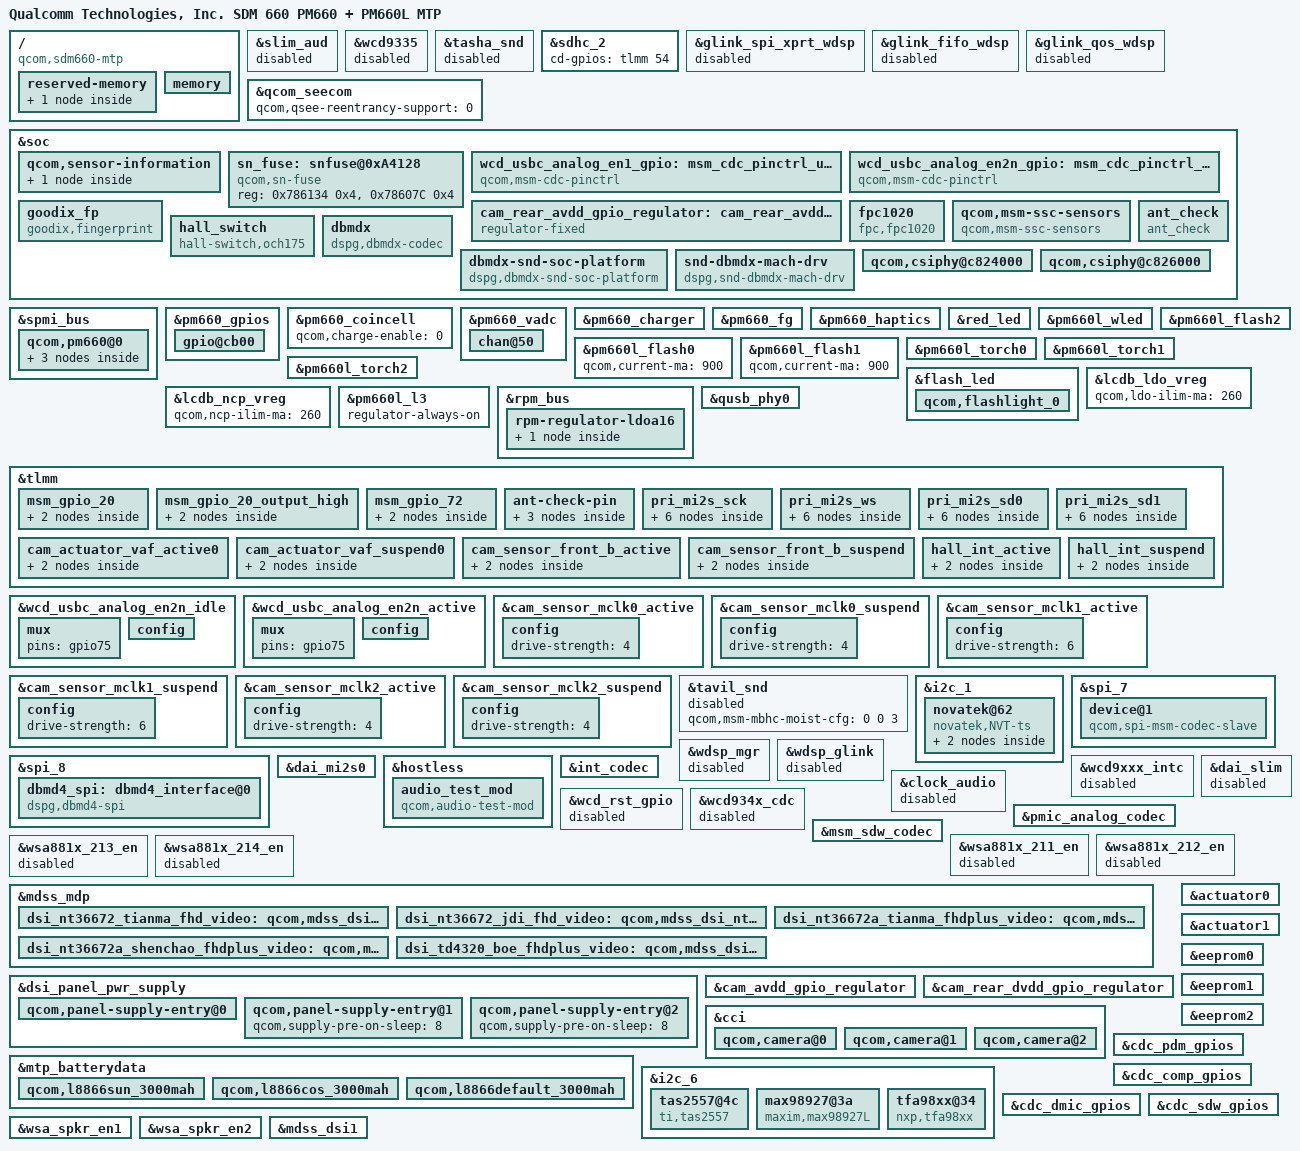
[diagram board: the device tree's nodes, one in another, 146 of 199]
/dts-v1/;

#include "sdm660.dtsi"
#include "sdm660-mtp.dtsi"
#include "sdm660-external-codec.dtsi"

/ {
	model = "Qualcomm Technologies, Inc. SDM 660 PM660 + PM660L MTP";
	compatible = "qcom,sdm660-mtp", "qcom,sdm660", "qcom,mtp";
	qcom,board-id = <8 0>;
	qcom,pmic-id = <0x0001001b 0x0101011a 0x0 0x0>,
			<0x0001001b 0x0201011a 0x0 0x0>,
			<0x0001001b 0x0102001a 0x0 0x0>;
	reserved-memory {
		pstore_reserve_mem: pstore_reserve_mem_region@0 {
			linux,reserve-contiguous-region;
			linux,reserve-region;
			linux,remove-completely;
			reg = <0x0 0xA0000000 0x0 0x00400000>;
			label = "pstore_reserve_mem";
		};
	};
	memory {
		device_type = "memory";
		reg = <0 0x80000000 0 0x80000000 1 0 0 0x7e4c0000>;
	};
};
&slim_aud {
	status = "disabled";
};
&wcd9335 {
	status = "disabled";
};
&tasha_snd {
	status = "disabled";
};
&sdhc_2 {
	cd-gpios = <&tlmm 54 0x0>;
};
&glink_spi_xprt_wdsp {
	status = "disabled";
};
&glink_fifo_wdsp {
	status = "disabled";
};
&glink_qos_wdsp {
	status = "disabled";
};
&qcom_seecom {
	qcom,qsee-reentrancy-support = <0>;
};
&soc {
	qcom,sensor-information {
		sensor_information22: qcom,sensor-information-22 {
			qcom,sensor-type = "adc";
			qcom,sensor-name = "backlight_therm";
		};
	};
	sn_fuse: snfuse@0xA4128 {
		compatible = "qcom,sn-fuse";
		reg = <0x786134 0x4>, <0x78607C 0x4>;
		reg-names = "sn-base","fuse-state";
	};
	wcd_usbc_analog_en1_gpio: msm_cdc_pinctrl_usbc_audio_en1 {
		compatible = "qcom,msm-cdc-pinctrl";
		pinctrl-names = "aud_active", "aud_sleep";
		pinctrl-0 = <&wcd_usbc_analog_en1_active>;
		pinctrl-1 = <&wcd_usbc_analog_en1_idle>;
	};
	wcd_usbc_analog_en2n_gpio: msm_cdc_pinctrl_usbc_audio_en2 {
		compatible = "qcom,msm-cdc-pinctrl";
		pinctrl-names = "aud_active", "aud_sleep";
		pinctrl-0 = <&wcd_usbc_analog_en2n_active>;
		pinctrl-1 = <&wcd_usbc_analog_en2n_idle>;
	};
	cam_rear_avdd_gpio_regulator: cam_rear_avdd_fixed_regulator {
		compatible = "regulator-fixed";
		regulator-name = "cam_rear_avdd_gpio_regulator";
		regulator-min-microvolt = <2800000>;
		regulator-max-microvolt = <2800000>;
		enable-active-high;
		gpio = <&tlmm 46 0>;
		vin-supply = <&pm660l_bob>;
	};
	goodix_fp {
		compatible = "goodix,fingerprint";
		interrupt-parent = <&tlmm>;
		interrupt = <72 0x0>;
		vcc_spi-supply = <&pm660l_l3>;
		vcc_ana-supply = <&pm660l_l3>;
		vdd_io-supply = <&pm660l_l3>;
		fp-gpio-irq = <&tlmm 72 0x00>;
		fp-gpio-reset = <&tlmm 20 0x00>;
		status = "okay";
	};
	fpc1020 {
		status = "ok";
		compatible = "fpc,fpc1020";
		interrupt-parent = <&tlmm>;
		interrupts = <72 0x0>;
		fpc,gpio_rst = <&tlmm 20 0x0>;
		fpc,gpio_irq = <&tlmm 72 0x0>;
		vcc_spi-supply = <&pm660_l13>;
		vdd_io-supply = <&pm660_l13>;
		vdd_ana-supply = <&pm660_l13>;
		pinctrl-names = "fpc1020_reset_reset", "fpc1020_reset_active", "fpc1020_irq_active";
		pinctrl-0 = <&msm_gpio_20>;
		pinctrl-1 = <&msm_gpio_20_output_high>;
		pinctrl-2 = <&msm_gpio_72>;
	};
	qcom,msm-ssc-sensors {
		compatible = "qcom,msm-ssc-sensors";
	};
	ant_check {
		compatible = "ant_check";
		ant_check_gpio = <&tlmm 74 0x0>;
		pinctrl-names = "default";
		pinctrl-0 = <&ant_check_default>;
	};
	hall_switch {
		compatible = "hall-switch,och175";
		pinctrl-names = "hall_active","hall_suspend";
		pinctrl-0 = <&hall_int_active>;
		pinctrl-1 = <&hall_int_suspend>;
		vdd-io-supply = <&pm660_l8>;
		interrupt-names = "hall_irq";
		hall,irq-gpio = <&tlmm 76 0x0>;
	};
	dbmdx {
		compatible = "dspg,dbmdx-codec";
		status = "okay";
		sv-gpio = <&tlmm 65 0>;
		wakeup-gpio = <&tlmm 0 0>;
		reset-gpio = <&tlmm 63 0>;		
		auto_buffering = <1>;
		multi-interface-support = <1>;
		cd-interfaces = <&dbmd4_spi >;
		va-interfaces = <0 0 0 0>;
		feature-va;
		va-firmware-name = "dbmd4_va_fw.bin";
		va-config = <0x80000000 0x80000000 0x80290020 0x80330019 0x802210e4 0x80158E8E 0x801b0020 0x80230001 0x801A0017 0x80103015 0x80000000 0x80000000 0x80000000>;
		va-speeds = <0x0000 460800 0 960000 0x0000 2000000 0 4800000 0x0000 3000000 0 4800000>;
		va-mic-config = <0xf041 0x1044 0x0008>;
		va-mic-mode = <4>;
		master-clk-rate = <32768>;
		firmware_id = <0xdbd4>;
		use_gpio_for_wakeup = <1>;
		wakeup_set_value = <0>;
		auto_detection = <1>;
		detection_buffer_channels = <0>;
		min_samples_chunk_size = <128>;
		pcm_streaming_mode = <1>;
		boot_options = <0x200>;
		amodel_options = <0x4>;
		send_uevent_on_detection = <1>;
		send_uevent_after_buffering = <0>;
		detection_after_buffering = <0>;
		va_backlog_length = <0x7d0>;
	};
	dbmdx-snd-soc-platform {
		compatible = "dspg,dbmdx-snd-soc-platform";
	};
	snd-dbmdx-mach-drv {
		compatible = "dspg,snd-dbmdx-mach-drv";
	};
	/delete-node/ qcom,qbt1000;
	/delete-node/ cam_actuator_fixed_regulator;
};
&spmi_bus {
	qcom,pm660@0 {
		qcom,power-on@800 {
			qcom,pon_1 {
				qcom,support-reset = <1>;
				qcom,s1-timer = <4480>;
				qcom,s2-timer = <2000>;
				qcom,s2-type = <7>;
			};
		};
	};
};
&spmi_bus {
	qcom,pm660@0 {
		qcom,power-on@800 {
			qcom,pon_3 {
				qcom,pon-type = <3>;
				qcom,pull-up = <1>;
				qcom,support-reset = <1>;
				qcom,s1-timer = <4480>;
				qcom,s2-timer = <1000>;
				qcom,s2-type = <1>;
			};
		};
	};
};
&pm660_gpios {
	gpio@cb00 {
		status = "ok";
		qcom,mode = <1>;
		qcom,pull = <5>;
		qcom,vin-sel = <0>;
		qcom,src-sel = <2>;
		qcom,invert = <0>;
		qcom,master-en = <1>;
	};
};
&pm660_coincell {
	qcom,charge-enable = <0>;
};
&pm660_vadc {
	chan@50 {
		label = "backlight_therm";
		reg = <0x50>;
		qcom,decimation = <2>;
		qcom,pre-div-channel-scaling = <0>;
		qcom,calibration-type = "ratiometric";
		qcom,scale-function = <2>;
		qcom,hw-settle-time = <2>;
		qcom,fast-avg-setup = <0>;
		qcom,vadc-thermal-node;
	};
};
&pm660_charger {
	qcom,usb-icl-ua = <2900000>;
	qcom,otg-cl-ua = <1500000>;
	qcom,dc-icl-ua = <2900000>;
	qcom,fcc-max-ua = <2900000>;
	qcom,fv-max-uv = <4400000>;
	qcom,sw-jeita-enable;
	qcom,thermal-mitigation = <2900000 2000000 1800000 1500000 1000000 500000 100000>;
};
&pm660_fg {
	qcom,fg-cutoff-voltage = <3400>;
	qcom,fg-chg-term-current = <200>;
	qcom,fg-sys-term-current = <300>;
	qcom,fg-recharge-voltage = <4340>;
	qcom,fg-jeita-thresholds = <0 15 45 60>;
	qcom,fg-jeita-hyst-temp = <0>;
};
&pm660_haptics {
	qcom,play-mode = "buffer";
	qcom,vmax-mv = <2204>;
	qcom,wave-shape = "sine";
	qcom,wave-play-rate-us = <4878>;
	qcom,int-pwm-freq-khz = <253>;
	qcom,brake-pattern = [02 02 01 00];
	qcom,wave-samples = [3e 3e 3e 00 00 00 00 00];
	qcom,wave-samples-two = [3e 3e 3e 3e 00 00 00 00];
	qcom,wave-samples-three = [3e 3e 3e 3e 3e 00 00 00];
	qcom,wave-rep-cnt = <1>;
	qcom,wave-samp-rep-cnt = <1>;
	qcom,lra-high-z = "opt1";
	qcom,lra-auto-res-mode = "none";
	qcom,lra-hw-auto-resonance;
	/delete-property/ qcom,correct-lra-drive-freq;
};
&red_led {
	qcom,ramp-step-ms = <128>;
	qcom,idx-len = <26>;
	qcom,duty-pcts = [3c 3c 3b 3a 3b 37 35 33 31 2e 2a 27 23 1f 1b 17 13 0e 09 05 00 00 00 00 00 00];
};
&pm660l_wled {
	qcom,fs-curr-ua = <20000>;
	qcom,led-strings-list = [00 01];
	qcom,en-cabc;
	/delete-property/ qcom,auto-calibration-enable;
};
&pm660l_flash0 {
	qcom,current-ma = <900>;
};
&pm660l_flash1 {
	qcom,current-ma = <900>;
};
&pm660l_flash2 {
	qcom,max-current = <100>;
	qcom,current-ma = <90>;
};
&pm660l_torch0 {
	qcom,max-current = <1000>;
	qcom,current-ma = <100>;
};
&pm660l_torch1 {
	qcom,max-current = <1000>;
	qcom,current-ma = <100>;
};
&pm660l_torch2 {
	qcom,max-current = <150>;
	qcom,current-ma = <90>;
};
&flash_led {
	qcom,flashlight_0 {
		label = "flashlight";
		qcom,led-name = "flashlight";
		qcom,torch-name = "led:torch_0", "led:torch_1";
		qcom,switch-name = "led:switch_0";
		qcom,id = <0>;
	};
};
&lcdb_ldo_vreg {
	qcom,ldo-ilim-ma = <260>;
};
&lcdb_ncp_vreg {
	qcom,ncp-ilim-ma = <260>;
};
&pm660l_l3 {
	regulator-always-on;
};
&rpm_bus {
	rpm-regulator-ldoa16 {
		status = "okay";
		pm660_l16: regulator-l16 {
			regulator-min-microvolt = <2800000>;
			regulator-max-microvolt = <2800000>;
			status = "okay";
			regulator-always-on;
		};
	};
};
&qusb_phy0 {
	qcom,qusb-phy-init-seq = <0xf8 0x80 0x33 0x84 0x83 0x88 0xc0 0x8c 0x30 0x08 0x79 0x0c 0x21 0x10 0x14 0x9c 0x9f 0x1c 0x00 0x18>;
};
&tlmm {
	msm_gpio_20: msm_gpio_20 {
		mux {
			pins = "gpio20";
			function = "gpio";
		};
		config {
			pins = "gpio20";
			drive-strength = <2>;
			bias-disable;
			output-low;
		};
	};
	msm_gpio_20_output_high: msm_gpio_20_output_high {
		mux {
			pins = "gpio20";
			function = "gpio";
		};
		config {
			pins = "gpio20";
			drive-strength = <2>;
			bias-disable;
			output-high;
		};
	};
	msm_gpio_72: msm_gpio_72 {
		mux {
			pins = "gpio72";
			function = "gpio";
		};
		config {
			pins = "gpio72";
			drive-strength = <2>;
			bias-pull-down;
		};
	};
	ant-check-pin {
		ant_check_default: ant_check_default {
			mux {
				pins = "gpio74";
				function = "gpio";
			};
			config {
				pins = "gpio74";
				drive-strength = <2>;
				bias-disable;
				input-enable;
				input-debounce = <5000>;
			};
		};
	};
	pri_mi2s_sck {
		pri_mi2s_sck_sleep: pri_mi2s_sck_sleep {
			mux {
				pins = "gpio12";
				function = "gpio";
			};
			config {
				pins = "gpio12";
				drive-strength = <2>;
				bias-pull-down;
				input-enable;
			};
		};
		pri_mi2s_sck_active: pri_mi2s_sck_active {
			mux {
				pins = "gpio12";
				function = "pri_mi2s";
			};
			config {
				pins = "gpio12";
				drive-strength = <8>;
				bias-disable;
				output-high;
			};
		};
	};
	pri_mi2s_ws {
		pri_mi2s_ws_sleep: pri_mi2s_ws_sleep {
			mux {
				pins = "gpio13";
				function = "gpio";
			};
			config {
				pins = "gpio13";
				drive-strength = <2>;
				bias-pull-down;
				input-enable;
			};
		};
		pri_mi2s_ws_active: pri_mi2s_ws_active {
			mux {
				pins = "gpio13";
				function = "pri_mi2s_ws";
			};
			config {
				pins = "gpio13";
				drive-strength = <8>;
				bias-disable;
				output-high;
			};
		};
	};
	pri_mi2s_sd0 {
		pri_mi2s_sd0_sleep: pri_mi2s_sd0_sleep {
			mux {
				pins = "gpio14";
				function = "gpio";
			};
			config {
				pins = "gpio14";
				drive-strength = <2>;
				bias-pull-down;
				input-enable;
			};
		};
		pri_mi2s_sd0_active: pri_mi2s_sd0_active {
			mux {
				pins = "gpio14";
				function = "pri_mi2s";
			};
			config {
				pins = "gpio14";
				drive-strength = <8>;
				bias-disable;
			};
		};
	};
	pri_mi2s_sd1 {
		pri_mi2s_sd1_sleep: pri_mi2s_sd1_sleep {
			mux {
				pins = "gpio15";
				function = "gpio";
			};
			config {
				pins = "gpio15";
				drive-strength = <2>;
				bias-pull-down;
				input-enable;
			};
		};
		pri_mi2s_sd1_active: pri_mi2s_sd1_active {
			mux {
				pins = "gpio15";
				function = "pri_mi2s";
			};
			config {
				pins = "gpio15";
				drive-strength = <8>;
				bias-disable;
			};
		};
	};
	cam_actuator_vaf_active0: cam_actuator_vaf_active0 {
		mux {
			pins = "gpio45";
			function = "gpio";
		};
		config {
			pins = "gpio45";
			bias-disable;
			drive-strength = <2>;
		};
	};
	cam_actuator_vaf_suspend0: cam_actuator_vaf_suspend0 {
		mux {
			pins = "gpio45";
			function = "gpio";
		};
		config {
			pins = "gpio45";
			bias-pull-down;
			drive-strength = <2>;
		};
	};
	cam_sensor_front_b_active: cam_sensor_front_b_active {
		mux {
			pins = "gpio52","gpio40";
			function = "gpio";
		};
		config {
			pins = "gpio52","gpio40";
			bias-disable;
			drive-strength = <2>;
		};
	};
	cam_sensor_front_b_suspend: cam_sensor_front_b_suspend {
		mux {
			pins = "gpio52","gpio40";
			function = "gpio";
		};
		config {
			pins = "gpio52","gpio40";
			bias-disable;
			drive-strength = <2>;
		};
	};
	hall_int_active: hall_int_active {
		mux {
			pins = "gpio76";
			function = "gpio";
		};
		config {
			pins = "gpio76";
			drive-strength = <6>;
			bias-pull-up;
		};
	};
	hall_int_suspend: hall_int_suspend {
		mux {
			pins = "gpio76";
			function = "gpio";
		};
		config {
			pins = "gpio76";
			drive-strength = <6>;
			bias-pull-up;
		};
	};
};
&wcd_usbc_analog_en2n_idle {
	mux {
		pins = "gpio75";
	};
};
&wcd_usbc_analog_en2n_idle {
	config {
		pins = "gpio75";
		output-low;
		/delete-property/ output-high;
	};
};
&wcd_usbc_analog_en2n_active {
	mux {
		pins = "gpio75";
	};
};
&wcd_usbc_analog_en2n_active {
	config {
		pins = "gpio75";
		bias-disable;
		output-high;
		/delete-property/ bias-pull-down;
		/delete-property/ output-low;
	};
};
&cam_sensor_mclk0_active {
	config {
		drive-strength = <4>;
	};
};
&cam_sensor_mclk0_suspend {
	config {
		drive-strength = <4>;
	};
};
&cam_sensor_mclk1_active {
	config {
		drive-strength = <6>;
	};
};
&cam_sensor_mclk1_suspend {
	config {
		drive-strength = <6>;
	};
};
&cam_sensor_mclk2_active {
	config {
		drive-strength = <4>;
	};
};
&cam_sensor_mclk2_suspend {
	config {
		drive-strength = <4>;
	};
};
&tavil_snd {
	qcom,msm-mbhc-moist-cfg = <0 0 3>;
};
&i2c_1 {
	status = "ok";
	novatek@62 {
		compatible = "novatek,NVT-ts";
		reg = <0x62>;
		interrupt-parent = <&tlmm>;
		interrupts = <67 0x2008>;
		vcc_i2c-supply = <&pm660_l11>;
		pinctrl-names = "pmx_ts_active", "pmx_ts_suspend";
		pinctrl-0 = <&ts_active>;
		pinctrl-1 = <&ts_int_suspend &ts_reset_suspend>;
		novatek,reset-gpio = <&tlmm 66 0x00>;
		novatek,irq-gpio = <&tlmm 67 0x2001>;
		novatek,mp-support-dt;
		novatek-mp-criteria-5906@0 {
			#address-cells = <1>;
			#size-cells = <0>;
			compatible = "novatek-mp-criteria-5906";
			IC_X_CFG_SIZE = <18>;
			IC_Y_CFG_SIZE = <32>;
			IC_KEY_CFG_SIZE = <4>;
			X_Channel = <18>;
			Y_Channel = <32>;
			AIN_X = <17 16 15 14 13 12 11 10 9 8 7 6 5 4 3 2 1 0>;
			AIN_Y = <31 30 29 28 27 26 25 24 23 22 21 20 19 18 17 16 15 14 13 12 11 10 9 8 7 6 5 4 3 2 1 0>;
			AIN_KEY = <0 1 2 0xFF>;
			PS_Config_Lmt_Short_Rawdata_P = <14000>;
			PS_Config_Lmt_Short_Rawdata_N = <11000>;
			PS_Config_Lmt_Key_Short_Rawdata_P = <14000>;
			PS_Config_Lmt_Key_Short_Rawdata_N = <11000>;
			PS_Config_Lmt_Short_Diff_P = <6300>;
			PS_Config_Lmt_Short_Diff_N = <0>;
			PS_Config_Lmt_Key_Short_Diff_P = <6300>;
			PS_Config_Lmt_Key_Short_Diff_N = <0>;
			PS_Config_Lmt_Short_Base_P = <2000>;
			PS_Config_Lmt_Short_Base_N = <(-2000)>;
			PS_Config_Lmt_Key_Short_Base_P = <2000>;
			PS_Config_Lmt_Key_Short_Base_N = <(-2000)>;
			PS_Config_Lmt_Open_Rawdata_P = < 7345 7376 7389 7403 7418 7442 7453 7432 7406 7365 7395 7412 7435 7452 7435 7420 7406 7392 7342 7378 7393 7407 7425 7450 7458 7436 7407 7365 7393 7412 7437 7450 7433 7418 7402 7380 7331 7365 7379 7394 7411 7438 7442 7420 7392 7377 7405 7425 7451 7462 7445 7428 7412 7387 7333 7371 7387 7402 7420 7446 7448 7426 7397 7362 7389 7408 7434 7444 7425 7409 7393 7367 7346 7385 7404 7420 7438 7464 7465 7442 7413 7379 7406 7427 7453 7459 7441 7425 7408 7376 7334 7370 7390 7405 7423 7451 7447 7425 7395 7389 7417 7438 7466 7469 7450 7434 7417 7382 7343 7380 7404 7420 7438 7466 7460 7437 7407 7381 7408 7429 7455 7458 7438 7422 7403 7367 7351 7387 7413 7429 7448 7477 7467 7444 7413 7384 7412 7433 7460 7458 7440 7424 7403 7366 7343 7377 7407 7424 7442 7470 7459 7435 7406 7408 7437 7459 7488 7483 7464 7447 7420 7381 7351 7386 7417 7437 7456 7486 7470 7446 7416 7394 7423 7443 7472 7467 7446 7429 7399 7363 7360 7396 7429 7452 7470 7502 7483 7459 7427 7412 7441 7464 7493 7482 7463 7444 7412 7374 7348 7384 7416 7440 7460 7489 7466 7444 7413 7422 7453 7475 7506 7492 7473 7450 7416 7378 7358 7396 7428 7458 7478 7509 7484 7459 7428 7417 7447 7470 7500 7486 7464 7437 7404 7366 7372 7410 7443 7477 7497 7528 7500 7474 7441 7428 7459 7483 7515 7495 7474 7443 7410 7371 7359 7397 7430 7463 7489 7515 7486 7461 7429 7451 7484 7509 7542 7517 7494 7459 7425 7385 7373 7411 7445 7480 7507 7534 7503 7477 7443 7440 7472 7497 7530 7505 7476 7442 7408 7369 7387 7427 7462 7499 7530 7556 7524 7496 7461 7462 7495 7522 7554 7525 7493 7457 7422 7381 7369 7407 7441 7476 7516 7553 7525 7497 7462 7493 7530 7559 7582 7533 7495 7459 7423 7382 7385 7425 7461 7497 7538 7574 7550 7520 7483 7493 7530 7559 7576 7529 7488 7452 7417 7375 7403 7445 7482 7522 7564 7599 7577 7544 7505 7514 7553 7585 7594 7543 7502 7464 7427 7384 7400 7441 7478 7517 7562 7591 7572 7540 7502 7548 7590 7621 7627 7573 7531 7489 7450 7406 7421 7464 7504 7546 7592 7621 7600 7569 7526 7545 7587 7613 7615 7564 7519 7479 7440 7395 7444 7490 7531 7575 7623 7650 7630 7598 7553 7577 7621 7647 7646 7589 7544 7502 7461 7413 7442 7489 7531 7575 7626 7647 7626 7598 7553 7615 7664 7686 7682 7621 7572 7527 7485 7435 7469 7518 7563 7611 7664 7684 7661 7636 7587 7624 7668 7690 7681 7620 7570 7525 7483 7432 7501 7554 7602 7653 7711 7729 7702 7678 7625 7664 7706 7731 7717 7653 7599 7552 7507 7452 7496 7549 7597 7650 7710 7721 7694 7671 7622 7714 7756 7784 7764 7694 7637 7586 7538 7479 7325 7362 7392 7425 7461 7466 7454 7445 7416 7453 7471 7481 7460 7418 7384 7354 7325 7285 7379 7422 7458 7497 7541 7545 7529 7516 7485 7527 7549 7564 7540 7490 7450 7414 7380 7334 7419 7467 7508 7552 7604 7604 7583 7568 7537 7612 7641 7662 7633 7573 7526 7483 7444 7391 7492 7549 7597 7652 7714 7714 7686 7665 7630 7678 7712 7738 7706 7636 7582 7534 7490 7432 7652 7728 7798 7877 7968 7965 7917 7879 7823 7890 7941 7985 7944 7848 7770 7702 7641 7558>;
			PS_Config_Lmt_Open_Rawdata_N = < 6834 6852 6860 6867 6876 6890 6896 6884 6869 6846 6863 6873 6886 6896 6886 6878 6869 6861 6833 6853 6862 6870 6880 6895 6900 6887 6870 6846 6862 6873 6887 6895 6885 6876 6867 6854 6826 6846 6854 6863 6872 6888 6890 6878 6861 6853 6869 6880 6895 6902 6892 6882 6873 6858 6828 6849 6858 6867 6877 6892 6894 6881 6864 6844 6860 6871 6885 6891 6880 6871 6862 6847 6835 6858 6868 6878 6888 6903 6903 6890 6873 6854 6870 6881 6897 6900 6890 6880 6870 6852 6828 6848 6860 6869 6879 6895 6893 6880 6863 6859 6876 6888 6904 6905 6895 6886 6875 6855 6833 6854 6868 6878 6888 6904 6900 6887 6870 6855 6871 6882 6898 6899 6888 6879 6868 6847 6838 6858 6874 6883 6894 6910 6905 6891 6874 6857 6873 6885 6901 6899 6889 6880 6868 6847 6833 6853 6870 6880 6890 6906 6900 6886 6869 6871 6887 6900 6916 6913 6903 6893 6877 6855 6838 6858 6876 6887 6898 6915 6906 6892 6875 6863 6879 6891 6907 6904 6892 6883 6866 6845 6843 6864 6882 6896 6906 6924 6914 6900 6882 6873 6890 6902 6919 6913 6902 6891 6873 6851 6836 6857 6875 6889 6901 6917 6904 6891 6874 6879 6896 6909 6927 6919 6908 6895 6875 6853 6842 6863 6882 6899 6911 6929 6914 6900 6882 6876 6893 6906 6924 6915 6903 6887 6868 6847 6850 6872 6891 6910 6921 6939 6923 6909 6890 6882 6900 6914 6932 6921 6909 6891 6871 6849 6843 6864 6883 6902 6917 6932 6916 6901 6883 6895 6914 6929 6948 6933 6920 6900 6880 6857 6850 6872 6892 6912 6928 6943 6925 6910 6891 6889 6907 6922 6941 6926 6910 6890 6871 6848 6859 6882 6902 6923 6941 6955 6937 6921 6901 6901 6921 6936 6955 6938 6920 6899 6879 6855 6848 6870 6889 6910 6933 6954 6938 6922 6902 6919 6940 6957 6971 6943 6920 6900 6879 6855 6858 6880 6901 6922 6945 6966 6952 6935 6914 6920 6941 6958 6967 6940 6917 6896 6875 6852 6868 6892 6913 6936 6960 6981 6967 6949 6926 6931 6954 6972 6978 6948 6925 6903 6882 6857 6866 6890 6911 6933 6959 6976 6965 6947 6925 6951 6975 6993 6997 6965 6941 6917 6895 6869 6878 6903 6926 6950 6976 6993 6981 6963 6939 6949 6974 6988 6990 6960 6934 6912 6889 6863 6891 6917 6941 6967 6994 7010 6998 6980 6954 6967 6993 7008 7007 6975 6949 6924 6901 6873 6890 6917 6941 6966 6996 7008 6996 6980 6954 6990 7017 7030 7028 6993 6965 6939 6915 6886 6905 6934 6959 6987 7018 7029 7016 7002 6974 6995 7020 7033 7027 6992 6964 6938 6914 6884 6924 6954 6982 7012 7045 7055 7039 7026 6995 7018 7042 7056 7048 7011 6981 6953 6927 6896 6921 6952 6979 7009 7044 7050 7035 7022 6994 7046 7070 7087 7075 7035 7002 6973 6945 6911 6823 6844 6862 6880 6901 6904 6897 6892 6875 6896 6907 6912 6900 6876 6857 6840 6823 6800 6854 6879 6899 6922 6947 6949 6940 6932 6915 6939 6952 6960 6946 6918 6895 6874 6855 6828 6877 6905 6928 6953 6983 6983 6971 6962 6944 6988 7005 7016 7000 6965 6938 6914 6891 6861 6919 6951 6979 7011 7046 7046 7031 7018 6998 7026 7045 7060 7042 7002 6971 6943 6917 6884 7011 7055 7095 7140 7192 7191 7163 7141 7109 7148 7177 7202 7178 7123 7079 7040 7004 6957>;
			PS_Config_Lmt_FW_Rawdata_P = < 1300 1300 1300 1300 1300 1300 1300 1300 1300 1300 1300 1300 1300 1300 1300 1300 1300 1300 1300 1300 1300 1300 1300 1300 1300 1300 1300 1300 1300 1300 1300 1300 1300 1300 1300 1300 1300 1300 1300 1300 1300 1300 1300 1300 1300 1300 1300 1300 1300 1300 1300 1300 1300 1300 1300 1300 1300 1300 1300 1300 1300 1300 1300 1300 1300 1300 1300 1300 1300 1300 1300 1300 1300 1300 1300 1300 1300 1300 1300 1300 1300 1300 1300 1300 1300 1300 1300 1300 1300 1300 1300 1300 1300 1300 1300 1300 1300 1300 1300 1300 1300 1300 1300 1300 1300 1300 1300 1300 1300 1300 1300 1300 1300 1300 1300 1300 1300 1300 1300 1300 1300 1300 1300 1300 1300 1300 1300 1300 1300 1300 1300 1300 1300 1300 1300 1300 1300 1300 1300 1300 1300 1300 1300 1300 1300 1300 1300 1300 1300 1300 1300 1300 1300 1300 1300 1300 1300 1300 1300 1300 1300 1300 1300 1300 1300 1300 1300 1300 1300 1300 1300 1300 1300 1300 1300 1300 1300 1300 1300 1300 1300 1300 1300 1300 1300 1300 1300 1300 1300 1300 1300 1300 1300 1300 1300 1300 1300 1300 1300 1300 1300 1300 1300 1300 1300 1300 1300 1300 1300 1300 1300 1300 1300 1300 1300 1300 1300 1300 1300 1300 1300 1300 1300 1300 1300 1300 1300 1300 1300 1300 1300 1300 1300 1300 1300 1300 1300 1300 1300 1300 1300 1300 1300 1300 1300 1300 1300 1300 1300 1300 1300 1300 1300 1300 1300 1300 1300 1300 1300 1300 1300 1300 1300 1300 1300 1300 1300 1300 1300 1300 1300 1300 1300 1300 1300 1300 1300 1300 1300 1300 1300 1300 1300 1300 1300 1300 1300 1300 1300 1300 1300 1300 1300 1300 1300 1300 1300 1300 1300 1300 1300 1300 1300 1300 1300 1300 1300 1300 1300 1300 1300 1300 1300 1300 1300 1300 1300 1300 1300 1300 1300 1300 1300 1300 1300 1300 1300 1300 1300 1300 1300 1300 1300 1300 1300 1300 1300 1300 1300 1300 1300 1300 1300 1300 1300 1300 1300 1300 1300 1300 1300 1300 1300 1300 1300 1300 1300 1300 1300 1300 1300 1300 1300 1300 1300 1300 1300 1300 1300 1300 1300 1300 1300 1300 1300 1300 1300 1300 1300 1300 1300 1300 1300 1300 1300 1300 1300 1300 1300 1300 1300 1300 1300 1300 1300 1300 1300 1300 1300 1300 1300 1300 1300 1300 1300 1300 1300 1300 1300 1300 1300 1300 1300 1300 1300 1300 1300 1300 1300 1300 1300 1300 1300 1300 1300 1300 1300 1300 1300 1300 1300 1300 1300 1300 1300 1300 1300 1300 1300 1300 1300 1300 1300 1300 1300 1300 1300 1300 1300 1300 1300 1300 1300 1300 1300 1300 1300 1300 1300 1300 1300 1300 1300 1300 1300 1300 1300 1300 1300 1300 1300 1300 1300 1300 1300 1300 1300 1300 1300 1300 1300 1300 1300 1300 1300 1300 1300 1300 1300 1300 1300 1300 1300 1300 1300 1300 1300 1300 1300 1300 1300 1300 1300 1300 1300 1300 1300 1300 1300 1300 1300 1300 1300 1300 1300 1300 1300 1300 1300 1300 1300 1300 1300 1300 1300 1300 1300 1300 1300 1300 1300 1300 1300 1300 1300 1300 1300 1300 1300 1300 1300 1300 1300 1300 1300 1300 1300 1300 1300 1300 1300 1300 1300 1300 1300 1300 1300 1300 1300 1300 1300 1300 1300 1300 1300 1300 1300 1300 1300 1300 1300 1300 1300 1300 1300 1300>;
			PS_Config_Lmt_FW_Rawdata_N = < 500 500 500 500 500 500 500 500 500 500 500 500 500 500 500 500 500 500 500 500 500 500 500 500 500 500 500 500 500 500 500 500 500 500 500 500 500 500 500 500 500 500 500 500 500 500 500 500 500 500 500 500 500 500 500 500 500 500 500 500 500 500 500 500 500 500 500 500 500 500 500 500 500 500 500 500 500 500 500 500 500 500 500 500 500 500 500 500 500 500 500 500 500 500 500 500 500 500 500 500 500 500 500 500 500 500 500 500 500 500 500 500 500 500 500 500 500 500 500 500 500 500 500 500 500 500 500 500 500 500 500 500 500 500 500 500 500 500 500 500 500 500 500 500 500 500 500 500 500 500 500 500 500 500 500 500 500 500 500 500 500 500 500 500 500 500 500 500 500 500 500 500 500 500 500 500 500 500 500 500 500 500 500 500 500 500 500 500 500 500 500 500 500 500 500 500 500 500 500 500 500 500 500 500 500 500 500 500 500 500 500 500 500 500 500 500 500 500 500 500 500 500 500 500 500 500 500 500 500 500 500 500 500 500 500 500 500 500 500 500 500 500 500 500 500 500 500 500 500 500 500 500 500 500 500 500 500 500 500 500 500 500 500 500 500 500 500 500 500 500 500 500 500 500 500 500 500 500 500 500 500 500 500 500 500 500 500 500 500 500 500 500 500 500 500 500 500 500 500 500 500 500 500 500 500 500 500 500 500 500 500 500 500 500 500 500 500 500 500 500 500 500 500 500 500 500 500 500 500 500 500 500 500 500 500 500 500 500 500 500 500 500 500 500 500 500 500 500 500 500 500 500 500 500 500 500 500 500 500 500 500 500 500 500 500 500 500 500 500 500 500 500 500 500 500 500 500 500 500 500 500 500 500 500 500 500 500 500 500 500 500 500 500 500 500 500 500 500 500 500 500 500 500 500 500 500 500 500 500 500 500 500 500 500 500 500 500 500 500 500 500 500 500 500 500 500 500 500 500 500 500 500 500 500 500 500 500 500 500 500 500 500 500 500 500 500 500 500 500 500 500 500 500 500 500 500 500 500 500 500 500 500 500 500 500 500 500 500 500 500 500 500 500 500 500 500 500 500 500 500 500 500 500 500 500 500 500 500 500 500 500 500 500 500 500 500 500 500 500 500 500 500 500 500 500 500 500 500 500 500 500 500 500 500 500 500 500 500 500 500 500 500 500 500 500 500 500 500 500 500 500 500 500 500 500 500 500 500 500 500 500 500 500 500 500 500 500 500 500 500 500 500 500 500 500 500 500 500 500 500 500 500 500 500 500 500 500 500 500 500 500 500 500 500 500 500>;
			PS_Config_Lmt_FW_CC_P = <132>;
			PS_Config_Lmt_FW_CC_N = <74>;
			PS_Config_Lmt_Key_FW_CC_P = <38>;
			PS_Config_Lmt_Key_FW_CC_N = <9>;
			PS_Config_Lmt_FW_CC_I_P = <25>;
			PS_Config_Lmt_FW_CC_I_N = <0>;
			PS_Config_Lmt_FW_CC_Q_P = <25>;
			PS_Config_Lmt_FW_CC_Q_N = <0>;
			PS_Config_Lmt_Key_FW_CC_I_P = <25>;
			PS_Config_Lmt_Key_FW_CC_I_N = <0>;
			PS_Config_Lmt_Key_FW_CC_Q_P = <25>;
			PS_Config_Lmt_Key_FW_CC_Q_N = <0>;
			PS_Config_Lmt_FW_Diff_P = <35>;
			PS_Config_Lmt_FW_Diff_N = <(-35)>;
			PS_Config_Lmt_Key_FW_Diff_P = <35>;
			PS_Config_Lmt_Key_FW_Diff_N = <(-35)>;
			PS_Config_Diff_Test_Frame = <50>;
		};
		novatek-mp-criteria-5909@1 {
			#address-cells = <1>;
			#size-cells = <0>;
			compatible = "novatek-mp-criteria-5909";
			IC_X_CFG_SIZE = <18>;
			IC_Y_CFG_SIZE = <32>;
			IC_KEY_CFG_SIZE = <4>;
			X_Channel = <18>;
			Y_Channel = <32>;
			AIN_X = <17 16 15 14 13 12 11 10 9 8 7 6 5 4 3 2 1 0>;
			AIN_Y = <31 30 29 28 27 26 25 24 23 22 21 20 19 18 17 16 15 14 13 12 11 10 9 8 7 6 5 4 3 2 1 0>;
			AIN_KEY = <0 1 2 0xFF>;
			PS_Config_Lmt_Short_Rawdata_P = <14000>;
			PS_Config_Lmt_Short_Rawdata_N = <11000>;
			PS_Config_Lmt_Key_Short_Rawdata_P = <14000>;
			PS_Config_Lmt_Key_Short_Rawdata_N = <11000>;
			PS_Config_Lmt_Short_Diff_P = <6300>;
			PS_Config_Lmt_Short_Diff_N = <0>;
			PS_Config_Lmt_Key_Short_Diff_P = <6300>;
			PS_Config_Lmt_Key_Short_Diff_N = <0>;
			PS_Config_Lmt_Short_Base_P = <2000>;
			PS_Config_Lmt_Short_Base_N = <(-2000)>;
			PS_Config_Lmt_Key_Short_Base_P = <2000>;
			PS_Config_Lmt_Key_Short_Base_N = <(-2000)>;
			PS_Config_Lmt_Open_Rawdata_P = < 9032 9105 9084 9055 9049 9011 9030 9044 9078 9024 9036 9019 8992 8985 8995 9014 9018 9045 8898 8951 8933 8904 8903 8864 8886 8896 8929 8874 8877 8863 8838 8831 8839 8854 8852 8871 8864 8894 8879 8855 8857 8834 8844 8853 8885 8810 8810 8796 8774 8766 8776 8785 8784 8803 8855 8896 8879 8858 8863 8834 8853 8864 8896 8848 8846 8834 8809 8812 8812 8817 8817 8818 8809 8857 8828 8809 8813 8783 8805 8816 8847 8794 8791 8779 8754 8750 8755 8760 8768 8756 8838 8875 8847 8830 8836 8816 8832 8842 8871 8806 8800 8792 8766 8761 8768 8768 8780 8769 8785 8823 8792 8781 8787 8766 8783 8796 8824 8775 8769 8758 8733 8741 8739 8738 8747 8736 8793 8817 8796 8784 8789 8771 8788 8801 8830 8783 8776 8764 8740 8739 8742 8741 8741 8736 8758 8775 8770 8748 8754 8739 8755 8766 8795 8725 8719 8708 8683 8680 8683 8695 8680 8680 8761 8775 8771 8749 8758 8743 8761 8774 8801 8758 8749 8737 8713 8722 8715 8727 8711 8713 8711 8722 8717 8697 8700 8692 8709 8721 8748 8696 8686 8676 8652 8654 8652 8664 8649 8649 8729 8734 8726 8712 8725 8709 8726 8739 8764 8702 8690 8678 8656 8655 8654 8662 8653 8653 8661 8665 8648 8652 8652 8645 8663 8675 8695 8657 8643 8635 8611 8625 8618 8612 8612 8612 8657 8661 8646 8654 8645 8641 8660 8671 8686 8650 8637 8627 8604 8608 8615 8603 8606 8601 8607 8609 8597 8605 8608 8591 8611 8622 8635 8586 8574 8565 8543 8544 8551 8535 8542 8536 8590 8592 8582 8591 8584 8580 8598 8609 8622 8592 8580 8569 8548 8563 8558 8543 8551 8544 8524 8530 8522 8519 8521 8521 8540 8550 8564 8521 8509 8498 8478 8485 8476 8475 8485 8478 8532 8536 8529 8527 8536 8537 8543 8553 8568 8522 8504 8493 8486 8478 8473 8473 8485 8476 8460 8465 8459 8459 8457 8457 8476 8486 8500 8477 8458 8449 8430 8445 8430 8429 8442 8433 8447 8453 8450 8449 8443 8446 8477 8476 8488 8458 8439 8441 8411 8418 8411 8412 8426 8412 8392 8396 8397 8398 8402 8394 8424 8423 8433 8392 8373 8374 8347 8352 8347 8348 8361 8345 8368 8374 8375 8376 8371 8373 8403 8401 8409 8391 8371 8375 8346 8362 8347 8351 8365 8345 8297 8305 8308 8309 8299 8304 8325 8333 8339 8315 8296 8290 8271 8281 8272 8278 8291 8267 8286 8297 8300 8302 8302 8295 8313 8336 8327 8297 8290 8269 8254 8264 8255 8260 8274 8248 8217 8229 8232 8235 8224 8227 8245 8268 8258 8243 8238 8214 8199 8210 8200 8209 8222 8195 8195 8208 8212 8213 8200 8206 8223 8247 8235 8218 8213 8190 8173 8186 8176 8187 8200 8170 8143 8157 8161 8161 8159 8153 8170 8189 8181 8150 8144 8124 8108 8119 8108 8121 8134 8100 8105 8119 8123 8121 8109 8114 8131 8142 8148 8137 8111 8100 8084 8095 8085 8100 8113 8076 8047 8060 8065 8060 8046 8053 8070 8081 8091 8076 8045 8033 8017 8027 8018 8034 8049 8008 8043 8056 8063 8054 8050 8047 8063 8075 8084 8060 8029 8017 7999 8011 8003 8021 8036 7990 7996 8010 8016 8004 7990 7996 8013 8025 8031 8021 7991 7978 7969 7972 7966 7985 8002 7955 8047 8060 8063 8047 8025 8039 8057 8070 8057 8047 8037 8022 8003 8016 8016 8037 8055 7985>;
			PS_Config_Lmt_Open_Rawdata_N = < 7699 7739 7727 7711 7708 7688 7698 7705 7724 7695 7701 7692 7677 7674 7679 7690 7691 7706 7627 7655 7646 7630 7630 7608 7620 7626 7643 7614 7615 7608 7595 7591 7595 7603 7602 7612 7609 7625 7617 7604 7605 7593 7598 7602 7620 7580 7580 7572 7560 7556 7561 7566 7566 7576 7604 7626 7617 7605 7608 7592 7603 7608 7626 7600 7599 7592 7579 7580 7581 7583 7583 7584 7579 7605 7589 7579 7581 7565 7577 7583 7599 7571 7569 7563 7549 7547 7550 7553 7557 7551 7595 7615 7599 7590 7594 7583 7591 7597 7612 7578 7574 7570 7556 7553 7557 7557 7564 7558 7566 7587 7570 7564 7567 7556 7565 7572 7587 7561 7558 7552 7538 7543 7541 7541 7546 7540 7570 7583 7572 7566 7568 7559 7568 7574 7590 7565 7561 7555 7542 7541 7543 7543 7542 7540 7552 7560 7558 7546 7550 7541 7550 7556 7572 7534 7531 7524 7511 7510 7511 7518 7509 7509 7553 7561 7558 7547 7551 7544 7553 7560 7575 7551 7546 7540 7527 7532 7529 7535 7526 7528 7526 7532 7530 7519 7520 7516 7525 7532 7546 7518 7513 7507 7495 7495 7494 7501 7493 7493 7536 7539 7534 7527 7534 7525 7534 7541 7555 7521 7515 7509 7496 7496 7495 7500 7495 7495 7499 7502 7492 7494 7494 7491 7500 7507 7518 7497 7490 7485 7472 7480 7476 7473 7473 7473 7497 7499 7491 7496 7491 7488 7499 7505 7513 7494 7487 7481 7469 7471 7475 7468 7470 7467 7470 7471 7465 7469 7471 7462 7472 7478 7485 7459 7452 7448 7436 7436 7440 7432 7435 7432 7461 7462 7457 7461 7458 7456 7466 7472 7478 7462 7456 7450 7438 7447 7444 7436 7440 7436 7426 7429 7424 7423 7424 7424 7434 7440 7447 7424 7417 7411 7401 7405 7400 7399 7404 7401 7430 7432 7428 7427 7432 7433 7436 7441 7449 7425 7415 7409 7405 7401 7398 7398 7404 7400 7391 7394 7390 7390 7390 7390 7400 7405 7413 7400 7390 7385 7375 7383 7375 7375 7381 7376 7384 7387 7386 7385 7382 7384 7400 7400 7406 7390 7380 7381 7365 7369 7365 7365 7373 7365 7355 7357 7357 7358 7360 7355 7372 7371 7377 7355 7344 7345 7330 7333 7330 7331 7338 7329 7342 7345 7345 7346 7343 7344 7360 7359 7364 7354 7343 7345 7330 7338 7330 7332 7340 7329 7303 7308 7309 7310 7305 7307 7318 7323 7326 7313 7303 7300 7289 7295 7290 7293 7300 7287 7297 7303 7305 7306 7306 7302 7312 7324 7319 7303 7300 7288 7280 7285 7281 7284 7291 7277 7260 7266 7268 7270 7264 7266 7275 7288 7282 7274 7271 7259 7250 7256 7251 7256 7263 7248 7248 7255 7258 7258 7251 7254 7263 7276 7270 7261 7258 7246 7237 7243 7238 7244 7251 7235 7220 7228 7230 7230 7229 7226 7235 7245 7241 7224 7221 7210 7201 7207 7201 7209 7216 7197 7200 7207 7210 7208 7202 7205 7214 7220 7223 7217 7203 7197 7189 7194 7189 7197 7204 7184 7169 7176 7179 7176 7168 7172 7181 7187 7192 7184 7167 7161 7152 7158 7153 7162 7170 7147 7167 7174 7177 7172 7170 7169 7177 7184 7189 7176 7159 7153 7143 7149 7145 7155 7163 7138 7141 7149 7152 7146 7138 7141 7150 7157 7160 7155 7138 7132 7127 7128 7125 7135 7145 7119 7168 7176 7178 7169 7157 7164 7174 7181 7174 7169 7163 7155 7145 7152 7152 7163 7173 7135>;
			PS_Config_Lmt_FW_Rawdata_P = < 1600 1600 1600 1600 1600 1600 1600 1600 1600 1600 1600 1600 1600 1600 1600 1600 1600 1600 1600 1600 1600 1600 1600 1600 1600 1600 1600 1600 1600 1600 1600 1600 1600 1600 1600 1600 1600 1600 1600 1600 1600 1600 1600 1600 1600 1600 1600 1600 1600 1600 1600 1600 1600 1600 1600 1600 1600 1600 1600 1600 1600 1600 1600 1600 1600 1600 1600 1600 1600 1600 1600 1600 1600 1600 1600 1600 1600 1600 1600 1600 1600 1600 1600 1600 1600 1600 1600 1600 1600 1600 1600 1600 1600 1600 1600 1600 1600 1600 1600 1600 1600 1600 1600 1600 1600 1600 1600 1600 1600 1600 1600 1600 1600 1600 1600 1600 1600 1600 1600 1600 1600 1600 1600 1600 1600 1600 1600 1600 1600 1600 1600 1600 1600 1600 1600 1600 1600 1600 1600 1600 1600 1600 1600 1600 1600 1600 1600 1600 1600 1600 1600 1600 1600 1600 1600 1600 1600 1600 1600 1600 1600 1600 1600 1600 1600 1600 1600 1600 1600 1600 1600 1600 1600 1600 1600 1600 1600 1600 1600 1600 1600 1600 1600 1600 1600 1600 1600 1600 1600 1600 1600 1600 1600 1600 1600 1600 1600 1600 1600 1600 1600 1600 1600 1600 1600 1600 1600 1600 1600 1600 1600 1600 1600 1600 1600 1600 1600 1600 1600 1600 1600 1600 1600 1600 1600 1600 1600 1600 1600 1600 1600 1600 1600 1600 1600 1600 1600 1600 1600 1600 1600 1600 1600 1600 1600 1600 1600 1600 1600 1600 1600 1600 1600 1600 1600 1600 1600 1600 1600 1600 1600 1600 1600 1600 1600 1600 1600 1600 1600 1600 1600 1600 1600 1600 1600 1600 1600 1600 1600 1600 1600 1600 1600 1600 1600 1600 1600 1600 1600 1600 1600 1600 1600 1600 1600 1600 1600 1600 1600 1600 1600 1600 1600 1600 1600 1600 1600 1600 1600 1600 1600 1600 1600 1600 1600 1600 1600 1600 1600 1600 1600 1600 1600 1600 1600 1600 1600 1600 1600 1600 1600 1600 1600 1600 1600 1600 1600 1600 1600 1600 1600 1600 1600 1600 1600 1600 1600 1600 1600 1600 1600 1600 1600 1600 1600 1600 1600 1600 1600 1600 1600 1600 1600 1600 1600 1600 1600 1600 1600 1600 1600 1600 1600 1600 1600 1600 1600 1600 1600 1600 1600 1600 1600 1600 1600 1600 1600 1600 1600 1600 1600 1600 1600 1600 1600 1600 1600 1600 1600 1600 1600 1600 1600 1600 1600 1600 1600 1600 1600 1600 1600 1600 1600 1600 1600 1600 1600 1600 1600 1600 1600 1600 1600 1600 1600 1600 1600 1600 1600 1600 1600 1600 1600 1600 1600 1600 1600 1600 1600 1600 1600 1600 1600 1600 1600 1600 1600 1600 1600 1600 1600 1600 1600 1600 1600 1600 1600 1600 1600 1600 1600 1600 1600 1600 1600 1600 1600 1600 1600 1600 1600 1600 1600 1600 1600 1600 1600 1600 1600 1600 1600 1600 1600 1600 1600 1600 1600 1600 1600 1600 1600 1600 1600 1600 1600 1600 1600 1600 1600 1600 1600 1600 1600 1600 1600 1600 1600 1600 1600 1600 1600 1600 1600 1600 1600 1600 1600 1600 1600 1600 1600 1600 1600 1600 1600 1600 1600 1600 1600 1600 1600 1600 1600 1600 1600 1600 1600 1600 1600 1600 1600 1600 1600 1600 1600 1600 1600 1600 1600 1600 1600 1600 1600 1600 1600 1600 1600 1600 1600 1600 1600 1600 1600 1600 1600 1600 1600 1600 1600 1600 1600 1600 1600 1600 1600 1600>;
			PS_Config_Lmt_FW_Rawdata_N = < 800 800 800 800 800 800 800 800 800 800 800 800 800 800 800 800 800 800 800 800 800 800 800 800 800 800 800 800 800 800 800 800 800 800 800 800 800 800 800 800 800 800 800 800 800 800 800 800 800 800 800 800 800 800 800 800 800 800 800 800 800 800 800 800 800 800 800 800 800 800 800 800 800 800 800 800 800 800 800 800 800 800 800 800 800 800 800 800 800 800 800 800 800 800 800 800 800 800 800 800 800 800 800 800 800 800 800 800 800 800 800 800 800 800 800 800 800 800 800 800 800 800 800 800 800 800 800 800 800 800 800 800 800 800 800 800 800 800 800 800 800 800 800 800 800 800 800 800 800 800 800 800 800 800 800 800 800 800 800 800 800 800 800 800 800 800 800 800 800 800 800 800 800 800 800 800 800 800 800 800 800 800 800 800 800 800 800 800 800 800 800 800 800 800 800 800 800 800 800 800 800 800 800 800 800 800 800 800 800 800 800 800 800 800 800 800 800 800 800 800 800 800 800 800 800 800 800 800 800 800 800 800 800 800 800 800 800 800 800 800 800 800 800 800 800 800 800 800 800 800 800 800 800 800 800 800 800 800 800 800 800 800 800 800 800 800 800 800 800 800 800 800 800 800 800 800 800 800 800 800 800 800 800 800 800 800 800 800 800 800 800 800 800 800 800 800 800 800 800 800 800 800 800 800 800 800 800 800 800 800 800 800 800 800 800 800 800 800 800 800 800 800 800 800 800 800 800 800 800 800 800 800 800 800 800 800 800 800 800 800 800 800 800 800 800 800 800 800 800 800 800 800 800 800 800 800 800 800 800 800 800 800 800 800 800 800 800 800 800 800 800 800 800 800 800 800 800 800 800 800 800 800 800 800 800 800 800 800 800 800 800 800 800 800 800 800 800 800 800 800 800 800 800 800 800 800 800 800 800 800 800 800 800 800 800 800 800 800 800 800 800 800 800 800 800 800 800 800 800 800 800 800 800 800 800 800 800 800 800 800 800 800 800 800 800 800 800 800 800 800 800 800 800 800 800 800 800 800 800 800 800 800 800 800 800 800 800 800 800 800 800 800 800 800 800 800 800 800 800 800 800 800 800 800 800 800 800 800 800 800 800 800 800 800 800 800 800 800 800 800 800 800 800 800 800 800 800 800 800 800 800 800 800 800 800 800 800 800 800 800 800 800 800 800 800 800 800 800 800 800 800 800 800 800 800 800 800 800 800 800 800 800 800 800 800 800 800 800 800 800 800 800 800 800 800 800 800 800 800 800 800 800 800 800 800 800 800 800 800 800 800 800 800 800 800 800>;
			PS_Config_Lmt_FW_CC_P = <118>;
			PS_Config_Lmt_FW_CC_N = <62>;
			PS_Config_Lmt_Key_FW_CC_P = <38>;
			PS_Config_Lmt_Key_FW_CC_N = <9>;
			PS_Config_Lmt_FW_CC_I_P = <25>;
			PS_Config_Lmt_FW_CC_I_N = <0>;
			PS_Config_Lmt_FW_CC_Q_P = <25>;
			PS_Config_Lmt_FW_CC_Q_N = <0>;
			PS_Config_Lmt_Key_FW_CC_I_P = <25>;
			PS_Config_Lmt_Key_FW_CC_I_N = <0>;
			PS_Config_Lmt_Key_FW_CC_Q_P = <25>;
			PS_Config_Lmt_Key_FW_CC_Q_N = <0>;
			PS_Config_Lmt_FW_Diff_P = <35>;
			PS_Config_Lmt_FW_Diff_N = <(-35)>;
			PS_Config_Lmt_Key_FW_Diff_P = <35>;
			PS_Config_Lmt_Key_FW_Diff_N = <(-35)>;
			PS_Config_Diff_Test_Frame = <50>;
		};
	};
};
&spi_7 {
	device@1 {
		compatible = "qcom,spi-msm-codec-slave";
		#address-cells = <1>;
		#size-cells = <1>;
		reg = <1>;
		spi-max-frequency = <1000000>;
		spi-cpol;
	};
};
&spi_8 {
	status = "ok";
	dbmd4_spi: dbmd4_interface@0 {
		compatible = "dspg,dbmd4-spi";
		reg = <0>;
		spi-max-frequency = <1000000>;
		read-chunk-size = <0x2000>;
		write-chunk-size = <0x20000>;
		dma_min_buffer_size = <0>;
	};
};
&soc {
	qcom,csiphy@c824000 {
		qcom,clock-rates = <0 0 0 0 0 0 310000000 0 0 269333333 0 0 269000000 0 0>;
	};
};
&soc {
	qcom,csiphy@c826000 {
		qcom,clock-rates = <0 0 0 0 0 0 310000000 0 0 269333333 0 0 269000000 0 0>;
	};
};
&wdsp_mgr {
	status = "disabled";
};
&wdsp_glink {
	status = "disabled";
};
&dai_mi2s0 {
	qcom,msm-mi2s-rx-lines = <1>;
	qcom,msm-mi2s-tx-lines = <2>;
};
&hostless {
	audio_test_mod {
		compatible = "qcom,audio-test-mod";
	};
};
&tavil_snd {
	status = "disabled";
	/delete-property/ qcom,usbc-analog-en1_gpio;
	/delete-property/ qcom,usbc-analog-en2_n_gpio;
};
&int_codec {
	status = "okay";
	qcom,msm-micbias1-ext-cap;
	pinctrl-names = "pri_i2s_active", "pri_i2s_sleep";
	pinctrl-0 = <&pri_mi2s_sck_active &pri_mi2s_ws_active &pri_mi2s_sd0_active &pri_mi2s_sd1_active>;
	pinctrl-1 = <&pri_mi2s_sck_sleep &pri_mi2s_ws_sleep &pri_mi2s_sd0_sleep &pri_mi2s_sd1_sleep>;
	qcom,wsa-disable;
	qcom,msm-mbhc-usbc-audio-supported = <1>;
	qcom,usbc-analog-en1_gpio = <&wcd_usbc_analog_en1_gpio>;
	qcom,usbc-analog-en2_n_gpio = <&wcd_usbc_analog_en2n_gpio>;
	/delete-property/ qcom,msm-micbias2-ext-cap;
	/delete-property/ qcom,us-euro-gpios;
};
&wcd9xxx_intc {
	status = "disabled";
};
&clock_audio {
	status = "disabled";
};
&wcd_rst_gpio {
	status = "disabled";
};
&wcd934x_cdc {
	status = "disabled";
	/delete-node/ msm_cdc_pinctrl_usbc_audio_en1;
	/delete-node/ msm_cdc_pinctrl_usbc_audio_en2;
};
&dai_slim {
	status = "disabled";
};
&pmic_analog_codec {
	status = "okay";
};
&msm_sdw_codec {
	status = "okay";
	/delete-property/ qcom,cdc-sdw-gpios;
};
&wsa881x_211_en {
	status = "disabled";
};
&wsa881x_212_en {
	status = "disabled";
};
&wsa881x_213_en {
	status = "disabled";
};
&wsa881x_214_en {
	status = "disabled";
};
&mdss_mdp {
	dsi_nt36672_tianma_fhd_video: qcom,mdss_dsi_nt36672_tianma_fhd_video {
		qcom,mdss-dsi-panel-name = "tianma nt36672 fhd video mode dsi panel";
		qcom,mdss-dsi-panel-controller = <&mdss_dsi0>;
		qcom,mdss-dsi-panel-type = "dsi_video_mode";
		qcom,mdss-dsi-panel-framerate = <60>;
		qcom,mdss-dsi-virtual-channel-id = <0>;
		qcom,mdss-dsi-stream = <0>;
		qcom,mdss-dsi-panel-width = <1080>;
		qcom,mdss-dsi-panel-height = <2160>;
		qcom,mdss-pan-physical-width-dimension = <68>;
		qcom,mdss-pan-physical-height-dimension = <136>;
		qcom,mdss-dsi-h-front-porch = <96>;
		qcom,mdss-dsi-h-back-porch = <56>;
		qcom,mdss-dsi-h-pulse-width = <4>;
		qcom,mdss-dsi-h-sync-skew = <0>;
		qcom,mdss-dsi-v-back-porch = <33>;
		qcom,mdss-dsi-v-front-porch = <4>;
		qcom,mdss-dsi-v-pulse-width = <2>;
		qcom,mdss-dsi-h-left-border = <0>;
		qcom,mdss-dsi-h-right-border = <0>;
		qcom,mdss-dsi-v-top-border = <0>;
		qcom,mdss-dsi-v-bottom-border = <0>;
		qcom,mdss-dsi-bpp = <24>;
		qcom,mdss-dsi-underflow-color = <0xff>;
		qcom,mdss-dsi-border-color = <0>;
		qcom,mdss-dsi-h-sync-pulse = <0>;
		qcom,mdss-dsi-traffic-mode = "burst_mode";
		qcom,mdss-dsi-bllp-eof-power-mode;
		qcom,mdss-dsi-bllp-power-mode;
		qcom,mdss-dsi-lane-0-state;
		qcom,mdss-dsi-lane-1-state;
		qcom,mdss-dsi-lane-2-state;
		qcom,mdss-dsi-lane-3-state;
		qcom,mdss-dsi-panel-timings = [e6 38 26 00 68 6e 2a 3c 44 03 04 00];
		qcom,mdss-dsi-t-clk-post = <0x0d>;
		qcom,mdss-dsi-t-clk-pre = <0x32>;
		qcom,mdss-dsi-bl-min-level = <1>;
		qcom,mdss-dsi-bl-max-level = <4095>;
		qcom,mdss-brightness-max-level = <4095>;
		qcom,mdss-dsi-dma-trigger = "trigger_sw";
		qcom,mdss-dsi-mdp-trigger = "none";
		qcom,mdss-dsi-on-command = [ 15 01 00 00 00 00 02 ff 20 15 01 00 00 00 00 02 fb 01 15 01 00 00 00 00 02 30 10 15 01 00 00 00 00 02 31 50 15 01 00 00 00 00 02 32 2f 15 01 00 00 00 00 02 ff 10 05 01 00 00 46 00 02 11 00 15 01 00 00 00 00 02 51 ff 39 01 00 00 00 00 03 68 03 04 15 01 00 00 00 00 02 53 2c 15 01 00 00 00 00 02 55 00 05 01 00 00 05 00 02 29 00 ];
		qcom,mdss-dsi-off-command = [ 05 01 00 00 14 00 02 28 00 05 01 00 00 78 00 02 10 00 ];
		qcom,mdss-dsi-ce-on-command = [ ];
		qcom,mdss-dsi-ce-off-command = [ ];
		qcom,mdss-dsi-srgb-on-command = [ ];
		qcom,mdss-dsi-srgb-off-command = [ ];
		qcom,mdss-dsi-cabc-on-command = [ 15 01 00 00 00 00 02 FF 23 15 00 00 00 00 00 02 07 20 15 00 00 00 00 00 02 08 05 15 00 00 00 00 00 02 09 00 15 00 00 00 00 00 02 10 95 15 00 00 00 00 00 02 30 FF 15 00 00 00 00 00 02 31 FF 15 00 00 00 00 00 02 32 FF 15 00 00 00 00 00 02 33 FF 15 00 00 00 00 00 02 34 FF 15 01 00 00 00 00 02 35 FF 15 00 00 00 00 00 02 36 FF 15 00 00 00 00 00 02 37 FF 15 00 00 00 00 00 02 38 FF 15 00 00 00 00 00 02 39 FF 15 00 00 00 00 00 02 3A FF 15 00 00 00 00 00 02 3B F9 15 00 00 00 00 00 02 3D D9 15 00 00 00 00 00 02 3F B9 15 00 00 00 00 00 02 40 AB 15 00 00 00 00 00 02 41 98 15 01 00 00 00 00 02 FF 10 15 01 00 00 00 00 02 55 01 ];
		qcom,mdss-dsi-cabc-off-command = [ 15 01 00 00 00 00 02 FF 10 15 01 00 00 00 00 02 55 00 ];
		qcom,mdss-dsi-gamma0-command = [15 00 00 00 00 00 02 ff 20 15 00 00 00 00 00 02 fb 01 39 00 00 00 00 00 11 b0 00 2b 00 3f 00 61 00 7e 00 97 00 ad 00 c1 00 d3 39 00 00 00 00 00 11 b1 00 e3 01 18 01 40 01 7b 01 a9 01 ef 02 26 02 28 39 00 00 00 00 00 11 b2 02 5e 02 9c 02 c4 02 f6 03 14 03 44 03 50 03 5d 39 00 00 00 00 00 0d b3 03 6e 03 80 03 99 03 ba 03 d5 03 d8 39 00 00 00 00 00 11 b4 00 00 00 20 00 49 00 6a 00 85 00 9e 00 b3 00 c6 39 00 00 00 00 00 11 b5 00 d7 01 0f 01 38 01 76 01 a6 01 ed 02 25 02 26 39 00 00 00 00 00 11 b6 02 5d 02 9b 02 c4 02 f6 03 15 03 45 03 51 03 5f 39 00 00 00 00 00 0d b7 03 6f 03 81 03 97 03 b5 03 d3 03 d8 39 00 00 00 00 00 11 b8 00 3a 00 4e 00 70 00 8d 00 a5 00 bb 00 ce 00 df 39 00 00 00 00 00 11 b9 00 ee 01 21 01 47 01 82 01 af 01 f3 02 2a 02 2b 39 00 00 00 00 00 11 ba 02 61 02 9f 02 c8 02 fa 03 1e 03 52 03 63 03 7a 39 01 00 00 00 00 0d bb 03 9e 03 b8 03 ba 03 ca 03 d6 03 d8 15 00 00 00 00 00 02 ff 21 15 00 00 00 00 00 02 fb 01 39 00 00 00 00 00 11 b0 00 2b 00 3f 00 61 00 7e 00 97 00 ad 00 c1 00 d3 39 00 00 00 00 00 11 b1 00 e3 01 18 01 40 01 7b 01 a9 01 ef 02 26 02 28 39 00 00 00 00 00 11 b2 02 5e 02 9c 02 c4 02 f6 03 14 03 44 03 50 03 5d 39 00 00 00 00 00 0d b3 03 6e 03 80 03 99 03 ba 03 d5 03 d8 39 00 00 00 00 00 11 b4 00 00 00 20 00 49 00 6a 00 85 00 9e 00 b3 00 c6 39 00 00 00 00 00 11 b5 00 d7 01 0f 01 38 01 76 01 a6 01 ed 02 25 02 26 39 00 00 00 00 00 11 b6 02 5d 02 9b 02 c4 02 f6 03 15 03 45 03 51 03 5f 39 00 00 00 00 00 0d b7 03 6f 03 81 03 97 03 b5 03 d3 03 d8 39 00 00 00 00 00 11 b8 00 3a 00 4e 00 70 00 8d 00 a5 00 bb 00 ce 00 df 39 00 00 00 00 00 11 b9 00 ee 01 21 01 47 01 82 01 af 01 f3 02 2a 02 2b 39 00 00 00 00 00 11 ba 02 61 02 9f 02 c8 02 fa 03 1e 03 52 03 63 03 7a 39 00 00 00 00 00 0d bb 03 9e 03 b8 03 ba 03 ca 03 d6 03 d8 15 01 00 00 00 00 02 ff 10];
		qcom,mdss-dsi-gamma1-command = [15 00 00 00 00 00 02 ff 20 15 00 00 00 00 00 02 fb 01 39 00 00 00 00 00 11 b0 00 bc 00 c6 00 d7 00 e7 00 f6 01 02 01 0f 01 1b 39 00 00 00 00 00 11 b1 01 26 01 4c 01 69 01 9b 01 c2 02 00 02 34 02 36 39 00 00 00 00 00 11 b2 02 6a 02 aa 02 ce 02 ff 03 20 03 4b 03 58 03 66 39 00 00 00 00 00 0d b3 03 75 03 87 03 9e 03 b7 03 d1 03 d7 39 00 00 00 00 00 11 b4 00 00 00 22 00 4e 00 70 00 8c 00 a5 00 ba 00 cd 39 00 00 00 00 00 11 b5 00 de 01 15 01 3f 01 7d 01 ac 01 f2 02 2a 02 2c 39 00 00 00 00 00 11 b6 02 62 02 9f 02 c7 02 fa 03 19 03 46 03 53 03 61 39 00 00 00 00 00 0d b7 03 71 03 83 03 9a 03 b5 03 d5 03 d7 39 00 00 00 00 00 11 b8 01 04 01 0a 01 17 01 21 01 2b 01 35 01 3f 01 47 39 00 00 00 00 00 11 b9 01 4f 01 6d 01 87 01 b1 01 d4 02 0d 02 3e 02 40 39 00 00 00 00 00 11 ba 02 73 02 ae 02 d5 03 08 03 26 03 57 03 5d 03 6a 39 01 00 00 00 00 0d bb 03 79 03 8c 03 a0 03 c1 03 c3 03 d7 15 00 00 00 00 00 02 ff 21 15 00 00 00 00 00 02 fb 01 39 00 00 00 00 00 11 b0 00 bc 00 c6 00 d7 00 e7 00 f6 01 02 01 0f 01 1b 39 00 00 00 00 00 11 b1 01 26 01 4c 01 69 01 9b 01 c2 02 00 02 34 02 36 39 00 00 00 00 00 11 b2 02 6a 02 aa 02 ce 02 ff 03 20 03 4b 03 58 03 66 39 00 00 00 00 00 0d b3 03 75 03 87 03 9e 03 b7 03 d1 03 d7 39 00 00 00 00 00 11 b4 00 00 00 22 00 4e 00 70 00 8c 00 a5 00 ba 00 cd 39 00 00 00 00 00 11 b5 00 de 01 15 01 3f 01 7d 01 ac 01 f2 02 2a 02 2c 39 00 00 00 00 00 11 b6 02 62 02 9f 02 c7 02 fa 03 19 03 46 03 53 03 61 39 00 00 00 00 00 0d b7 03 71 03 83 03 9a 03 b5 03 d5 03 d7 39 00 00 00 00 00 11 b8 01 04 01 0a 01 17 01 21 01 2b 01 35 01 3f 01 47 39 00 00 00 00 00 11 b9 01 4f 01 6d 01 87 01 b1 01 d4 02 0d 02 3e 02 40 39 00 00 00 00 00 11 ba 02 73 02 ae 02 d5 03 08 03 26 03 57 03 5d 03 6a 39 00 00 00 00 00 0d bb 03 79 03 8c 03 a0 03 c1 03 c3 03 d7 15 01 00 00 00 00 02 ff 10];
		qcom,mdss-dsi-gamma2-command = [15 00 00 00 00 00 02 ff 20 15 00 00 00 00 00 02 fb 01 39 00 00 00 00 00 11 b0 00 36 00 51 00 6f 00 8e 00 a5 00 ba 00 ce 00 df 39 00 00 00 00 00 11 b1 00 ef 01 22 01 48 01 84 01 b1 01 f4 02 2c 02 2e 39 00 00 00 00 00 11 b2 02 64 02 a2 02 c8 02 fc 03 1d 03 48 03 55 03 63 39 00 00 00 00 00 0d b3 03 73 03 86 03 9e 03 b7 03 cf 03 d7 39 00 00 00 00 00 11 b4 00 00 00 1e 00 4d 00 6f 00 8c 00 a5 00 ba 00 cd 39 00 00 00 00 00 11 b5 00 de 01 15 01 3f 01 7d 01 ac 01 f2 02 2a 02 2c 39 00 00 00 00 00 11 b6 02 62 02 9f 02 c6 02 fa 03 1c 03 45 03 53 03 61 39 00 00 00 00 00 0d b7 03 71 03 84 03 9d 03 ba 03 d6 03 d7 39 00 00 00 00 00 11 b8 00 b5 00 c0 00 d3 00 e4 00 f5 01 02 01 0f 01 1b 39 00 00 00 00 00 11 b9 01 26 01 4c 01 6c 01 9e 01 c5 02 03 02 37 02 39 39 00 00 00 00 00 11 ba 02 6d 02 a9 02 cf 03 05 03 28 03 53 03 5a 03 68 39 01 00 00 00 00 0d bb 03 79 03 8c 03 a0 03 c1 03 c3 03 d7 15 00 00 00 00 00 02 ff 21 15 00 00 00 00 00 02 fb 01 39 00 00 00 00 00 11 b0 00 36 00 51 00 6f 00 8e 00 a5 00 ba 00 ce 00 df 39 00 00 00 00 00 11 b1 00 ef 01 22 01 48 01 84 01 b1 01 f4 02 2c 02 2e 39 00 00 00 00 00 11 b2 02 64 02 a2 02 c8 02 fc 03 1d 03 48 03 55 03 63 39 00 00 00 00 00 0d b3 03 73 03 86 03 9e 03 b7 03 cf 03 d7 39 00 00 00 00 00 11 b4 00 00 00 1e 00 4d 00 6f 00 8c 00 a5 00 ba 00 cd 39 00 00 00 00 00 11 b5 00 de 01 15 01 3f 01 7d 01 ac 01 f2 02 2a 02 2c 39 00 00 00 00 00 11 b6 02 62 02 9f 02 c6 02 fb 03 1c 03 45 03 53 03 61 39 00 00 00 00 00 0d b7 03 71 03 84 03 9d 03 ba 03 d6 03 d7 39 00 00 00 00 00 11 b8 01 b5 00 c0 00 d3 01 e4 01 f5 01 02 01 0f 01 1b 39 00 00 00 00 00 11 b9 01 26 01 4c 01 6c 01 9e 01 c5 02 03 02 37 02 39 39 00 00 00 00 00 11 ba 02 6d 02 a9 02 cf 03 05 03 28 03 53 03 5a 03 68 39 00 00 00 00 00 0d bb 03 77 03 8b 03 a5 03 c6 03 ca 03 d7 15 01 00 00 00 00 02 ff 10];
		qcom,mdss-dsi-gamma3-command = [15 00 00 00 00 00 02 ff 20 15 00 00 00 00 00 02 fb 01 39 00 00 00 00 00 11 b0 00 4f 00 61 00 7e 00 97 00 ae 00 c4 00 d6 00 e8 39 00 00 00 00 00 11 b1 00 f3 01 27 01 4b 01 86 01 b6 01 f7 02 2d 02 2f 39 00 00 00 00 00 11 b2 02 64 02 a1 02 c9 02 fc 03 1d 03 48 03 55 03 63 39 00 00 00 00 00 0d b3 03 72 03 85 03 9c 03 bb 03 d5 03 d7 39 00 00 00 00 00 11 b4 00 66 00 75 00 90 00 a8 00 bd 00 cf 00 e0 00 ef 39 00 00 00 00 00 11 b5 00 fe 01 2c 01 51 01 89 01 b5 01 f9 02 2e 02 30 39 00 00 00 00 00 11 b6 02 65 02 a0 02 c9 02 fc 03 1c 03 47 03 55 03 62 39 00 00 00 00 00 0d b7 03 72 03 84 03 9a 03 b5 03 d5 03 d7 39 00 00 00 00 00 11 b8 00 00 00 20 00 57 00 7a 00 97 00 b3 00 c7 00 d9 39 00 00 00 00 00 11 b9 00 ea 01 20 01 47 01 86 01 b6 01 f9 02 2f 02 30 39 00 00 00 00 00 11 ba 02 65 02 a1 02 c9 02 fc 03 1e 03 4f 03 56 03 64 39 01 00 00 00 00 0d bb 03 73 03 86 03 9c 03 b7 03 bf 03 d7 15 00 00 00 00 00 02 ff 21 15 00 00 00 00 00 02 fb 01 39 00 00 00 00 00 11 b0 00 4f 00 61 00 7e 00 97 00 ae 00 c4 00 d6 00 e8 39 00 00 00 00 00 11 b1 00 f3 01 27 01 4b 01 86 01 b6 01 f7 02 2d 02 2f 39 00 00 00 00 00 11 b2 02 64 02 a1 02 c9 02 fc 03 1d 03 48 03 55 03 63 39 00 00 00 00 00 0d b3 03 72 03 85 03 9c 03 bb 03 d5 03 d7 39 00 00 00 00 00 11 b4 00 66 00 75 00 90 00 a8 00 bd 00 cf 00 e0 00 ef 39 00 00 00 00 00 11 b5 00 fe 01 2c 01 51 01 89 01 b5 01 f9 02 2e 02 30 39 00 00 00 00 00 11 b6 02 65 02 a0 02 c9 02 fc 03 1c 03 47 03 55 03 62 39 00 00 00 00 00 0d b7 03 72 03 84 03 9a 03 b5 03 d5 03 d7 39 00 00 00 00 00 11 b8 00 00 00 20 00 57 00 7a 00 97 00 b3 00 c7 00 d9 39 00 00 00 00 00 11 b9 00 ea 01 20 01 47 01 86 01 b6 01 f9 02 2f 02 30 39 00 00 00 00 00 11 ba 02 65 02 a1 02 c9 02 fc 03 1e 03 4f 03 56 03 64 39 00 00 00 00 00 0d bb 03 73 03 86 03 9c 03 b7 03 bf 03 d7 15 01 00 00 00 00 02 ff 10];
		qcom,mdss-dsi-gamma4-command = [15 00 00 00 00 00 02 ff 20 15 00 00 00 00 00 02 fb 01 39 00 00 00 00 00 11 b0 00 42 00 54 00 72 00 90 00 a5 00 bd 00 d0 00 dd 39 00 00 00 00 00 11 b1 00 f0 01 1f 01 46 01 82 01 b0 01 f5 02 2c 02 2e 39 00 00 00 00 00 11 b2 02 64 02 a0 02 c8 02 fc 03 1d 03 48 03 55 03 63 39 00 00 00 00 00 0d b3 03 73 03 85 03 9d 03 b8 03 d6 03 d7 39 00 00 00 00 00 11 b4 00 d6 00 de 00 ed 00 fa 01 07 01 12 01 1d 01 28 39 00 00 00 00 00 11 b5 01 31 01 54 01 71 01 a0 01 c6 02 03 02 36 02 37 39 00 00 00 00 00 11 b6 02 6b 02 a6 02 cd 03 00 03 22 03 4b 03 58 03 66 39 00 00 00 00 00 0d b7 03 75 03 88 03 9e 03 b9 03 d5 03 d7 39 00 00 00 00 00 11 b8 00 00 00 1b 00 51 00 7c 00 9a 00 b5 00 c8 00 da 39 00 00 00 00 00 11 b9 00 eb 01 1e 01 46 01 85 01 b3 01 f9 02 2f 02 30 39 00 00 00 00 00 11 ba 02 66 02 a1 02 c8 02 fd 03 1e 03 4b 03 56 03 65 39 01 00 00 00 00 0d bb 03 74 03 87 03 9e 03 bd 03 c1 03 d7 15 00 00 00 00 00 02 ff 21 15 00 00 00 00 00 02 fb 01 39 00 00 00 00 00 11 b0 00 42 00 54 00 72 00 90 00 a5 00 bd 00 d0 00 dd 39 00 00 00 00 00 11 b1 00 f0 01 1f 01 46 01 82 01 b0 01 f5 02 2c 02 2e 39 00 00 00 00 00 11 b2 02 64 02 a0 02 c8 02 fc 03 1d 03 48 03 55 03 63 39 00 00 00 00 00 0d b3 03 73 03 85 03 9d 03 b8 03 d6 03 d7 39 00 00 00 00 00 11 b4 00 d6 00 de 00 ed 00 fa 01 07 01 12 01 1d 01 28 39 00 00 00 00 00 11 b5 01 31 01 54 01 71 01 a0 01 c6 02 03 02 36 02 37 39 00 00 00 00 00 11 b6 02 6b 02 a6 02 cd 03 00 03 22 03 4b 03 58 03 66 39 00 00 00 00 00 0d b7 03 75 03 88 03 9e 03 b9 03 d5 03 d7 39 00 00 00 00 00 11 b8 00 00 00 1b 00 51 00 7c 00 9a 00 b5 00 c8 00 da 39 00 00 00 00 00 11 b9 00 eb 01 1e 01 46 01 85 01 b3 01 f9 02 2f 02 30 39 00 00 00 00 00 11 ba 02 66 02 a1 02 c8 02 fd 03 1e 03 4b 03 56 03 65 39 00 00 00 00 00 0d bb 03 74 03 87 03 9e 03 bd 03 c1 03 d7 15 01 00 00 00 00 02 ff 10];
		qcom,mdss-dsi-gamma5-command = [15 00 00 00 00 00 02 ff 20 15 00 00 00 00 00 02 fb 01 39 00 00 00 00 00 11 b0 00 00 00 1b 00 48 00 69 00 85 00 a0 00 b4 00 c9 39 00 00 00 00 00 11 b1 00 d9 01 0d 01 3d 01 7a 01 aa 01 f0 02 29 02 2a 39 00 00 00 00 00 11 b2 02 60 02 9f 02 c6 02 f7 03 16 03 47 03 54 03 62 39 00 00 00 00 00 0d b3 03 71 03 84 03 9b 03 ba 03 d4 03 d7 39 00 00 00 00 00 11 b4 00 a3 00 af 00 c3 00 d5 00 e5 00 f3 01 01 01 0d 39 00 00 00 00 00 11 b5 01 19 01 42 01 61 01 95 01 bd 01 fd 02 32 02 33 39 00 00 00 00 00 11 b6 02 68 02 a8 02 cb 02 ff 03 1f 03 49 03 56 03 63 39 00 00 00 00 00 0d b7 03 73 03 85 03 9b 03 b6 03 d6 03 d7 39 00 00 00 00 00 11 b8 00 e7 00 ee 00 fc 01 09 01 15 01 22 01 2b 01 36 39 00 00 00 00 00 11 b9 01 3e 01 5c 01 7b 01 a7 01 cd 02 08 02 3b 02 3c 39 00 00 00 00 00 11 ba 02 70 02 ac 02 d1 03 06 03 29 03 58 03 63 03 6c 39 01 00 00 00 00 0d bb 03 7d 03 90 03 a2 03 bb 03 bd 03 d7 15 00 00 00 00 00 02 ff 21 15 00 00 00 00 00 02 fb 01 39 00 00 00 00 00 11 b0 00 00 00 1b 00 48 00 69 00 85 00 a0 00 b4 00 c9 39 00 00 00 00 00 11 b1 00 d9 01 0d 01 3d 01 7a 01 aa 01 f0 02 29 02 2a 39 00 00 00 00 00 11 b2 02 60 02 9f 02 c6 02 f7 03 16 03 47 03 54 03 62 39 00 00 00 00 00 0d b3 03 71 03 84 03 9b 03 ba 03 d4 03 d7 39 00 00 00 00 00 11 b4 00 a3 00 af 00 c3 00 d5 00 e5 00 f3 01 01 01 0d 39 00 00 00 00 00 11 b5 01 19 01 42 01 61 01 95 01 bd 01 fd 02 32 02 33 39 00 00 00 00 00 11 b6 02 68 02 a8 02 cb 02 ff 03 1f 03 49 03 56 03 63 39 00 00 00 00 00 0d b7 03 73 03 85 03 9b 03 b6 03 d6 03 d7 39 00 00 00 00 00 11 b8 00 e7 00 ee 00 fc 01 09 01 15 01 22 01 2b 01 36 39 00 00 00 00 00 11 b9 01 3e 01 5c 01 7b 01 a7 01 cd 02 08 02 3b 02 3c 39 00 00 00 00 00 11 ba 02 70 02 ac 02 d1 03 06 03 29 03 58 03 63 03 6c 39 00 00 00 00 00 0d bb 03 7d 03 90 03 a2 03 bb 03 bd 03 d7 15 01 00 00 00 00 02 ff 10];
		qcom,mdss-dsi-gamma6-command = [15 00 00 00 00 00 02 ff 20 15 00 00 00 00 00 02 fb 01 39 00 00 00 00 00 11 b0 00 00 00 1b 00 48 00 69 00 85 00 a0 00 b4 00 c9 39 00 00 00 00 00 11 b1 00 d9 01 0d 01 3d 01 7a 01 aa 01 f0 02 29 02 2a 39 00 00 00 00 00 11 b2 02 60 02 9f 02 c6 02 f7 03 16 03 47 03 54 03 62 39 00 00 00 00 00 0d b3 03 71 03 84 03 9b 03 ba 03 d4 03 d7 39 00 00 00 00 00 11 b4 00 a3 00 af 00 c3 00 d5 00 e5 00 f3 01 01 01 0d 39 00 00 00 00 00 11 b5 01 19 01 42 01 61 01 95 01 bd 01 fd 02 32 02 33 39 00 00 00 00 00 11 b6 02 68 02 a8 02 cb 02 ff 03 1f 03 49 03 56 03 63 39 00 00 00 00 00 0d b7 03 73 03 85 03 9b 03 b6 03 d6 03 d7 39 00 00 00 00 00 11 b8 00 e7 00 ee 00 fc 01 09 01 15 01 22 01 2b 01 36 39 00 00 00 00 00 11 b9 01 3e 01 5c 01 7b 01 a7 01 cd 02 08 02 3b 02 3c 39 00 00 00 00 00 11 ba 02 70 02 ac 02 d1 03 06 03 29 03 58 03 63 03 6c 39 01 00 00 00 00 0d bb 03 7d 03 90 03 a2 03 bb 03 bd 03 d7 15 00 00 00 00 00 02 ff 21 15 00 00 00 00 00 02 fb 01 39 00 00 00 00 00 11 b0 00 00 00 1b 00 48 00 69 00 85 00 a0 00 b4 00 c9 39 00 00 00 00 00 11 b1 00 d9 01 0d 01 3d 01 7a 01 aa 01 f0 02 29 02 2a 39 00 00 00 00 00 11 b2 02 60 02 9f 02 c6 02 f7 03 16 03 47 03 54 03 62 39 00 00 00 00 00 0d b3 03 71 03 84 03 9b 03 ba 03 d4 03 d7 39 00 00 00 00 00 11 b4 00 a3 00 af 00 c3 00 d5 00 e5 00 f3 01 01 01 0d 39 00 00 00 00 00 11 b5 01 19 01 42 01 61 01 95 01 bd 01 fd 02 32 02 33 39 00 00 00 00 00 11 b6 02 68 02 a8 02 cb 02 ff 03 1f 03 49 03 56 03 63 39 00 00 00 00 00 0d b7 03 73 03 85 03 9b 03 b6 03 d6 03 d7 39 00 00 00 00 00 11 b8 00 e7 00 ee 00 fc 01 09 01 15 01 22 01 2b 01 36 39 00 00 00 00 00 11 b9 01 3e 01 5c 01 7b 01 a7 01 cd 02 08 02 3b 02 3c 39 00 00 00 00 00 11 ba 02 70 02 ac 02 d1 03 06 03 29 03 58 03 63 03 6c 39 00 00 00 00 00 0d bb 03 7d 03 90 03 a2 03 bb 03 bd 03 d7 15 01 00 00 00 00 02 ff 10];
		qcom,mdss-dsi-gamma7-command = [15 00 00 00 00 00 02 ff 20 15 00 00 00 00 00 02 fb 01 39 00 00 00 00 00 11 b0 00 b2 00 bf 00 d1 00 e2 00 ef 00 fd 01 09 01 15 39 00 00 00 00 00 11 b1 01 20 01 45 01 66 01 98 01 bf 01 fe 02 33 02 35 39 00 00 00 00 00 11 b2 02 69 02 a6 02 cd 02 ff 03 20 03 4b 03 57 03 65 39 00 00 00 00 00 0d b3 03 75 03 88 03 a0 03 b9 03 d5 03 d7 39 00 00 00 00 00 11 b4 00 00 00 1b 00 49 00 6d 00 8c 00 a5 00 bb 00 ce 39 00 00 00 00 00 11 b5 00 df 01 16 01 3f 01 7d 01 ac 01 f1 02 29 02 2b 39 00 00 00 00 00 11 b6 02 61 02 9f 02 c6 02 f9 03 18 03 46 03 53 03 61 39 00 00 00 00 00 0d b7 03 71 03 84 03 9c 03 b9 03 d5 03 d7 39 00 00 00 00 00 11 b8 00 09 00 2b 00 5f 00 85 00 a1 00 b9 00 ce 00 e0 39 00 00 00 00 00 11 b9 00 f1 01 25 01 4c 01 88 01 b5 01 f8 02 2f 02 31 39 00 00 00 00 00 11 ba 02 66 02 a4 02 ca 02 ff 03 22 03 54 03 57 03 66 39 01 00 00 00 00 0d bb 03 77 03 8a 03 a0 03 b7 03 c3 03 d7 15 00 00 00 00 00 02 ff 21 15 00 00 00 00 00 02 fb 01 39 00 00 00 00 00 11 b0 00 b2 00 bf 00 d1 00 e2 00 ef 00 fd 01 09 01 15 39 00 00 00 00 00 11 b1 01 20 01 45 01 66 01 98 01 bf 01 fe 02 33 02 35 39 00 00 00 00 00 11 b2 02 69 02 a6 02 cd 02 ff 03 20 03 4b 03 57 03 65 39 00 00 00 00 00 0d b3 03 75 03 88 03 a0 03 b9 03 d5 03 d7 39 00 00 00 00 00 11 b4 00 00 00 1b 00 49 00 6d 00 8c 00 a5 00 bb 00 ce 39 00 00 00 00 00 11 b5 00 df 01 16 01 3f 01 7d 01 ac 01 f1 02 29 02 2b 39 00 00 00 00 00 11 b6 02 61 02 9f 02 c6 02 f9 03 18 03 46 03 53 03 61 39 00 00 00 00 00 0d b7 03 71 03 84 03 9c 03 b9 03 d5 03 d7 39 00 00 00 00 00 11 b8 00 09 00 2b 00 5f 00 85 00 a1 00 b9 00 ce 00 e0 39 00 00 00 00 00 11 b9 00 f1 01 25 01 4c 01 88 01 b5 01 f8 02 2f 02 31 39 00 00 00 00 00 11 ba 02 66 02 a4 02 ca 02 ff 03 22 03 54 03 57 03 66 39 00 00 00 00 00 0d bb 03 77 03 8a 03 a0 03 b7 03 c3 03 d7 15 01 00 00 00 00 02 ff 10];
		qcom,mdss-dsi-gamma8-command = [15 00 00 00 00 00 02 ff 20 15 00 00 00 00 00 02 fb 01 39 00 00 00 00 00 11 b0 01 35 01 3a 01 42 01 4b 01 52 01 59 01 61 01 67 39 00 00 00 00 00 11 b1 01 6e 01 85 01 9a 01 bf 01 de 02 13 02 42 02 43 39 00 00 00 00 00 11 b2 02 74 02 b0 02 d6 03 0a 03 27 03 52 03 5d 03 6b 39 00 00 00 00 00 0d b3 03 7a 03 8c 03 a2 03 bf 03 d5 03 d7 39 00 00 00 00 00 11 b4 00 00 00 1e 00 4a 00 6c 00 89 00 a2 00 b7 00 cb 39 00 00 00 00 00 11 b5 00 dc 01 14 01 3e 01 7c 01 ab 01 f1 02 29 02 2b 39 00 00 00 00 00 11 b6 02 61 02 9f 02 c6 02 f8 03 1a 03 46 03 53 03 61 39 00 00 00 00 00 0d b7 03 70 03 83 03 9b 03 b6 03 d6 03 d7 39 00 00 00 00 00 11 b8 00 16 00 3c 00 69 00 86 00 a3 00 bb 00 d1 00 e2 39 00 00 00 00 00 11 b9 00 f2 01 26 01 4d 01 88 01 b5 01 f9 02 2f 02 31 39 00 00 00 00 00 11 ba 02 66 02 a4 02 ca 02 ff 03 23 03 52 03 57 03 66 39 01 00 00 00 00 0d bb 03 79 03 8c 03 a0 03 bb 03 bf 03 d7 15 00 00 00 00 00 02 ff 21 15 00 00 00 00 00 02 fb 01 39 00 00 00 00 00 11 b0 01 35 01 3a 01 42 01 4b 01 52 01 59 01 61 01 67 39 00 00 00 00 00 11 b1 01 6e 01 85 01 9a 01 bf 01 de 02 13 02 42 02 43 39 00 00 00 00 00 11 b2 02 74 02 b0 02 d6 03 0a 03 27 03 52 03 5d 03 6b 39 00 00 00 00 00 0d b3 03 7a 03 8c 03 a2 03 bf 03 d5 03 d7 39 00 00 00 00 00 11 b4 00 00 00 1e 00 4a 00 6c 00 89 00 a2 00 b7 00 cb 39 00 00 00 00 00 11 b5 00 dc 01 14 01 3e 01 7c 01 ab 01 f1 02 29 02 2b 39 00 00 00 00 00 11 b6 02 61 02 9f 02 c6 02 f8 03 1a 03 46 03 53 03 61 39 00 00 00 00 00 0d b7 03 70 03 83 03 9b 03 b6 03 d6 03 d7 39 00 00 00 00 00 11 b8 00 16 00 3c 00 69 00 86 00 a3 00 bb 00 d1 00 e2 39 00 00 00 00 00 11 b9 00 f2 01 26 01 4d 01 88 01 b5 01 f9 02 2f 02 31 39 00 00 00 00 00 11 ba 02 66 02 a4 02 ca 02 ff 03 23 03 52 03 57 03 66 39 00 00 00 00 00 0d bb 03 79 03 8c 03 a0 03 bb 03 bf 03 d7 15 01 00 00 00 00 02 ff 10];
		qcom,mdss-dsi-gamma9-command = [15 00 00 00 00 00 02 ff 20 15 00 00 00 00 00 02 fb 01 39 00 00 00 00 00 11 b0 00 00 00 17 00 3f 00 67 00 87 00 a0 00 b4 00 c8 39 00 00 00 00 00 11 b1 00 db 01 13 01 3c 01 7c 01 ab 01 f1 02 29 02 2b 39 00 00 00 00 00 11 b2 02 60 02 9d 02 c4 02 f6 03 1b 03 47 03 54 03 62 39 00 00 00 00 00 0d b3 03 71 03 82 03 98 03 b1 03 d1 03 d7 39 00 00 00 00 00 11 b4 00 91 00 9d 00 b3 00 c6 00 d7 00 e7 00 f6 01 03 39 00 00 00 00 00 11 b5 01 0f 01 39 01 5b 01 90 01 ba 01 fa 02 30 02 32 39 00 00 00 00 00 11 b6 02 67 02 a4 02 ca 02 fe 03 1e 03 48 03 56 03 63 39 00 00 00 00 00 0d b7 03 72 03 84 03 98 03 b1 03 d3 03 d7 39 00 00 00 00 00 11 b8 01 4a 01 4d 01 55 01 5c 01 63 01 6a 01 70 01 77 39 00 00 00 00 00 11 b9 01 7d 01 93 01 a7 01 c9 01 e7 02 1a 02 48 02 4a 39 00 00 00 00 00 11 ba 02 7a 02 b4 02 db 03 0e 03 32 03 5d 03 62 03 6f 39 01 00 00 00 00 0d bb 03 7d 03 8c 03 a2 03 bd 03 c3 03 d7 15 00 00 00 00 00 02 ff 21 15 00 00 00 00 00 02 fb 01 39 00 00 00 00 00 11 b0 00 00 00 17 00 3f 00 67 00 87 00 a0 00 b4 00 c8 39 00 00 00 00 00 11 b1 00 db 01 13 01 3c 01 7c 01 ab 01 f1 02 29 02 2b 39 00 00 00 00 00 11 b2 02 60 02 9d 02 c4 02 f6 03 1b 03 47 03 54 03 62 39 00 00 00 00 00 0d b3 03 71 03 82 03 98 03 b1 03 d1 03 d7 39 00 00 00 00 00 11 b4 00 91 00 9d 00 b3 00 c6 00 d7 00 e7 00 f6 01 03 39 00 00 00 00 00 11 b5 01 0f 01 39 01 5b 01 90 01 ba 01 fa 02 30 02 32 39 00 00 00 00 00 11 b6 02 67 02 a4 02 ca 02 fe 03 1e 03 48 03 56 03 63 39 00 00 00 00 00 0d b7 03 72 03 84 03 98 03 b1 03 d3 03 d7 39 00 00 00 00 00 11 b8 01 4a 01 4d 01 55 01 5c 01 63 01 6a 01 70 01 77 39 00 00 00 00 00 11 b9 01 7d 01 93 01 a7 01 c9 01 e7 02 1a 02 48 02 4a 39 00 00 00 00 00 11 ba 02 7a 02 b4 02 db 03 0e 03 32 03 5d 03 62 03 6f 39 00 00 00 00 00 0d bb 03 7d 03 8c 03 a2 03 bd 03 c3 03 d7 15 01 00 00 00 00 02 ff 10];
		qcom,mdss-dsi-gamma10-command = [15 00 00 00 00 00 02 ff 20 15 00 00 00 00 00 02 fb 01 39 00 00 00 00 00 11 b0 00 00 00 20 00 4b 00 6a 00 87 00 a0 00 b7 00 c8 39 00 00 00 00 00 11 b1 00 d9 01 11 01 3d 01 7d 01 ac 01 f2 02 29 02 2b 39 00 00 00 00 00 11 b2 02 62 02 9f 02 c6 02 fb 03 1c 03 47 03 54 03 62 39 00 00 00 00 00 0d b3 03 72 03 84 03 9a 03 b7 03 cf 03 d7 39 00 00 00 00 00 11 b4 00 00 00 22 00 4e 00 71 00 8d 00 a5 00 ba 00 ce 39 00 00 00 00 00 11 b5 00 df 01 16 01 3f 01 81 01 ac 01 f4 02 2a 02 2b 39 00 00 00 00 00 11 b6 02 62 02 9d 02 c5 02 fa 03 1c 03 45 03 53 03 61 39 00 00 00 00 00 0d b7 03 70 03 83 03 99 03 b4 03 d6 03 d7 39 00 00 00 00 00 11 b8 00 ed 00 f4 01 03 01 0e 01 1a 01 25 01 30 01 38 39 00 00 00 00 00 11 b9 01 41 01 61 01 7d 01 ad 01 cf 02 0a 02 3b 02 3c 39 00 00 00 00 00 11 ba 02 70 02 aa 02 d1 03 05 03 28 03 55 03 5c 03 69 39 01 00 00 00 00 0d bb 03 79 03 8a 03 a0 03 bf 03 c1 03 d7 15 00 00 00 00 00 02 ff 21 15 00 00 00 00 00 02 fb 01 39 00 00 00 00 00 11 b0 00 00 00 20 00 4b 00 6a 00 87 00 a0 00 b7 00 c8 39 00 00 00 00 00 11 b1 00 d9 01 11 01 3d 01 7d 01 ac 01 f2 02 29 02 2b 39 00 00 00 00 00 11 b2 02 62 02 9f 02 c6 02 fb 03 1c 03 47 03 54 03 62 39 00 00 00 00 00 0d b3 03 72 03 84 03 9a 03 b7 03 cf 03 d7 39 00 00 00 00 00 11 b4 00 00 00 22 00 4e 00 71 00 8d 00 a5 00 ba 00 ce 39 00 00 00 00 00 11 b5 00 df 01 16 01 3f 01 81 01 ac 01 f4 02 2a 02 2b 39 00 00 00 00 00 11 b6 02 62 02 9d 02 c5 02 fa 03 1c 03 45 03 53 03 61 39 00 00 00 00 00 0d b7 03 70 03 83 03 99 03 b4 03 d6 03 d7 39 00 00 00 00 00 11 b8 00 ed 00 f4 01 03 01 0e 01 1a 01 25 01 30 01 38 39 00 00 00 00 00 11 b9 01 41 01 61 01 7d 01 ad 01 cf 02 0a 02 3b 02 3c 39 00 00 00 00 00 11 ba 02 70 02 aa 02 d1 03 05 03 28 03 55 03 5c 03 69 39 00 00 00 00 00 0d bb 03 79 03 8a 03 a0 03 bf 03 c1 03 d7 15 01 00 00 00 00 02 ff 10];
		qcom,mdss-dsi-gamma11-command = [15 00 00 00 00 00 02 ff 20 15 00 00 00 00 00 02 fb 01 39 00 00 00 00 00 11 b0 00 00 00 23 00 51 00 6c 00 8b 00 9d 00 b5 00 c9 39 00 00 00 00 00 11 b1 00 d8 01 0f 01 3c 01 7a 01 aa 01 f1 02 28 02 2a 39 00 00 00 00 00 11 b2 02 60 02 9e 02 c5 02 f4 03 12 03 46 03 53 03 61 39 00 00 00 00 00 0d b3 03 71 03 84 03 9a 03 b7 03 d5 03 d7 39 00 00 00 00 00 11 b4 00 f5 00 fc 01 08 01 14 01 1e 01 29 01 32 01 3b 39 00 00 00 00 00 11 b5 01 44 01 63 01 7d 01 a9 01 cc 02 06 02 39 02 3b 39 00 00 00 00 00 11 b6 02 6e 02 ab 02 d0 03 02 03 23 03 4d 03 59 03 67 39 00 00 00 00 00 0d b7 03 76 03 88 03 9e 03 b9 03 d5 03 d7 39 00 00 00 00 00 11 b8 00 e7 00 ef 00 fd 01 09 01 16 01 20 01 2b 01 35 39 00 00 00 00 00 11 b9 01 3d 01 5e 01 7a 01 a8 01 cd 02 08 02 3a 02 3c 39 00 00 00 00 00 11 ba 02 6f 02 ab 02 d1 03 03 03 28 03 57 03 5c 03 6f 39 01 00 00 00 00 0d bb 03 80 03 99 03 a3 03 bc 03 c2 03 d7 15 00 00 00 00 00 02 ff 21 15 00 00 00 00 00 02 fb 01 39 00 00 00 00 00 11 b0 00 00 00 23 00 51 00 6c 00 8b 00 9d 00 b5 00 c9 39 00 00 00 00 00 11 b1 00 d8 01 0f 01 3c 01 7a 01 aa 01 f1 02 28 02 2a 39 00 00 00 00 00 11 b2 02 60 02 9e 02 c5 02 f4 03 12 03 46 03 53 03 61 39 00 00 00 00 00 0d b3 03 71 03 84 03 9a 03 b7 03 d5 03 d7 39 00 00 00 00 00 11 b4 00 f5 00 fc 01 08 01 14 01 1e 01 29 01 32 01 3b 39 00 00 00 00 00 11 b5 01 44 01 63 01 7d 01 a9 01 cc 02 06 02 39 02 3b 39 00 00 00 00 00 11 b6 02 6e 02 ab 02 d0 03 02 03 23 03 4d 03 59 03 67 39 00 00 00 00 00 0d b7 03 76 03 88 03 9e 03 b9 03 d5 03 d7 39 00 00 00 00 00 11 b8 00 e7 00 ef 00 fd 01 09 01 16 01 20 01 2b 01 35 39 00 00 00 00 00 11 b9 01 3d 01 5e 01 7a 01 a8 01 cd 02 08 02 3a 02 3c 39 00 00 00 00 00 11 ba 02 6f 02 ab 02 d1 03 03 03 28 03 57 03 5c 03 6f 39 00 00 00 00 00 0d bb 03 80 03 99 03 a3 03 bc 03 c2 03 d7 15 01 00 00 00 00 02 ff 10];
		qcom,mdss-dsi-gamma12-command = [15 00 00 00 00 00 02 ff 20 15 00 00 00 00 00 02 fb 01 39 00 00 00 00 00 11 b0 00 00 00 23 00 51 00 6c 00 8b 00 9d 00 b5 00 c9 39 00 00 00 00 00 11 b1 00 d8 01 0f 01 3c 01 7a 01 aa 01 f1 02 28 02 2a 39 00 00 00 00 00 11 b2 02 60 02 9e 02 c5 02 f4 03 12 03 46 03 53 03 61 39 00 00 00 00 00 0d b3 03 71 03 84 03 9a 03 b7 03 d5 03 d7 39 00 00 00 00 00 11 b4 00 f5 00 fc 01 08 01 14 01 1e 01 29 01 32 01 3b 39 00 00 00 00 00 11 b5 01 44 01 63 01 7d 01 a9 01 cc 02 06 02 39 02 3b 39 00 00 00 00 00 11 b6 02 6e 02 ab 02 d0 03 02 03 23 03 4d 03 59 03 67 39 00 00 00 00 00 0d b7 03 76 03 88 03 9e 03 b9 03 d5 03 d7 39 00 00 00 00 00 11 b8 00 e7 00 ef 00 fd 01 09 01 16 01 20 01 2b 01 35 39 00 00 00 00 00 11 b9 01 3d 01 5e 01 7a 01 a8 01 cd 02 08 02 3a 02 3c 39 00 00 00 00 00 11 ba 02 6f 02 ab 02 d1 03 03 03 28 03 57 03 5c 03 6f 39 01 00 00 00 00 0d bb 03 80 03 99 03 a3 03 bc 03 c2 03 d7 15 00 00 00 00 00 02 ff 21 15 00 00 00 00 00 02 fb 01 39 00 00 00 00 00 11 b0 00 00 00 23 00 51 00 6c 00 8b 00 9d 00 b5 00 c9 39 00 00 00 00 00 11 b1 00 d8 01 0f 01 3c 01 7a 01 aa 01 f1 02 28 02 2a 39 00 00 00 00 00 11 b2 02 60 02 9e 02 c5 02 f4 03 12 03 46 03 53 03 61 39 00 00 00 00 00 0d b3 03 71 03 84 03 9a 03 b7 03 d5 03 d7 39 00 00 00 00 00 11 b4 00 f5 00 fc 01 08 01 14 01 1e 01 29 01 32 01 3b 39 00 00 00 00 00 11 b5 01 44 01 63 01 7d 01 a9 01 cc 02 06 02 39 02 3b 39 00 00 00 00 00 11 b6 02 6e 02 ab 02 d0 03 02 03 23 03 4d 03 59 03 67 39 00 00 00 00 00 0d b7 03 76 03 88 03 9e 03 b9 03 d5 03 d7 39 00 00 00 00 00 11 b8 00 e7 00 ef 00 fd 01 09 01 16 01 20 01 2b 01 35 39 00 00 00 00 00 11 b9 01 3d 01 5e 01 7a 01 a8 01 cd 02 08 02 3a 02 3c 39 00 00 00 00 00 11 ba 02 6f 02 ab 02 d1 03 03 03 28 03 57 03 5c 03 6f 39 00 00 00 00 00 0d bb 03 80 03 99 03 a3 03 bc 03 c2 03 d7 15 01 00 00 00 00 02 ff 10];
		qcom,mdss-dsi-gamma13-command = [15 00 00 00 00 00 02 ff 20 15 00 00 00 00 00 02 fb 01 39 00 00 00 00 00 11 b0 00 00 00 18 00 3f 00 6a 00 86 00 9f 00 ba 00 cd 39 00 00 00 00 00 11 b1 00 de 01 15 01 3e 01 7d 01 ab 01 f1 02 2a 02 2c 39 00 00 00 00 00 11 b2 02 62 02 9f 02 c7 02 fa 03 1b 03 46 03 53 03 61 39 00 00 00 00 00 0d b3 03 71 03 83 03 9b 03 b4 03 d6 03 d7 39 00 00 00 00 00 11 b4 00 00 00 25 00 52 00 72 00 8e 00 a6 00 ba 00 cd 39 00 00 00 00 00 11 b5 00 de 01 15 01 3f 01 7d 01 ac 01 f1 02 2a 02 2b 39 00 00 00 00 00 11 b6 02 61 02 9f 02 c7 02 f8 03 1a 03 45 03 53 03 61 39 00 00 00 00 00 0d b7 03 70 03 82 03 9a 03 b7 03 d5 03 d7 39 00 00 00 00 00 11 b8 01 09 01 11 01 1c 01 25 01 2f 01 39 01 41 01 4a 39 00 00 00 00 00 11 b9 01 52 01 6f 01 89 01 b3 01 d5 02 0d 02 3f 02 40 39 00 00 00 00 00 11 ba 02 72 02 af 02 d6 03 07 03 2a 03 57 03 5c 03 69 39 01 00 00 00 00 0d bb 03 7a 03 8b 03 a2 03 bd 03 c1 03 d7 15 00 00 00 00 00 02 ff 21 15 00 00 00 00 00 02 fb 01 39 00 00 00 00 00 11 b0 00 00 00 18 00 3f 00 6a 00 86 00 9f 00 ba 00 cd 39 00 00 00 00 00 11 b1 00 de 01 15 01 3e 01 7d 01 ab 01 f1 02 2a 02 2c 39 00 00 00 00 00 11 b2 02 62 02 9f 02 c7 02 fa 03 1b 03 46 03 53 03 61 39 00 00 00 00 00 0d b3 03 71 03 83 03 9b 03 b4 03 d6 03 d7 39 00 00 00 00 00 11 b4 00 00 00 25 00 52 00 72 00 8e 00 a6 00 ba 00 cd 39 00 00 00 00 00 11 b5 00 de 01 15 01 3f 01 7d 01 ac 01 f1 02 2a 02 2b 39 00 00 00 00 00 11 b6 02 61 02 9f 02 c7 02 f8 03 1a 03 45 03 53 03 61 39 00 00 00 00 00 0d b7 03 70 03 82 03 9a 03 b7 03 d5 03 d7 39 00 00 00 00 00 11 b8 01 09 01 11 01 1c 01 25 01 2f 01 39 01 41 01 4a 39 00 00 00 00 00 11 b9 01 52 01 6f 01 89 01 b3 01 d5 02 0d 02 3f 02 40 39 00 00 00 00 00 11 ba 02 72 02 af 02 d6 03 07 03 2a 03 57 03 5c 03 69 39 00 00 00 00 00 0d bb 03 7a 03 8b 03 a2 03 bd 03 c1 03 d7 15 01 00 00 00 00 02 ff 10];
		qcom,mdss-dsi-gamma14-command = [15 00 00 00 00 00 02 ff 20 15 00 00 00 00 00 02 fb 01 39 00 00 00 00 00 11 b0 00 00 00 20 00 4b 00 6a 00 87 00 a0 00 b7 00 c8 39 00 00 00 00 00 11 b1 00 d9 01 11 01 3d 01 7d 01 ac 01 f2 02 29 02 2b 39 00 00 00 00 00 11 b2 02 62 02 9f 02 c6 02 fb 03 1c 03 47 03 54 03 62 39 00 00 00 00 00 0d b3 03 72 03 84 03 9a 03 b7 03 cf 03 d7 39 00 00 00 00 00 11 b4 00 00 00 22 00 4e 00 71 00 8d 00 a5 00 ba 00 ce 39 00 00 00 00 00 11 b5 00 df 01 16 01 3f 01 81 01 ac 01 f4 02 2a 02 2b 39 00 00 00 00 00 11 b6 02 62 02 9d 02 c5 02 fa 03 1c 03 45 03 53 03 61 39 00 00 00 00 00 0d b7 03 70 03 83 03 99 03 b4 03 d6 03 d7 39 00 00 00 00 00 11 b8 00 ed 00 f4 01 03 01 0e 01 1a 01 25 01 30 01 38 39 00 00 00 00 00 11 b9 01 41 01 61 01 7d 01 ad 01 cf 02 0a 02 3b 02 3c 39 00 00 00 00 00 11 ba 02 70 02 aa 02 d1 03 05 03 28 03 55 03 5c 03 69 39 01 00 00 00 00 0d bb 03 79 03 8a 03 a0 03 bf 03 c1 03 d7 15 00 00 00 00 00 02 ff 21 15 00 00 00 00 00 02 fb 01 39 00 00 00 00 00 11 b0 00 00 00 20 00 4b 00 6a 00 87 00 a0 00 b7 00 c8 39 00 00 00 00 00 11 b1 00 d9 01 11 01 3d 01 7d 01 ac 01 f2 02 29 02 2b 39 00 00 00 00 00 11 b2 02 62 02 9f 02 c6 02 fb 03 1c 03 47 03 54 03 62 39 00 00 00 00 00 0d b3 03 72 03 84 03 9a 03 b7 03 cf 03 d7 39 00 00 00 00 00 11 b4 00 00 00 22 00 4e 00 71 00 8d 00 a5 00 ba 00 ce 39 00 00 00 00 00 11 b5 00 df 01 16 01 3f 01 81 01 ac 01 f4 02 2a 02 2b 39 00 00 00 00 00 11 b6 02 62 02 9d 02 c5 02 fa 03 1c 03 45 03 53 03 61 39 00 00 00 00 00 0d b7 03 70 03 83 03 99 03 b4 03 d6 03 d7 39 00 00 00 00 00 11 b8 00 ed 00 f4 01 03 01 0e 01 1a 01 25 01 30 01 38 39 00 00 00 00 00 11 b9 01 41 01 61 01 7d 01 ad 01 cf 02 0a 02 3b 02 3c 39 00 00 00 00 00 11 ba 02 70 02 aa 02 d1 03 05 03 28 03 55 03 5c 03 69 39 00 00 00 00 00 0d bb 03 79 03 8a 03 a0 03 bf 03 c1 03 d7 15 01 00 00 00 00 02 ff 10];
		qcom,mdss-dsi-gamma15-command = [15 00 00 00 00 00 02 ff 20 15 00 00 00 00 00 02 fb 01 39 00 00 00 00 00 11 b0 00 4f 00 61 00 7e 00 97 00 ae 00 c4 00 d6 00 e8 39 00 00 00 00 00 11 b1 00 f3 01 27 01 4b 01 86 01 b6 01 f7 02 2d 02 2f 39 00 00 00 00 00 11 b2 02 64 02 a1 02 c9 02 fc 03 1d 03 48 03 55 03 63 39 00 00 00 00 00 0d b3 03 72 03 85 03 9c 03 bb 03 d5 03 d7 39 00 00 00 00 00 11 b4 00 66 00 75 00 90 00 a8 00 bd 00 cf 00 e0 00 ef 39 00 00 00 00 00 11 b5 00 fe 01 2c 01 51 01 89 01 b5 01 f9 02 2e 02 30 39 00 00 00 00 00 11 b6 02 65 02 a0 02 c9 02 fc 03 1c 03 47 03 55 03 62 39 00 00 00 00 00 0d b7 03 72 03 84 03 9a 03 b5 03 d5 03 d7 39 00 00 00 00 00 11 b8 00 00 00 20 00 57 00 7a 00 97 00 b3 00 c7 00 d9 39 00 00 00 00 00 11 b9 00 ea 01 20 01 47 01 86 01 b6 01 f9 02 2f 02 30 39 00 00 00 00 00 11 ba 02 65 02 a1 02 c9 02 fc 03 1e 03 4f 03 56 03 64 39 01 00 00 00 00 0d bb 03 73 03 86 03 9c 03 b7 03 bf 03 d7 15 00 00 00 00 00 02 ff 21 15 00 00 00 00 00 02 fb 01 39 00 00 00 00 00 11 b0 00 4f 00 61 00 7e 00 97 00 ae 00 c4 00 d6 00 e8 39 00 00 00 00 00 11 b1 00 f3 01 27 01 4b 01 86 01 b6 01 f7 02 2d 02 2f 39 00 00 00 00 00 11 b2 02 64 02 a1 02 c9 02 fc 03 1d 03 48 03 55 03 63 39 00 00 00 00 00 0d b3 03 72 03 85 03 9c 03 bb 03 d5 03 d7 39 00 00 00 00 00 11 b4 00 66 00 75 00 90 00 a8 00 bd 00 cf 00 e0 00 ef 39 00 00 00 00 00 11 b5 00 fe 01 2c 01 51 01 89 01 b5 01 f9 02 2e 02 30 39 00 00 00 00 00 11 b6 02 65 02 a0 02 c9 02 fc 03 1c 03 47 03 55 03 62 39 00 00 00 00 00 0d b7 03 72 03 84 03 9a 03 b5 03 d5 03 d7 39 00 00 00 00 00 11 b8 00 00 00 20 00 57 00 7a 00 97 00 b3 00 c7 00 d9 39 00 00 00 00 00 11 b9 00 ea 01 20 01 47 01 86 01 b6 01 f9 02 2f 02 30 39 00 00 00 00 00 11 ba 02 65 02 a1 02 c9 02 fc 03 1e 03 4f 03 56 03 64 39 00 00 00 00 00 0d bb 03 73 03 86 03 9c 03 b7 03 bf 03 d7 15 01 00 00 00 00 02 ff 10];
		qcom,mdss-dsi-gamma16-command = [15 00 00 00 00 00 02 ff 20 15 00 00 00 00 00 02 fb 01 39 00 00 00 00 00 11 b0 00 00 00 23 00 51 00 6c 00 8b 00 9d 00 b5 00 c9 39 00 00 00 00 00 11 b1 00 d8 01 0f 01 3c 01 7a 01 aa 01 f1 02 28 02 2a 39 00 00 00 00 00 11 b2 02 60 02 9e 02 c5 02 f4 03 12 03 46 03 53 03 61 39 00 00 00 00 00 0d b3 03 71 03 84 03 9a 03 b7 03 d5 03 d7 39 00 00 00 00 00 11 b4 00 f5 00 fc 01 08 01 14 01 1e 01 29 01 32 01 3b 39 00 00 00 00 00 11 b5 01 44 01 63 01 7d 01 a9 01 cc 02 06 02 39 02 3b 39 00 00 00 00 00 11 b6 02 6e 02 ab 02 d0 03 02 03 23 03 4d 03 59 03 67 39 00 00 00 00 00 0d b7 03 76 03 88 03 9e 03 b9 03 d5 03 d7 39 00 00 00 00 00 11 b8 00 e7 00 ef 00 fd 01 09 01 16 01 20 01 2b 01 35 39 00 00 00 00 00 11 b9 01 3d 01 5e 01 7a 01 a8 01 cd 02 08 02 3a 02 3c 39 00 00 00 00 00 11 ba 02 6f 02 ab 02 d1 03 03 03 28 03 57 03 5c 03 6f 39 01 00 00 00 00 0d bb 03 80 03 99 03 a3 03 bc 03 c2 03 d7 15 00 00 00 00 00 02 ff 21 15 00 00 00 00 00 02 fb 01 39 00 00 00 00 00 11 b0 00 00 00 23 00 51 00 6c 00 8b 00 9d 00 b5 00 c9 39 00 00 00 00 00 11 b1 00 d8 01 0f 01 3c 01 7a 01 aa 01 f1 02 28 02 2a 39 00 00 00 00 00 11 b2 02 60 02 9e 02 c5 02 f4 03 12 03 46 03 53 03 61 39 00 00 00 00 00 0d b3 03 71 03 84 03 9a 03 b7 03 d5 03 d7 39 00 00 00 00 00 11 b4 00 f5 00 fc 01 08 01 14 01 1e 01 29 01 32 01 3b 39 00 00 00 00 00 11 b5 01 44 01 63 01 7d 01 a9 01 cc 02 06 02 39 02 3b 39 00 00 00 00 00 11 b6 02 6e 02 ab 02 d0 03 02 03 23 03 4d 03 59 03 67 39 00 00 00 00 00 0d b7 03 76 03 88 03 9e 03 b9 03 d5 03 d7 39 00 00 00 00 00 11 b8 00 e7 00 ef 00 fd 01 09 01 16 01 20 01 2b 01 35 39 00 00 00 00 00 11 b9 01 3d 01 5e 01 7a 01 a8 01 cd 02 08 02 3a 02 3c 39 00 00 00 00 00 11 ba 02 6f 02 ab 02 d1 03 03 03 28 03 57 03 5c 03 6f 39 00 00 00 00 00 0d bb 03 80 03 99 03 a3 03 bc 03 c2 03 d7 15 01 00 00 00 00 02 ff 10];
		qcom,mdss-dsi-gamma17-command = [15 00 00 00 00 00 02 ff 20 15 00 00 00 00 00 02 fb 01 39 00 00 00 00 00 11 b0 01 34 01 3a 01 41 01 4a 01 50 01 59 01 5f 01 66 39 00 00 00 00 00 11 b1 01 6c 01 85 01 9a 01 bf 01 df 02 13 02 41 02 43 39 00 00 00 00 00 11 b2 02 75 02 af 02 d6 03 09 03 27 03 51 03 5e 03 6c 39 00 00 00 00 00 0d b3 03 7b 03 8d 03 a3 03 bc 03 d2 03 d7 39 00 00 00 00 00 11 b4 00 00 00 1d 00 4c 00 6e 00 8c 00 a4 00 ba 00 cd 39 00 00 00 00 00 11 b5 00 df 01 15 01 3f 01 7d 01 ab 01 f5 02 2a 02 2b 39 00 00 00 00 00 11 b6 02 62 02 9d 02 c5 02 f8 03 1b 03 44 03 52 03 61 39 00 00 00 00 00 0d b7 03 70 03 83 03 9a 03 b5 03 d5 03 d7 39 00 00 00 00 00 11 b8 01 09 01 0f 01 1a 01 25 01 2f 01 38 01 42 01 4b 39 00 00 00 00 00 11 b9 01 52 01 6f 01 88 01 b2 01 d5 02 0e 02 3e 02 40 39 00 00 00 00 00 11 ba 02 73 02 ad 02 d4 03 08 03 29 03 56 03 5e 03 6c 39 01 00 00 00 00 0d bb 03 7b 03 8d 03 a1 03 c2 03 c4 03 d7 15 00 00 00 00 00 02 ff 21 15 00 00 00 00 00 02 fb 01 39 00 00 00 00 00 11 b0 01 34 01 3a 01 41 01 4a 01 50 01 59 01 5f 01 66 39 00 00 00 00 00 11 b1 01 6c 01 85 01 9a 01 bf 01 df 02 13 02 41 02 43 39 00 00 00 00 00 11 b2 02 75 02 af 02 d6 03 09 03 27 03 51 03 5e 03 6c 39 00 00 00 00 00 0d b3 03 7b 03 8d 03 a3 03 bc 03 d2 03 d7 39 00 00 00 00 00 11 b4 00 00 00 1d 00 4c 00 6e 00 8c 00 a4 00 ba 00 cd 39 00 00 00 00 00 11 b5 00 df 01 15 01 3f 01 7d 01 ab 01 f5 02 2a 02 2b 39 00 00 00 00 00 11 b6 02 62 02 9d 02 c5 02 f8 03 1b 03 44 03 52 03 61 39 00 00 00 00 00 0d b7 03 70 03 83 03 9a 03 b5 03 d5 03 d7 39 00 00 00 00 00 11 b8 01 09 01 0f 01 1a 01 25 01 2f 01 38 01 42 01 4b 39 00 00 00 00 00 11 b9 01 52 01 6f 01 88 01 b2 01 d5 02 0e 02 3e 02 40 39 00 00 00 00 00 11 ba 02 73 02 ad 02 d4 03 08 03 29 03 56 03 5e 03 6c 39 00 00 00 00 00 0d bb 03 7b 03 8d 03 a1 03 c2 03 c4 03 d7 15 01 00 00 00 00 02 ff 10];
		qcom,mdss-dsi-gamma18-command = [15 00 00 00 00 00 02 ff 20 15 00 00 00 00 00 02 fb 01 39 00 00 00 00 00 11 b0 01 00 01 08 01 12 01 1c 01 27 01 30 01 39 01 42 39 00 00 00 00 00 11 b1 01 4b 01 67 01 83 01 ac 01 cf 02 08 02 3b 02 3c 39 00 00 00 00 00 11 b2 02 6f 02 ab 02 d1 03 03 03 23 03 4d 03 59 03 67 39 00 00 00 00 00 0d b3 03 77 03 88 03 9f 03 b8 03 d4 03 d7 39 00 00 00 00 00 11 b4 00 00 00 1d 00 4b 00 6e 00 8a 00 a3 00 b9 00 cc 39 00 00 00 00 00 11 b5 00 dd 01 15 01 3e 01 7c 01 ab 01 f1 02 2b 02 2c 39 00 00 00 00 00 11 b6 02 61 02 9e 02 c6 02 fa 03 19 03 44 03 52 03 60 39 00 00 00 00 00 0d b7 03 6f 03 82 03 99 03 b6 03 d6 03 d7 39 00 00 00 00 00 11 b8 00 bd 00 ca 00 db 00 ea 00 f9 01 07 01 13 01 1e 39 00 00 00 00 00 11 b9 01 29 01 4f 01 6d 01 9e 01 c6 02 03 02 38 02 39 39 00 00 00 00 00 11 ba 02 6c 02 a9 02 d0 03 04 03 26 03 53 03 59 03 66 39 01 00 00 00 00 0d bb 03 76 03 88 03 a0 03 bd 03 be 03 d7 15 00 00 00 00 00 02 ff 21 15 00 00 00 00 00 02 fb 01 39 00 00 00 00 00 11 b0 01 00 01 08 01 12 01 1c 01 27 01 30 01 39 01 42 39 00 00 00 00 00 11 b1 01 4b 01 67 01 83 01 ac 01 cf 02 08 02 3b 02 3c 39 00 00 00 00 00 11 b2 02 6f 02 ab 02 d1 03 03 03 23 03 4d 03 59 03 67 39 00 00 00 00 00 0d b3 03 77 03 88 03 9f 03 b8 03 d4 03 d7 39 00 00 00 00 00 11 b4 00 00 00 1d 00 4b 00 6e 00 8a 00 a3 00 b9 00 cc 39 00 00 00 00 00 11 b5 00 dd 01 15 01 3e 01 7c 01 ab 01 f1 02 2b 02 2c 39 00 00 00 00 00 11 b6 02 61 02 9e 02 c6 02 fa 03 19 03 44 03 52 03 60 39 00 00 00 00 00 0d b7 03 6f 03 82 03 99 03 b6 03 d6 03 d7 39 00 00 00 00 00 11 b8 00 bd 00 ca 00 db 00 ea 00 f9 01 07 01 13 01 1e 39 00 00 00 00 00 11 b9 01 29 01 4f 01 6d 01 9e 01 c6 02 03 02 38 02 39 39 00 00 00 00 00 11 ba 02 6c 02 a9 02 d0 03 04 03 26 03 53 03 59 03 66 39 00 00 00 00 00 0d bb 03 76 03 88 03 a0 03 bd 03 be 03 d7 15 01 00 00 00 00 02 ff 10];
		qcom,mdss-dsi-gamma19-command = [15 00 00 00 00 00 02 ff 20 15 00 00 00 00 00 02 fb 01 39 00 00 00 00 00 11 b0 00 fb 01 00 01 0d 01 18 01 22 01 2c 01 35 01 3e 39 00 00 00 00 00 11 b1 01 46 01 64 01 7e 01 ae 01 cd 02 08 02 39 02 3b 39 00 00 00 00 00 11 b2 02 6d 02 a9 02 d0 03 03 03 23 03 4d 03 5a 03 68 39 00 00 00 00 00 0d b3 03 77 03 88 03 9f 03 be 03 ca 03 d7 39 00 00 00 00 00 11 b4 00 4d 00 60 00 7e 00 98 00 af 00 c3 00 d5 00 e5 39 00 00 00 00 00 11 b5 00 f4 01 25 01 4b 01 87 01 b2 01 f8 02 2d 02 2e 39 00 00 00 00 00 11 b6 02 65 02 9f 02 c7 02 fc 03 1c 03 46 03 54 03 61 39 00 00 00 00 00 0d b7 03 71 03 83 03 9a 03 b5 03 d5 03 d7 39 00 00 00 00 00 11 b8 00 00 00 27 00 58 00 7c 00 97 00 af 00 c4 00 d8 39 00 00 00 00 00 11 b9 00 e8 01 1e 01 46 01 86 01 b2 01 f7 02 2d 02 2f 39 00 00 00 00 00 11 ba 02 65 02 a1 02 c9 02 fd 03 1f 03 4e 03 56 03 64 39 01 00 00 00 00 0d bb 03 73 03 86 03 98 03 b7 03 d5 03 d7 15 00 00 00 00 00 02 ff 21 15 00 00 00 00 00 02 fb 01 39 00 00 00 00 00 11 b0 00 fb 01 00 01 0d 01 18 01 22 01 2c 01 35 01 3e 39 00 00 00 00 00 11 b1 01 46 01 64 01 7e 01 ae 01 cd 02 08 02 39 02 3b 39 00 00 00 00 00 11 b2 02 6d 02 a9 02 d0 03 03 03 23 03 4d 03 5a 03 68 39 00 00 00 00 00 0d b3 03 77 03 88 03 9f 03 be 03 ca 03 d7 39 00 00 00 00 00 11 b4 00 4d 00 60 00 7e 00 98 00 af 00 c3 00 d5 00 e5 39 00 00 00 00 00 11 b5 00 f4 01 25 01 4b 01 87 01 b2 01 f8 02 2d 02 2e 39 00 00 00 00 00 11 b6 02 65 02 9f 02 c7 02 fc 03 1c 03 46 03 54 03 61 39 00 00 00 00 00 0d b7 03 71 03 83 03 9a 03 b5 03 d5 03 d7 39 00 00 00 00 00 11 b8 00 00 00 27 00 58 00 7c 00 97 00 af 00 c4 00 d8 39 00 00 00 00 00 11 b9 00 e8 01 1e 01 46 01 86 01 b2 01 f7 02 2d 02 2f 39 00 00 00 00 00 11 ba 02 65 02 a1 02 c9 02 fd 03 1f 03 4e 03 56 03 64 39 00 00 00 00 00 0d bb 03 73 03 86 03 98 03 b7 03 d5 03 d7 15 01 00 00 00 00 02 ff 10];
		qcom,mdss-dsi-gamma20-command = [15 00 00 00 00 00 02 ff 20 15 00 00 00 00 00 02 fb 01 39 00 00 00 00 00 11 b0 00 a3 00 ae 00 c2 00 d1 00 e2 00 ef 00 fc 01 0e 39 00 00 00 00 00 11 b1 01 15 01 3e 01 5d 01 93 01 bc 01 fc 02 30 02 33 39 00 00 00 00 00 11 b2 02 66 02 a4 02 cc 02 fd 03 1e 03 49 03 57 03 64 39 00 00 00 00 00 0d b3 03 74 03 86 03 9c 03 b7 03 c5 03 d7 39 00 00 00 00 00 11 b4 00 a3 00 ae 00 c2 00 d4 00 e4 00 f2 01 00 01 0b 39 00 00 00 00 00 11 b5 01 17 01 41 01 60 01 96 01 bd 01 fd 02 32 02 33 39 00 00 00 00 00 11 b6 02 67 02 a2 02 cb 02 fc 03 1d 03 49 03 56 03 63 39 00 00 00 00 00 0d b7 03 73 03 84 03 9b 03 b6 03 d6 03 d7 39 00 00 00 00 00 11 b8 00 00 00 1b 00 5b 00 81 00 9e 00 b8 00 cc 00 de 39 00 00 00 00 00 11 b9 00 ed 01 21 01 46 01 86 01 b2 01 f6 02 2d 02 2e 39 00 00 00 00 00 11 ba 02 63 02 a0 02 c9 02 fb 03 1c 03 4d 03 56 03 64 39 01 00 00 00 00 0d bb 03 73 03 84 03 96 03 ad 03 d5 03 d7 15 00 00 00 00 00 02 ff 21 15 00 00 00 00 00 02 fb 01 39 00 00 00 00 00 11 b0 00 a3 00 ae 00 c2 00 d1 00 e2 00 ef 00 fc 01 0e 39 00 00 00 00 00 11 b1 01 15 01 3e 01 5d 01 93 01 bc 01 fc 02 30 02 33 39 00 00 00 00 00 11 b2 02 66 02 a4 02 cc 02 fd 03 1e 03 49 03 57 03 64 39 00 00 00 00 00 0d b3 03 74 03 86 03 9c 03 b7 03 c5 03 d7 39 00 00 00 00 00 11 b4 00 a3 00 ae 00 c2 00 d4 00 e4 00 f2 01 00 01 0b 39 00 00 00 00 00 11 b5 01 17 01 41 01 60 01 96 01 bd 01 fd 02 32 02 33 39 00 00 00 00 00 11 b6 02 67 02 a2 02 cb 02 fc 03 1d 03 49 03 56 03 63 39 00 00 00 00 00 0d b7 03 73 03 84 03 9b 03 b6 03 d6 03 d7 39 00 00 00 00 00 11 b8 00 00 00 1b 00 5b 00 81 00 9e 00 b8 00 cc 00 de 39 00 00 00 00 00 11 b9 00 ed 01 21 01 46 01 86 01 b2 01 f6 02 2d 02 2e 39 00 00 00 00 00 11 ba 02 63 02 a0 02 c9 02 fb 03 1c 03 4d 03 56 03 64 39 00 00 00 00 00 0d bb 03 73 03 84 03 96 03 ad 03 d5 03 d7 15 01 00 00 00 00 02 ff 10];
		qcom,mdss-dsi-gamma21-command = [15 00 00 00 00 00 02 ff 20 15 00 00 00 00 00 02 fb 01 39 00 00 00 00 00 11 b0 01 7e 01 83 01 87 01 8c 01 90 01 95 01 99 01 9e 39 00 00 00 00 00 11 b1 01 a3 01 b4 01 c6 01 e0 01 f8 02 26 02 51 02 53 39 00 00 00 00 00 11 b2 02 83 02 bb 02 e1 03 0f 03 31 03 59 03 65 03 72 39 00 00 00 00 00 0d b3 03 81 03 92 03 a8 03 c3 03 c9 03 d7 39 00 00 00 00 00 11 b4 00 00 00 13 00 45 00 6e 00 8e 00 a8 00 be 00 d0 39 00 00 00 00 00 11 b5 00 e1 01 16 01 40 01 80 01 ad 01 f5 02 2a 02 2b 39 00 00 00 00 00 11 b6 02 61 02 9e 02 c6 02 f8 03 19 03 45 03 53 03 61 39 00 00 00 00 00 0d b7 03 71 03 83 03 9b 03 b6 03 d6 03 d7 39 00 00 00 00 00 11 b8 01 07 01 0f 01 19 01 23 01 2e 01 36 01 3f 01 49 39 00 00 00 00 00 11 b9 01 50 01 6d 01 88 01 b1 01 d4 02 0e 02 3d 02 3f 39 00 00 00 00 00 11 ba 02 72 02 ac 02 d4 03 07 03 28 03 57 03 5d 03 6a 39 01 00 00 00 00 0d bb 03 79 03 8c 03 a2 03 bd 03 d3 03 d7 15 00 00 00 00 00 02 ff 21 15 00 00 00 00 00 02 fb 01 39 00 00 00 00 00 11 b0 01 7e 01 83 01 87 01 8c 01 90 01 95 01 99 01 9e 39 00 00 00 00 00 11 b1 01 a3 01 b4 01 c6 01 e0 01 f8 02 26 02 51 02 53 39 00 00 00 00 00 11 b2 02 83 02 bb 02 e1 03 0f 03 31 03 59 03 65 03 72 39 00 00 00 00 00 0d b3 03 81 03 92 03 a8 03 c3 03 c9 03 d7 39 00 00 00 00 00 11 b4 00 00 00 13 00 45 00 6e 00 8e 00 a8 00 be 00 d0 39 00 00 00 00 00 11 b5 00 e1 01 16 01 40 01 80 01 ad 01 f5 02 2a 02 2b 39 00 00 00 00 00 11 b6 02 61 02 9e 02 c6 02 f8 03 19 03 45 03 53 03 61 39 00 00 00 00 00 0d b7 03 71 03 83 03 9b 03 b6 03 d6 03 d7 39 00 00 00 00 00 11 b8 01 07 01 0f 01 19 01 23 01 2e 01 36 01 3f 01 49 39 00 00 00 00 00 11 b9 01 50 01 6d 01 88 01 b1 01 d4 02 0e 02 3d 02 3f 39 00 00 00 00 00 11 ba 02 72 02 ac 02 d4 03 07 03 28 03 57 03 5d 03 6a 39 00 00 00 00 00 0d bb 03 79 03 8c 03 a2 03 bd 03 d3 03 d7 15 01 00 00 00 00 02 ff 10];
		qcom,mdss-dsi-gamma22-command = [15 00 00 00 00 00 02 ff 20 15 00 00 00 00 00 02 fb 01 39 00 00 00 00 00 11 b0 01 5d 01 62 01 68 01 6d 01 73 01 79 01 7e 01 84 39 00 00 00 00 00 11 b1 01 89 01 9c 01 ae 01 cf 01 eb 02 1c 02 4a 02 4b 39 00 00 00 00 00 11 b2 02 7b 02 b5 02 dd 03 0f 03 2f 03 54 03 60 03 6d 39 00 00 00 00 00 0d b3 03 7c 03 8c 03 a2 03 bd 03 cb 03 d7 39 00 00 00 00 00 11 b4 00 00 00 1d 00 4b 00 6e 00 8b 00 a4 00 ba 00 cd 39 00 00 00 00 00 11 b5 00 df 01 17 01 40 01 7d 01 ab 01 f1 02 2a 02 2b 39 00 00 00 00 00 11 b6 02 5e 02 9d 02 c6 02 f8 03 19 03 45 03 52 03 60 39 00 00 00 00 00 0d b7 03 6f 03 81 03 97 03 b2 03 d6 03 d7 39 00 00 00 00 00 11 b8 00 c0 00 cd 00 db 00 ed 00 fc 01 09 01 17 01 23 39 00 00 00 00 00 11 b9 01 2c 01 51 01 6f 01 9f 01 c6 02 03 02 38 02 39 39 00 00 00 00 00 11 ba 02 6a 02 a8 02 d0 03 04 03 27 03 56 03 63 03 68 39 01 00 00 00 00 0d bb 03 81 03 8a 03 a6 03 c5 03 c9 03 d7 15 00 00 00 00 00 02 ff 21 15 00 00 00 00 00 02 fb 01 39 00 00 00 00 00 11 b0 01 5d 01 62 01 68 01 6d 01 73 01 79 01 7e 01 84 39 00 00 00 00 00 11 b1 01 89 01 9c 01 ae 01 cf 01 eb 02 1c 02 4a 02 4b 39 00 00 00 00 00 11 b2 02 7b 02 b5 02 dd 03 0f 03 2f 03 54 03 60 03 6d 39 00 00 00 00 00 0d b3 03 7c 03 8c 03 a2 03 bd 03 cb 03 d7 39 00 00 00 00 00 11 b4 00 00 00 1d 00 4b 00 6e 00 8b 00 a4 00 ba 00 cd 39 00 00 00 00 00 11 b5 00 df 01 17 01 40 01 7d 01 ab 01 f1 02 2a 02 2b 39 00 00 00 00 00 11 b6 02 5e 02 9d 02 c6 02 f8 03 19 03 45 03 52 03 60 39 00 00 00 00 00 0d b7 03 6f 03 81 03 97 03 b2 03 d6 03 d7 39 00 00 00 00 00 11 b8 00 c0 00 cd 00 db 00 ed 00 fc 01 09 01 17 01 23 39 00 00 00 00 00 11 b9 01 2c 01 51 01 6f 01 9f 01 c6 02 03 02 38 02 39 39 00 00 00 00 00 11 ba 02 6a 02 a8 02 d0 03 04 03 27 03 56 03 63 03 68 39 00 00 00 00 00 0d bb 03 81 03 8a 03 a6 03 c5 03 c9 03 d7 15 01 00 00 00 00 02 ff 10];
		qcom,mdss-dsi-gamma23-command = [15 00 00 00 00 00 02 ff 20 15 00 00 00 00 00 02 fb 01 39 00 00 00 00 00 11 b0 01 55 01 59 01 5f 01 66 01 6c 01 72 01 78 01 7d 39 00 00 00 00 00 11 b1 01 83 01 97 01 aa 01 ca 01 e7 02 1a 02 48 02 49 39 00 00 00 00 00 11 b2 02 7a 02 b3 02 d9 03 08 03 29 03 53 03 60 03 6e 39 00 00 00 00 00 0d b3 03 7e 03 93 03 b0 03 b7 03 d1 03 d7 39 00 00 00 00 00 11 b4 00 44 00 56 00 76 00 92 00 aa 00 bf 00 d2 00 e3 39 00 00 00 00 00 11 b5 00 f2 01 24 01 4a 01 84 01 b0 01 f4 02 2c 02 2d 39 00 00 00 00 00 11 b6 02 63 02 a3 02 c7 02 fb 03 1c 03 46 03 53 03 61 39 00 00 00 00 00 0d b7 03 72 03 87 03 9e 03 c0 03 d6 03 d7 39 00 00 00 00 00 11 b8 00 00 00 1e 00 54 00 6d 00 8e 00 ab 00 bf 00 d5 39 00 00 00 00 00 11 b9 00 e7 01 1e 01 47 01 84 01 b1 01 f7 02 2e 02 30 39 00 00 00 00 00 11 ba 02 65 02 a5 02 c9 02 fe 03 1f 03 51 03 58 03 65 39 01 00 00 00 00 0d bb 03 7a 03 8c 03 ab 03 cc 03 cd 03 d7 15 00 00 00 00 00 02 ff 21 15 00 00 00 00 00 02 fb 01 39 00 00 00 00 00 11 b0 01 55 01 59 01 5f 01 66 01 6c 01 72 01 78 01 7d 39 00 00 00 00 00 11 b1 01 83 01 97 01 aa 01 ca 01 e7 02 1a 02 48 02 49 39 00 00 00 00 00 11 b2 02 7a 02 b3 02 d9 03 08 03 29 03 53 03 60 03 6e 39 00 00 00 00 00 0d b3 03 7e 03 93 03 b0 03 b7 03 d1 03 d7 39 00 00 00 00 00 11 b4 00 44 00 56 00 76 00 92 00 aa 00 bf 00 d2 00 e3 39 00 00 00 00 00 11 b5 00 f2 01 24 01 4a 01 84 01 b0 01 f4 02 2c 02 2d 39 00 00 00 00 00 11 b6 02 63 02 a3 02 c7 02 fb 03 1c 03 46 03 53 03 61 39 00 00 00 00 00 0d b7 03 72 03 87 03 9e 03 c0 03 d6 03 d7 39 00 00 00 00 00 11 b8 00 00 00 1e 00 54 00 6d 00 8e 00 ab 00 bf 00 d5 39 00 00 00 00 00 11 b9 00 e7 01 1e 01 47 01 84 01 b1 01 f7 02 2e 02 30 39 00 00 00 00 00 11 ba 02 65 02 a5 02 c9 02 fe 03 1f 03 51 03 58 03 65 39 00 00 00 00 00 0d bb 03 7a 03 8c 03 ab 03 cc 03 cd 03 d7 15 01 00 00 00 00 02 ff 10];
		qcom,mdss-dsi-gamma24-command = [15 00 00 00 00 00 02 ff 20 15 00 00 00 00 00 02 fb 01 39 00 00 00 00 00 11 b0 01 55 01 59 01 5f 01 66 01 6c 01 72 01 78 01 7d 39 00 00 00 00 00 11 b1 01 83 01 97 01 aa 01 ca 01 e7 02 1a 02 48 02 49 39 00 00 00 00 00 11 b2 02 7a 02 b3 02 d9 03 08 03 29 03 53 03 60 03 6e 39 00 00 00 00 00 0d b3 03 7e 03 93 03 b0 03 b7 03 d1 03 d7 39 00 00 00 00 00 11 b4 00 44 00 56 00 76 00 92 00 aa 00 bf 00 d2 00 e3 39 00 00 00 00 00 11 b5 00 f2 01 24 01 4a 01 84 01 b0 01 f4 02 2c 02 2d 39 00 00 00 00 00 11 b6 02 63 02 a3 02 c7 02 fb 03 1c 03 46 03 53 03 61 39 00 00 00 00 00 0d b7 03 72 03 87 03 9e 03 c0 03 d6 03 d7 39 00 00 00 00 00 11 b8 00 00 00 1e 00 54 00 6d 00 8e 00 ab 00 bf 00 d5 39 00 00 00 00 00 11 b9 00 e7 01 1e 01 47 01 84 01 b1 01 f7 02 2e 02 30 39 00 00 00 00 00 11 ba 02 65 02 a5 02 c9 02 fe 03 1f 03 51 03 58 03 65 39 01 00 00 00 00 0d bb 03 7a 03 8c 03 ab 03 cc 03 cd 03 d7 15 00 00 00 00 00 02 ff 21 15 00 00 00 00 00 02 fb 01 39 00 00 00 00 00 11 b0 01 55 01 59 01 5f 01 66 01 6c 01 72 01 78 01 7d 39 00 00 00 00 00 11 b1 01 83 01 97 01 aa 01 ca 01 e7 02 1a 02 48 02 49 39 00 00 00 00 00 11 b2 02 7a 02 b3 02 d9 03 08 03 29 03 53 03 60 03 6e 39 00 00 00 00 00 0d b3 03 7e 03 93 03 b0 03 b7 03 d1 03 d7 39 00 00 00 00 00 11 b4 00 44 00 56 00 76 00 92 00 aa 00 bf 00 d2 00 e3 39 00 00 00 00 00 11 b5 00 f2 01 24 01 4a 01 84 01 b0 01 f4 02 2c 02 2d 39 00 00 00 00 00 11 b6 02 63 02 a3 02 c7 02 fb 03 1c 03 46 03 53 03 61 39 00 00 00 00 00 0d b7 03 72 03 87 03 9e 03 c0 03 d6 03 d7 39 00 00 00 00 00 11 b8 00 00 00 1e 00 54 00 6d 00 8e 00 ab 00 bf 00 d5 39 00 00 00 00 00 11 b9 00 e7 01 1e 01 47 01 84 01 b1 01 f7 02 2e 02 30 39 00 00 00 00 00 11 ba 02 65 02 a5 02 c9 02 fe 03 1f 03 51 03 58 03 65 39 00 00 00 00 00 0d bb 03 7a 03 8c 03 ab 03 cc 03 cd 03 d7 15 01 00 00 00 00 02 ff 10];
		qcom,mdss-dsi-on-command-state = "dsi_lp_mode";
		qcom,mdss-dsi-off-command-state = "dsi_hs_mode";
		qcom,mdss-dsi-ce-on-command-state = "dsi_hs_mode";
		qcom,mdss-dsi-ce-off-command-state = "dsi_hs_mode";
		qcom,mdss-dsi-srgb-on-command-state = "dsi_hs_mode";
		qcom,mdss-dsi-srgb-off-command-state = "dsi_hs_mode";
		qcom,mdss-dsi-cabc-on-command-state = "dsi_hs_mode";
		qcom,mdss-dsi-cabc-off-command-state = "dsi_hs_mode";
		qcom,mdss-dsi-gamma-command-state = "dsi_hs_mode";
		qcom,mdss-dsi-bl-pmic-control-type = "bl_ctrl_wled";
		qcom,mdss-dsi-reset-sequence = <1 1>, <0 5>, <1 15>;
		qcom,mdss-dsi-tx-eot-append;
		qcom,mdss-dsi-post-init-delay = <1>;
		qcom,esd-check-enabled;
		qcom,mdss-dsi-panel-status-command = [06 01 00 01 05 00 01 0A];
		qcom,mdss-dsi-panel-status-command-state = "dsi_hs_mode";
		qcom,mdss-dsi-panel-status-check-mode = "reg_read";
		qcom,mdss-dsi-panel-status-read-length = <1>;
		qcom,mdss-dsi-panel-status-value = <0x9c>;
		qcom,mdss-dsi-panel-max-error-count = <3>;
		qcom,mdss-dsi-panel-timings-phy-v2 = [25 1f 09 0a 06 03 04 a0 25 1f 09 0a 06 03 04 a0 25 1f 09 0a 06 03 04 a0 25 1f 09 0a 06 03 04 a0 25 1e 08 0a 06 03 04 a0];
		qcom,mdss-dsi-min-refresh-rate = <48>;
		qcom,mdss-dsi-max-refresh-rate = <60>;
		qcom,panel-supply-entries = <&dsi_panel_pwr_supply>;
	};
	dsi_nt36672_jdi_fhd_video: qcom,mdss_dsi_nt36672_jdi_fhd_video {
		qcom,mdss-dsi-panel-name = "jdi nt36672 fhd video mode dsi panel";
		qcom,mdss-dsi-panel-controller = <&mdss_dsi0>;
		qcom,mdss-dsi-panel-type = "dsi_video_mode";
		qcom,mdss-dsi-panel-framerate = <60>;
		qcom,mdss-dsi-virtual-channel-id = <0>;
		qcom,mdss-dsi-stream = <0>;
		qcom,mdss-dsi-panel-width = <1080>;
		qcom,mdss-dsi-panel-height = <2160>;
		qcom,mdss-pan-physical-width-dimension = <68>;
		qcom,mdss-pan-physical-height-dimension = <136>;
		qcom,mdss-dsi-h-front-porch = <96>;
		qcom,mdss-dsi-h-back-porch = <56>;
		qcom,mdss-dsi-h-pulse-width = <4>;
		qcom,mdss-dsi-h-sync-skew = <0>;
		qcom,mdss-dsi-v-back-porch = <33>;
		qcom,mdss-dsi-v-front-porch = <4>;
		qcom,mdss-dsi-v-pulse-width = <2>;
		qcom,mdss-dsi-h-left-border = <0>;
		qcom,mdss-dsi-h-right-border = <0>;
		qcom,mdss-dsi-v-top-border = <0>;
		qcom,mdss-dsi-v-bottom-border = <0>;
		qcom,mdss-dsi-bpp = <24>;
		qcom,mdss-dsi-underflow-color = <0xff>;
		qcom,mdss-dsi-border-color = <0>;
		qcom,mdss-dsi-h-sync-pulse = <0>;
		qcom,mdss-dsi-traffic-mode = "burst_mode";
		qcom,mdss-dsi-bllp-eof-power-mode;
		qcom,mdss-dsi-bllp-power-mode;
		qcom,mdss-dsi-lane-0-state;
		qcom,mdss-dsi-lane-1-state;
		qcom,mdss-dsi-lane-2-state;
		qcom,mdss-dsi-lane-3-state;
		qcom,mdss-dsi-panel-timings = [e6 38 26 00 68 6e 2a 3c 44 03 04 00];
		qcom,mdss-dsi-t-clk-post = <0x0d>;
		qcom,mdss-dsi-t-clk-pre = <0x32>;
		qcom,mdss-dsi-bl-min-level = <1>;
		qcom,mdss-dsi-bl-max-level = <4095>;
		qcom,mdss-brightness-max-level = <4095>;
		qcom,mdss-dsi-dma-trigger = "trigger_sw";
		qcom,mdss-dsi-mdp-trigger = "none";
		qcom,mdss-dsi-on-command = [ 15 01 00 00 00 00 02 ff 20 15 01 00 00 00 00 02 fb 01 15 01 00 00 00 00 02 30 10 15 01 00 00 00 00 02 31 50 15 01 00 00 00 00 02 32 2f 15 01 00 00 00 00 02 ff 10 05 01 00 00 46 00 02 11 00 15 01 00 00 00 00 02 51 ff 39 01 00 00 00 00 03 68 03 04 15 01 00 00 00 00 02 53 2c 15 01 00 00 00 00 02 55 00 05 01 00 00 14 00 02 29 00 ];
		qcom,mdss-dsi-off-command = [ 05 01 00 00 14 00 02 28 00 05 01 00 00 78 00 02 10 00 ];
		qcom,mdss-dsi-ce-on-command = [ ];
		qcom,mdss-dsi-ce-off-command = [ ];
		qcom,mdss-dsi-srgb-on-command = [ ];
		qcom,mdss-dsi-srgb-off-command = [ ];
		qcom,mdss-dsi-cabc-on-command = [ 15 01 00 00 00 00 02 FF 23 15 00 00 00 00 00 02 07 20 15 00 00 00 00 00 02 08 05 15 00 00 00 00 00 02 09 00 15 00 00 00 00 00 02 10 95 15 00 00 00 00 00 02 30 FF 15 00 00 00 00 00 02 31 FF 15 00 00 00 00 00 02 32 FF 15 00 00 00 00 00 02 33 FF 15 00 00 00 00 00 02 34 FF 15 01 00 00 00 00 02 35 FF 15 00 00 00 00 00 02 36 FF 15 00 00 00 00 00 02 37 FF 15 00 00 00 00 00 02 38 FF 15 00 00 00 00 00 02 39 FF 15 00 00 00 00 00 02 3A FF 15 00 00 00 00 00 02 3B F9 15 00 00 00 00 00 02 3D D9 15 00 00 00 00 00 02 3F B9 15 00 00 00 00 00 02 40 AB 15 00 00 00 00 00 02 41 98 15 01 00 00 00 00 02 FF 10 15 01 00 00 00 00 02 55 01 ];
		qcom,mdss-dsi-cabc-off-command = [ 15 01 00 00 00 00 02 FF 10 15 01 00 00 00 00 02 55 00 ];
		qcom,mdss-dsi-gamma0-command = [ ];
		qcom,mdss-dsi-gamma1-command = [ ];
		qcom,mdss-dsi-gamma2-command = [ ];
		qcom,mdss-dsi-gamma3-command = [ ];
		qcom,mdss-dsi-gamma4-command = [ ];
		qcom,mdss-dsi-gamma5-command = [ ];
		qcom,mdss-dsi-gamma6-command = [ ];
		qcom,mdss-dsi-gamma7-command = [ ];
		qcom,mdss-dsi-gamma8-command = [ ];
		qcom,mdss-dsi-gamma9-command = [ ];
		qcom,mdss-dsi-gamma10-command = [ ];
		qcom,mdss-dsi-gamma11-command = [ ];
		qcom,mdss-dsi-gamma12-command = [ ];
		qcom,mdss-dsi-gamma13-command = [ ];
		qcom,mdss-dsi-gamma14-command = [ ];
		qcom,mdss-dsi-gamma15-command = [ ];
		qcom,mdss-dsi-gamma16-command = [ ];
		qcom,mdss-dsi-gamma17-command = [ ];
		qcom,mdss-dsi-gamma18-command = [ ];
		qcom,mdss-dsi-gamma19-command = [ ];
		qcom,mdss-dsi-gamma20-command = [ ];
		qcom,mdss-dsi-gamma21-command = [ ];
		qcom,mdss-dsi-gamma22-command = [ ];
		qcom,mdss-dsi-gamma23-command = [ ];
		qcom,mdss-dsi-gamma24-command = [ ];
		qcom,mdss-dsi-on-command-state = "dsi_lp_mode";
		qcom,mdss-dsi-off-command-state = "dsi_hs_mode";
		qcom,mdss-dsi-ce-on-command-state = "dsi_hs_mode";
		qcom,mdss-dsi-ce-off-command-state = "dsi_hs_mode";
		qcom,mdss-dsi-srgb-on-command-state = "dsi_hs_mode";
		qcom,mdss-dsi-srgb-off-command-state = "dsi_hs_mode";
		qcom,mdss-dsi-cabc-on-command-state = "dsi_hs_mode";
		qcom,mdss-dsi-cabc-off-command-state = "dsi_hs_mode";
		qcom,mdss-dsi-gamma-command-state = "dsi_hs_mode";
		qcom,mdss-dsi-bl-pmic-control-type = "bl_ctrl_wled";
		qcom,mdss-dsi-reset-sequence = <1 1>, <0 5>, <1 15>;
		qcom,mdss-dsi-tx-eot-append;
		qcom,mdss-dsi-post-init-delay = <1>;
		qcom,esd-check-enabled;
		qcom,mdss-dsi-panel-status-command = [06 01 00 01 05 00 01 0A];
		qcom,mdss-dsi-panel-status-command-state = "dsi_hs_mode";
		qcom,mdss-dsi-panel-status-check-mode = "reg_read";
		qcom,mdss-dsi-panel-status-read-length = <1>;
		qcom,mdss-dsi-panel-status-value = <0x9c>;
		qcom,mdss-dsi-panel-max-error-count = <3>;
		qcom,mdss-dsi-panel-timings-phy-v2 = [25 1f 09 0a 06 03 04 a0 25 1f 09 0a 06 03 04 a0 25 1f 09 0a 06 03 04 a0 25 1f 09 0a 06 03 04 a0 25 1e 08 0a 06 03 04 a0];
		qcom,mdss-dsi-min-refresh-rate = <48>;
		qcom,mdss-dsi-max-refresh-rate = <60>;
		qcom,panel-supply-entries = <&dsi_panel_pwr_supply>;
	};
	dsi_nt36672a_tianma_fhdplus_video: qcom,mdss_dsi_nt36672a_tianma_fhdplus_video {
		qcom,mdss-dsi-panel-name = "tianma nt36672a fhdplus video mode dsi panel";
		qcom,mdss-dsi-panel-controller = <&mdss_dsi0>;
		qcom,mdss-dsi-panel-type = "dsi_video_mode";
		qcom,mdss-dsi-panel-framerate = <60>;
		qcom,mdss-dsi-virtual-channel-id = <0>;
		qcom,mdss-dsi-stream = <0>;
		qcom,mdss-dsi-panel-width = <1080>;
		qcom,mdss-dsi-panel-height = <2340>;
		qcom,mdss-pan-physical-width-dimension = <67>;
		qcom,mdss-pan-physical-height-dimension = <145>;
		qcom,mdss-dsi-h-front-porch = <90>;
		qcom,mdss-dsi-h-back-porch = <120>;
		qcom,mdss-dsi-h-pulse-width = <2>;
		qcom,mdss-dsi-h-sync-skew = <0>;
		qcom,mdss-dsi-v-back-porch = <8>;
		qcom,mdss-dsi-v-front-porch = <10>;
		qcom,mdss-dsi-v-pulse-width = <3>;
		qcom,mdss-dsi-h-left-border = <0>;
		qcom,mdss-dsi-h-right-border = <0>;
		qcom,mdss-dsi-v-top-border = <0>;
		qcom,mdss-dsi-v-bottom-border = <0>;
		qcom,mdss-dsi-bpp = <24>;
		qcom,mdss-dsi-underflow-color = <0xff>;
		qcom,mdss-dsi-border-color = <0>;
		qcom,mdss-dsi-h-sync-pulse = <0>;
		qcom,mdss-dsi-traffic-mode = "burst_mode";
		qcom,mdss-dsi-bllp-eof-power-mode;
		qcom,mdss-dsi-bllp-power-mode;
		qcom,mdss-dsi-lane-0-state;
		qcom,mdss-dsi-lane-1-state;
		qcom,mdss-dsi-lane-2-state;
		qcom,mdss-dsi-lane-3-state;
		qcom,mdss-dsi-panel-timings = [fe 3c 2a 00 70 74 2e 40 30 03 04 00];
		qcom,mdss-dsi-t-clk-post = <0x0e>;
		qcom,mdss-dsi-t-clk-pre = <0x37>;
		qcom,mdss-dsi-bl-min-level = <1>;
		qcom,mdss-dsi-bl-max-level = <4095>;
		qcom,mdss-brightness-max-level = <4095>;
		qcom,mdss-dsi-dma-trigger = "trigger_sw";
		qcom,mdss-dsi-mdp-trigger = "none";
		qcom,mdss-dsi-on-command = [ 15 01 00 00 00 00 02 ff 25 15 01 00 00 00 00 02 fb 01 15 01 00 00 00 00 02 18 96 15 01 00 00 00 00 02 05 04 15 01 00 00 00 00 02 ff 20 15 01 00 00 00 00 02 fb 01 15 01 00 00 00 00 02 78 01 15 01 00 00 00 00 02 ff 24 15 01 00 00 00 00 02 fb 01 15 01 00 00 00 00 02 82 13 15 01 00 00 00 00 02 84 31 15 01 00 00 00 00 02 88 13 15 01 00 00 00 00 02 8a 31 15 01 00 00 00 00 02 8e e4 15 01 00 00 00 00 02 8f 01 15 01 00 00 00 00 02 90 80 15 01 00 00 00 00 02 ff 26 15 01 00 00 00 00 02 fb 01 15 01 00 00 00 00 02 a9 12 15 01 00 00 00 00 02 aa 10 15 01 00 00 00 00 02 ae 8a 15 01 00 00 00 00 02 ff 10 15 01 00 00 50 00 02 11 00 15 01 00 00 00 00 02 b0 01 15 01 00 00 00 00 02 35 00 39 01 00 00 00 00 03 68 03 04 15 01 00 00 00 00 02 51 ff 15 01 00 00 00 00 02 53 2c 15 01 00 00 00 00 02 55 00 15 01 00 00 00 00 02 29 00 ];
		qcom,mdss-dsi-off-command = [ 15 01 00 00 14 00 02 28 00 15 01 00 00 78 00 02 10 00 ];
		qcom,mdss-dsi-ce-on-command = [ ];
		qcom,mdss-dsi-ce-off-command = [ ];
		qcom,mdss-dsi-srgb-on-command;
		qcom,mdss-dsi-srgb-off-command;
		qcom,mdss-dsi-cabc-on-command = [15 01 00 00 00 00 02 ff 23 15 00 00 00 00 00 02 fb 01 15 00 00 00 00 00 02 01 84 15 00 00 00 00 00 02 05 04 15 00 00 00 00 00 02 05 2d 15 00 00 00 00 00 02 06 00 15 00 00 00 00 00 02 07 60 15 00 00 00 00 00 02 11 01 15 00 00 00 00 00 02 12 8a 15 00 00 00 00 00 02 15 6a 15 00 00 00 00 00 02 16 0b 15 00 00 00 00 00 02 19 00 15 00 00 00 00 00 02 1a 04 15 00 00 00 00 00 02 1b 08 15 00 00 00 00 00 02 1c 0c 15 00 00 00 00 00 02 1d 10 15 00 00 00 00 00 02 1e 2a 15 00 00 00 00 00 02 1f 3f 15 00 00 00 00 00 02 20 3f 15 00 00 00 00 00 02 21 30 15 01 00 00 00 00 02 22 2e 15 00 00 00 00 00 02 23 30 15 00 00 00 00 00 02 24 37 15 00 00 00 00 00 02 25 38 15 00 00 00 00 00 02 26 2c 15 00 00 00 00 00 02 27 24 15 00 00 00 00 00 02 28 28 15 00 00 00 00 00 02 29 80 15 00 00 00 00 00 02 30 fd 15 00 00 00 00 00 02 31 fc 15 00 00 00 00 00 02 32 f8 15 00 00 00 00 00 02 33 f6 15 00 00 00 00 00 02 34 f5 15 00 00 00 00 00 02 35 f4 15 00 00 00 00 00 02 36 f3 15 00 00 00 00 00 02 37 f3 15 00 00 00 00 00 02 38 f2 15 00 00 00 00 00 02 39 f0 15 00 00 00 00 00 02 3a ee 15 00 00 00 00 00 02 3b ec 15 01 00 00 00 00 02 3d ea 15 00 00 00 00 00 02 3f e8 15 00 00 00 00 00 02 40 e6 15 00 00 00 00 00 02 41 e5 15 00 00 00 00 00 02 ff 10 15 00 00 00 00 00 02 fb 01 15 01 00 00 00 00 02 55 01];
		qcom,mdss-dsi-cabc-off-command = [15 01 00 00 00 00 02 ff 10 15 01 00 00 00 00 02 55 00];
		qcom,mdss-dsi-cabc-movie-on-command = [15 01 00 00 00 00 02 ff 23 15 00 00 00 00 00 02 fb 01 15 00 00 00 00 00 02 01 84 15 00 00 00 00 00 02 05 04 15 00 00 00 00 00 02 05 2d 15 00 00 00 00 00 02 06 00 15 00 00 00 00 00 02 07 60 15 00 00 00 00 00 02 11 01 15 00 00 00 00 00 02 12 8a 15 00 00 00 00 00 02 15 6a 15 01 00 00 00 00 02 16 0b 15 00 00 00 00 00 02 19 00 15 00 00 00 00 00 02 1a 04 15 00 00 00 00 00 02 1b 08 15 00 00 00 00 00 02 1c 0c 15 00 00 00 00 00 02 1d 10 15 00 00 00 00 00 02 1e 2a 15 00 00 00 00 00 02 1f 3f 15 00 00 00 00 00 02 20 3f 15 00 00 00 00 00 02 21 30 15 01 00 00 00 00 02 22 2e 15 00 00 00 00 00 02 23 30 15 00 00 00 00 00 02 24 37 15 00 00 00 00 00 02 25 38 15 00 00 00 00 00 02 26 2c 15 00 00 00 00 00 02 27 24 15 00 00 00 00 00 02 28 28 15 00 00 00 00 00 02 2b 87 15 00 00 00 00 00 02 58 e4 15 00 00 00 00 00 02 59 e4 15 01 00 00 00 00 02 5a e4 15 00 00 00 00 00 02 5b e4 15 00 00 00 00 00 02 5c e4 15 00 00 00 00 00 02 5d e4 15 00 00 00 00 00 02 5e df 15 00 00 00 00 00 02 5f da 15 00 00 00 00 00 02 60 d7 15 00 00 00 00 00 02 61 d0 15 00 00 00 00 00 02 62 cd 15 00 00 00 00 00 02 63 ca 15 01 00 00 00 00 02 64 c8 15 00 00 00 00 00 02 65 c1 15 00 00 00 00 00 02 66 bb 15 01 00 00 00 00 02 67 b3 15 01 00 00 00 00 02 ff 10 15 00 00 00 00 00 02 fb 01 15 01 00 00 00 00 02 55 03];
		qcom,mdss-dsi-cabc-still-on-command = [15 01 00 00 00 00 02 ff 23 15 00 00 00 00 00 02 fb 01 15 00 00 00 00 00 02 01 84 15 00 00 00 00 00 02 05 04 15 00 00 00 00 00 02 05 2d 15 00 00 00 00 00 02 06 00 15 00 00 00 00 00 02 07 60 15 00 00 00 00 00 02 11 01 15 00 00 00 00 00 02 12 8a 15 00 00 00 00 00 02 15 6a 15 01 00 00 00 00 02 16 0b 15 00 00 00 00 00 02 19 00 15 00 00 00 00 00 02 1a 04 15 00 00 00 00 00 02 1b 08 15 00 00 00 00 00 02 1c 0c 15 00 00 00 00 00 02 1d 10 15 00 00 00 00 00 02 1e 2a 15 00 00 00 00 00 02 1f 3f 15 00 00 00 00 00 02 20 3f 15 00 00 00 00 00 02 21 30 15 01 00 00 00 00 02 22 2e 15 00 00 00 00 00 02 23 30 15 00 00 00 00 00 02 24 37 15 00 00 00 00 00 02 25 38 15 00 00 00 00 00 02 26 2c 15 00 00 00 00 00 02 27 24 15 00 00 00 00 00 02 28 28 15 00 00 00 00 00 02 2a 3f 15 00 00 00 00 00 02 45 e4 15 00 00 00 00 00 02 46 e4 15 01 00 00 00 00 02 47 e4 15 00 00 00 00 00 02 48 e4 15 00 00 00 00 00 02 49 e4 15 00 00 00 00 00 02 4a e4 15 00 00 00 00 00 02 4b d0 15 00 00 00 00 00 02 4c b2 15 00 00 00 00 00 02 4d af 15 00 00 00 00 00 02 4e aa 15 00 00 00 00 00 02 4f a4 15 00 00 00 00 00 02 50 9a 15 01 00 00 00 00 02 51 90 15 00 00 00 00 00 02 52 85 15 00 00 00 00 00 02 53 7a 15 01 00 00 00 00 02 54 66 15 01 00 00 00 00 02 ff 10 15 00 00 00 00 00 02 fb 01 15 01 00 00 00 00 02 55 02];
		qcom,mdss-dsi-hbm1-on-command = [15 01 00 00 00 00 02 51 cc];
		qcom,mdss-dsi-hbm2-on-command = [15 01 00 00 00 00 02 51 e6];
		qcom,mdss-dsi-hbm3-on-command = [15 01 00 00 00 00 02 51 ff];
		qcom,mdss-dsi-hbm-off-command = [15 01 00 00 00 00 02 51 b8];
		qcom,mdss-dsi-gamma0-command = [ ];
		qcom,mdss-dsi-gamma1-command = [ ];
		qcom,mdss-dsi-gamma2-command = [ ];
		qcom,mdss-dsi-gamma3-command = [ ];
		qcom,mdss-dsi-gamma4-command = [ ];
		qcom,mdss-dsi-gamma5-command = [ ];
		qcom,mdss-dsi-gamma6-command = [ ];
		qcom,mdss-dsi-gamma7-command = [ ];
		qcom,mdss-dsi-gamma8-command = [ ];
		qcom,mdss-dsi-gamma9-command = [ ];
		qcom,mdss-dsi-gamma10-command = [ ];
		qcom,mdss-dsi-gamma11-command = [ ];
		qcom,mdss-dsi-gamma12-command = [ ];
		qcom,mdss-dsi-gamma13-command = [ ];
		qcom,mdss-dsi-gamma14-command = [ ];
		qcom,mdss-dsi-gamma15-command = [ ];
		qcom,mdss-dsi-gamma16-command = [ ];
		qcom,mdss-dsi-gamma17-command = [ ];
		qcom,mdss-dsi-gamma18-command = [ ];
		qcom,mdss-dsi-gamma19-command = [ ];
		qcom,mdss-dsi-gamma20-command = [ ];
		qcom,mdss-dsi-gamma21-command = [ ];
		qcom,mdss-dsi-gamma22-command = [ ];
		qcom,mdss-dsi-gamma23-command = [ ];
		qcom,mdss-dsi-gamma24-command = [ ];
		qcom,mdss-dsi-on-command-state = "dsi_lp_mode";
		qcom,mdss-dsi-off-command-state = "dsi_hs_mode";
		qcom,mdss-dsi-ce-on-command-state = "dsi_hs_mode";
		qcom,mdss-dsi-ce-off-command-state = "dsi_hs_mode";
		qcom,mdss-dsi-srgb-on-command-state = "dsi_hs_mode";
		qcom,mdss-dsi-srgb-off-command-state = "dsi_hs_mode";
		qcom,mdss-dsi-cabc-on-command-state = "dsi_hs_mode";
		qcom,mdss-dsi-cabc-off-command-state = "dsi_hs_mode";
		qcom,mdss-dsi-cabc-movie-on-command-state = "dsi_hs_mode";
		qcom,mdss-dsi-cabc-still-on-command-state = "dsi_hs_mode";
		qcom,mdss-dsi-gamma-command-state = "dsi_hs_mode";
		qcom,mdss-dsi-hbm1-on-command-state = "dsi_hs_mode";
		qcom,mdss-dsi-hbm2-on-command-state = "dsi_hs_mode";
		qcom,mdss-dsi-hbm3-on-command-state = "dsi_hs_mode";
		qcom,mdss-dsi-hbm-off-command-state = "dsi_hs_mode";
		qcom,mdss-dsi-bl-pmic-control-type = "bl_ctrl_wled";
		qcom,mdss-dsi-reset-sequence = <1 1>, <0 5>, <1 15>;
		qcom,mdss-dsi-tx-eot-append;
		qcom,mdss-dsi-post-init-delay = <1>;
		qcom,esd-check-enabled;
		qcom,mdss-dsi-panel-status-command = [06 01 00 01 05 00 01 0A];
		qcom,mdss-dsi-panel-status-command-state = "dsi_hs_mode";
		qcom,mdss-dsi-panel-status-check-mode = "reg_read";
		qcom,mdss-dsi-panel-status-read-length = <1>;
		qcom,mdss-dsi-panel-status-value = <0x9c>;
		qcom,mdss-dsi-panel-max-error-count = <3>;
		qcom,mdss-dsi-panel-timings-phy-v2 = [26 21 09 0b 06 03 04 a0 26 21 09 0b 06 03 04 a0 26 21 09 0b 06 03 04 a0 26 21 09 0b 06 03 04 a0 26 20 0a 0b 06 03 04 a0];
		qcom,mdss-dsi-min-refresh-rate = <48>;
		qcom,mdss-dsi-max-refresh-rate = <60>;
		qcom,panel-supply-entries = <&dsi_panel_pwr_supply>;
	};
	dsi_nt36672a_shenchao_fhdplus_video: qcom,mdss_dsi_nt36672a_shenchao_fhdplus_video {
		qcom,mdss-dsi-panel-name = "shenchao nt36672a fhdplus video mode dsi panel";
		qcom,mdss-dsi-panel-controller = <&mdss_dsi0>;
		qcom,mdss-dsi-panel-type = "dsi_video_mode";
		qcom,mdss-dsi-panel-framerate = <60>;
		qcom,mdss-dsi-virtual-channel-id = <0>;
		qcom,mdss-dsi-stream = <0>;
		qcom,mdss-dsi-panel-width = <1080>;
		qcom,mdss-dsi-panel-height = <2340>;
		qcom,mdss-pan-physical-width-dimension = <67>;
		qcom,mdss-pan-physical-height-dimension = <145>;
		qcom,mdss-dsi-h-front-porch = <90>;
		qcom,mdss-dsi-h-back-porch = <120>;
		qcom,mdss-dsi-h-pulse-width = <2>;
		qcom,mdss-dsi-h-sync-skew = <0>;
		qcom,mdss-dsi-v-back-porch = <8>;
		qcom,mdss-dsi-v-front-porch = <10>;
		qcom,mdss-dsi-v-pulse-width = <3>;
		qcom,mdss-dsi-h-left-border = <0>;
		qcom,mdss-dsi-h-right-border = <0>;
		qcom,mdss-dsi-v-top-border = <0>;
		qcom,mdss-dsi-v-bottom-border = <0>;
		qcom,mdss-dsi-bpp = <24>;
		qcom,mdss-dsi-underflow-color = <0xff>;
		qcom,mdss-dsi-border-color = <0>;
		qcom,mdss-dsi-h-sync-pulse = <0>;
		qcom,mdss-dsi-traffic-mode = "burst_mode";
		qcom,mdss-dsi-bllp-eof-power-mode;
		qcom,mdss-dsi-bllp-power-mode;
		qcom,mdss-dsi-lane-0-state;
		qcom,mdss-dsi-lane-1-state;
		qcom,mdss-dsi-lane-2-state;
		qcom,mdss-dsi-lane-3-state;
		qcom,mdss-dsi-panel-timings = [fe 3c 2a 00 70 74 2e 40 30 03 04 00];
		qcom,mdss-dsi-t-clk-post = <0x0e>;
		qcom,mdss-dsi-t-clk-pre = <0x37>;
		qcom,mdss-dsi-bl-min-level = <1>;
		qcom,mdss-dsi-bl-max-level = <4095>;
		qcom,mdss-brightness-max-level = <4095>;
		qcom,mdss-dsi-dma-trigger = "trigger_sw";
		qcom,mdss-dsi-mdp-trigger = "none";
		qcom,mdss-dsi-on-command = <0x15010000 0x000002ff 0x25150100 0x00000002 0xfb011501 0x00000000 0x02189615 0x01000000 0x00020504 0x15010000 0x000002ff 0x27150100 0x00000002 0xfb011501 0x00000000 0x02d91015 0x01000000 0x0002ff24 0x15010000 0x000002fb 0x01150100 0x00000002 0x82131501 0x00000000 0x02843115 0x01000000 0x00028813 0x15010000 0x0000028a 0x31150100 0x00000002 0x8ee41501 0x00000000 0x028f0115 0x01000000 0x00029080 0x15010000 0x0000029d 0xb0150100 0x00000002 0xff261501 0x00000000 0x02fb0115 0x01000000 0x0002a912 0x15010000 0x000002aa 0x10150100 0x00000002 0xae8a1501 0x00000000 0x021cfa15 0x01000000 0x0002ff10 0x15010000 0x000002b0 0x01050100 0x00460002 0x11001501 0x00000000 0x0251b839 0x01000000 0x00036803 0x04150100 0x00000002 0x532c1501 0x00000000 0x02550005 0x01000000 0x00022900>;
		qcom,mdss-dsi-off-command = [15 01 00 00 14 00 02 28 00 15 01 00 00 78 00 02 10 00];
		qcom,mdss-dsi-ce-on-command;
		qcom,mdss-dsi-ce-off-command;
		qcom,mdss-dsi-srgb-on-command;
		qcom,mdss-dsi-srgb-off-command;
		qcom,mdss-dsi-cabc-on-command = [15 01 00 00 00 00 02 ff 23 15 00 00 00 00 00 02 fb 01 15 00 00 00 00 00 02 01 84 15 00 00 00 00 00 02 05 04 15 00 00 00 00 00 02 05 2d 15 00 00 00 00 00 02 06 00 15 00 00 00 00 00 02 07 60 15 00 00 00 00 00 02 11 01 15 00 00 00 00 00 02 12 8a 15 00 00 00 00 00 02 15 6a 15 00 00 00 00 00 02 16 0b 15 00 00 00 00 00 02 19 00 15 00 00 00 00 00 02 1a 04 15 00 00 00 00 00 02 1b 08 15 00 00 00 00 00 02 1c 0c 15 00 00 00 00 00 02 1d 10 15 00 00 00 00 00 02 1e 2a 15 00 00 00 00 00 02 1f 3f 15 00 00 00 00 00 02 20 3f 15 00 00 00 00 00 02 21 30 15 01 00 00 00 00 02 22 2e 15 00 00 00 00 00 02 23 30 15 00 00 00 00 00 02 24 37 15 00 00 00 00 00 02 25 38 15 00 00 00 00 00 02 26 2c 15 00 00 00 00 00 02 27 24 15 00 00 00 00 00 02 28 28 15 00 00 00 00 00 02 29 80 15 00 00 00 00 00 02 30 fd 15 00 00 00 00 00 02 31 fc 15 00 00 00 00 00 02 32 f8 15 00 00 00 00 00 02 33 f6 15 00 00 00 00 00 02 34 f5 15 00 00 00 00 00 02 35 f4 15 00 00 00 00 00 02 36 f3 15 00 00 00 00 00 02 37 f3 15 00 00 00 00 00 02 38 f2 15 00 00 00 00 00 02 39 f0 15 00 00 00 00 00 02 3a ee 15 00 00 00 00 00 02 3b ec 15 01 00 00 00 00 02 3d ea 15 00 00 00 00 00 02 3f e8 15 00 00 00 00 00 02 40 e6 15 00 00 00 00 00 02 41 e5 15 00 00 00 00 00 02 ff 10 15 00 00 00 00 00 02 fb 01 15 01 00 00 00 00 02 55 01];
		qcom,mdss-dsi-cabc-off-command = [15 01 00 00 00 00 02 ff 10 15 01 00 00 00 00 02 55 00];
		qcom,mdss-dsi-cabc-movie-on-command = [15 01 00 00 00 00 02 ff 23 15 00 00 00 00 00 02 fb 01 15 00 00 00 00 00 02 01 84 15 00 00 00 00 00 02 05 04 15 00 00 00 00 00 02 05 2d 15 00 00 00 00 00 02 06 00 15 00 00 00 00 00 02 07 60 15 00 00 00 00 00 02 11 01 15 00 00 00 00 00 02 12 8a 15 00 00 00 00 00 02 15 6a 15 01 00 00 00 00 02 16 0b 15 00 00 00 00 00 02 19 00 15 00 00 00 00 00 02 1a 04 15 00 00 00 00 00 02 1b 08 15 00 00 00 00 00 02 1c 0c 15 00 00 00 00 00 02 1d 10 15 00 00 00 00 00 02 1e 2a 15 00 00 00 00 00 02 1f 3f 15 00 00 00 00 00 02 20 3f 15 00 00 00 00 00 02 21 30 15 01 00 00 00 00 02 22 2e 15 00 00 00 00 00 02 23 30 15 00 00 00 00 00 02 24 37 15 00 00 00 00 00 02 25 38 15 00 00 00 00 00 02 26 2c 15 00 00 00 00 00 02 27 24 15 00 00 00 00 00 02 28 28 15 00 00 00 00 00 02 2b 87 15 00 00 00 00 00 02 58 e4 15 00 00 00 00 00 02 59 e4 15 01 00 00 00 00 02 5a e4 15 00 00 00 00 00 02 5b e4 15 00 00 00 00 00 02 5c e4 15 00 00 00 00 00 02 5d e4 15 00 00 00 00 00 02 5e df 15 00 00 00 00 00 02 5f da 15 00 00 00 00 00 02 60 d7 15 00 00 00 00 00 02 61 d0 15 00 00 00 00 00 02 62 cd 15 00 00 00 00 00 02 63 ca 15 01 00 00 00 00 02 64 c8 15 00 00 00 00 00 02 65 c1 15 00 00 00 00 00 02 66 bb 15 01 00 00 00 00 02 67 b3 15 01 00 00 00 00 02 ff 10 15 00 00 00 00 00 02 fb 01 15 01 00 00 00 00 02 55 03];
		qcom,mdss-dsi-cabc-still-on-command = [15 01 00 00 00 00 02 ff 23 15 00 00 00 00 00 02 fb 01 15 00 00 00 00 00 02 01 84 15 00 00 00 00 00 02 05 04 15 00 00 00 00 00 02 05 2d 15 00 00 00 00 00 02 06 00 15 00 00 00 00 00 02 07 60 15 00 00 00 00 00 02 11 01 15 00 00 00 00 00 02 12 8a 15 00 00 00 00 00 02 15 6a 15 01 00 00 00 00 02 16 0b 15 00 00 00 00 00 02 19 00 15 00 00 00 00 00 02 1a 04 15 00 00 00 00 00 02 1b 08 15 00 00 00 00 00 02 1c 0c 15 00 00 00 00 00 02 1d 10 15 00 00 00 00 00 02 1e 2a 15 00 00 00 00 00 02 1f 3f 15 00 00 00 00 00 02 20 3f 15 00 00 00 00 00 02 21 30 15 01 00 00 00 00 02 22 2e 15 00 00 00 00 00 02 23 30 15 00 00 00 00 00 02 24 37 15 00 00 00 00 00 02 25 38 15 00 00 00 00 00 02 26 2c 15 00 00 00 00 00 02 27 24 15 00 00 00 00 00 02 28 28 15 00 00 00 00 00 02 2a 3f 15 00 00 00 00 00 02 45 e4 15 00 00 00 00 00 02 46 e4 15 01 00 00 00 00 02 47 e4 15 00 00 00 00 00 02 48 e4 15 00 00 00 00 00 02 49 e4 15 00 00 00 00 00 02 4a e4 15 00 00 00 00 00 02 4b d0 15 00 00 00 00 00 02 4c b2 15 00 00 00 00 00 02 4d af 15 00 00 00 00 00 02 4e aa 15 00 00 00 00 00 02 4f a4 15 00 00 00 00 00 02 50 9a 15 01 00 00 00 00 02 51 90 15 00 00 00 00 00 02 52 85 15 00 00 00 00 00 02 53 7a 15 01 00 00 00 00 02 54 66 15 01 00 00 00 00 02 ff 10 15 00 00 00 00 00 02 fb 01 15 01 00 00 00 00 02 55 02];
		qcom,mdss-dsi-hbm1-on-command = [15 01 00 00 00 00 02 51 cc];
		qcom,mdss-dsi-hbm2-on-command = [15 01 00 00 00 00 02 51 e6];
		qcom,mdss-dsi-hbm3-on-command = [15 01 00 00 00 00 02 51 ff];
		qcom,mdss-dsi-hbm-off-command = [15 01 00 00 00 00 02 51 b8];
		qcom,mdss-dsi-gamma0-command = [ ];
		qcom,mdss-dsi-gamma1-command = [ ];
		qcom,mdss-dsi-gamma2-command = [ ];
		qcom,mdss-dsi-gamma3-command = [ ];
		qcom,mdss-dsi-gamma4-command = [ ];
		qcom,mdss-dsi-gamma5-command = [ ];
		qcom,mdss-dsi-gamma6-command = [ ];
		qcom,mdss-dsi-gamma7-command = [ ];
		qcom,mdss-dsi-gamma8-command = [ ];
		qcom,mdss-dsi-gamma9-command = [ ];
		qcom,mdss-dsi-gamma10-command = [ ];
		qcom,mdss-dsi-gamma11-command = [ ];
		qcom,mdss-dsi-gamma12-command = [ ];
		qcom,mdss-dsi-gamma13-command = [ ];
		qcom,mdss-dsi-gamma14-command = [ ];
		qcom,mdss-dsi-gamma15-command = [ ];
		qcom,mdss-dsi-gamma16-command = [ ];
		qcom,mdss-dsi-gamma17-command = [ ];
		qcom,mdss-dsi-gamma18-command = [ ];
		qcom,mdss-dsi-gamma19-command = [ ];
		qcom,mdss-dsi-gamma20-command = [ ];
		qcom,mdss-dsi-gamma21-command = [ ];
		qcom,mdss-dsi-gamma22-command = [ ];
		qcom,mdss-dsi-gamma23-command = [ ];
		qcom,mdss-dsi-gamma24-command = [ ];
		qcom,mdss-dsi-on-command-state = "dsi_lp_mode";
		qcom,mdss-dsi-off-command-state = "dsi_hs_mode";
		qcom,mdss-dsi-ce-on-command-state = "dsi_hs_mode";
		qcom,mdss-dsi-ce-off-command-state = "dsi_hs_mode";
		qcom,mdss-dsi-srgb-on-command-state = "dsi_hs_mode";
		qcom,mdss-dsi-srgb-off-command-state = "dsi_hs_mode";
		qcom,mdss-dsi-cabc-on-command-state = "dsi_hs_mode";
		qcom,mdss-dsi-cabc-off-command-state = "dsi_hs_mode";
		qcom,mdss-dsi-cabc-movie-on-command-state = "dsi_hs_mode";
		qcom,mdss-dsi-cabc-still-on-command-state = "dsi_hs_mode";
		qcom,mdss-dsi-gamma-command-state = "dsi_hs_mode";
		qcom,mdss-dsi-hbm1-on-command-state = "dsi_hs_mode";
		qcom,mdss-dsi-hbm2-on-command-state = "dsi_hs_mode";
		qcom,mdss-dsi-hbm3-on-command-state = "dsi_hs_mode";
		qcom,mdss-dsi-hbm-off-command-state = "dsi_hs_mode";
		qcom,mdss-dsi-bl-pmic-control-type = "bl_ctrl_wled";
		qcom,mdss-dsi-reset-sequence = <1 1>, <0 5>, <1 15>;
		qcom,mdss-dsi-tx-eot-append;
		qcom,mdss-dsi-post-init-delay = <1>;
		qcom,esd-check-enabled;
		qcom,mdss-dsi-panel-status-command = [06 01 00 01 05 00 01 0A];
		qcom,mdss-dsi-panel-status-command-state = "dsi_hs_mode";
		qcom,mdss-dsi-panel-status-check-mode = "reg_read";
		qcom,mdss-dsi-panel-status-read-length = <1>;
		qcom,mdss-dsi-panel-status-value = <0x9c>;
		qcom,mdss-dsi-panel-max-error-count = <3>;
		qcom,mdss-dsi-panel-timings-phy-v2 = [26 21 09 0b 06 03 04 a0 26 21 09 0b 06 03 04 a0 26 21 09 0b 06 03 04 a0 26 21 09 0b 06 03 04 a0 26 20 0a 0b 06 03 04 a0];
		qcom,mdss-dsi-min-refresh-rate = <48>;
		qcom,mdss-dsi-max-refresh-rate = <60>;
	};
	dsi_td4320_boe_fhdplus_video: qcom,mdss_dsi_td4320_boe_fhdplus_video {
		qcom,mdss-dsi-panel-name = "boe td4320 fhdplus video mode dsi panel";
		qcom,mdss-dsi-panel-controller = <&mdss_dsi0>;
		qcom,mdss-dsi-panel-type = "dsi_video_mode";
		qcom,mdss-dsi-panel-framerate = <60>;
		qcom,mdss-dsi-virtual-channel-id = <0>;
		qcom,mdss-dsi-stream = <0>;
		qcom,mdss-dsi-panel-width = <1080>;
		qcom,mdss-dsi-panel-height = <2340>;
		qcom,mdss-pan-physical-width-dimension = <67>;
		qcom,mdss-pan-physical-height-dimension = <145>;
		qcom,mdss-dsi-h-front-porch = <86>;
		qcom,mdss-dsi-h-back-porch = <100>;
		qcom,mdss-dsi-h-pulse-width = <2>;
		qcom,mdss-dsi-h-sync-skew = <0>;
		qcom,mdss-dsi-v-back-porch = <60>;
		qcom,mdss-dsi-v-front-porch = <4>;
		qcom,mdss-dsi-v-pulse-width = <4>;
		qcom,mdss-dsi-h-left-border = <0>;
		qcom,mdss-dsi-h-right-border = <0>;
		qcom,mdss-dsi-v-top-border = <0>;
		qcom,mdss-dsi-v-bottom-border = <0>;
		qcom,mdss-dsi-bpp = <24>;
		qcom,mdss-dsi-underflow-color = <0xff>;
		qcom,mdss-dsi-border-color = <0>;
		qcom,mdss-dsi-h-sync-pulse = <0>;
		qcom,mdss-dsi-traffic-mode = "burst_mode";
		qcom,mdss-dsi-bllp-eof-power-mode;
		qcom,mdss-dsi-bllp-power-mode;
		qcom,mdss-dsi-lane-0-state;
		qcom,mdss-dsi-lane-1-state;
		qcom,mdss-dsi-lane-2-state;
		qcom,mdss-dsi-lane-3-state;
		qcom,mdss-dsi-panel-timings = [fe 3c 2a 00 70 74 2e 40 30 03 04 00];
		qcom,mdss-dsi-t-clk-post = <0x0e>;
		qcom,mdss-dsi-t-clk-pre = <0x37>;
		qcom,mdss-dsi-bl-min-level = <1>;
		qcom,mdss-dsi-bl-max-level = <4095>;
		qcom,mdss-brightness-max-level = <4095>;
		qcom,mdss-dsi-dma-trigger = "trigger_sw";
		qcom,mdss-dsi-mdp-trigger = "none";
		qcom,mdss-dsi-on-command = [29 01 00 00 00 00 02 b0 04 29 01 00 00 00 00 02 d6 00 29 01 00 00 00 00 08 b8 19 55 00 be 00 00 00 29 01 00 00 00 00 08 b9 4d 55 05 e6 00 02 03 29 01 00 00 00 00 08 ba 9b 5b 07 e6 00 13 00 29 01 00 00 00 00 06 f9 44 3f 00 8d bf 29 01 00 00 00 00 22 ce 5d 00 0f 1f 2f 3f 4f 5f 6f 7f 8f 9f af bf cf df ef ff 04 00 02 02 42 01 69 5a 40 40 00 00 04 fa 00 15 01 00 00 00 00 02 51 b8 15 01 00 00 00 00 02 53 2c 15 01 00 00 00 00 02 55 00 15 01 00 00 00 00 02 b0 03 39 01 00 00 60 00 02 11 00 39 01 00 00 14 00 02 29 00];
		qcom,mdss-dsi-off-command = [15 01 00 00 14 00 02 28 00 15 01 00 00 78 00 02 10 00];
		qcom,mdss-dsi-ce-on-command;
		qcom,mdss-dsi-ce-off-command;
		qcom,mdss-dsi-srgb-on-command;
		qcom,mdss-dsi-srgb-off-command;
		qcom,mdss-dsi-cabc-on-command = [15 01 00 00 00 00 02 55 81];
		qcom,mdss-dsi-cabc-off-command = [15 01 00 00 00 00 02 55 00];
		qcom,mdss-dsi-cabc-movie-on-command = [15 01 00 00 00 00 02 55 82];
		qcom,mdss-dsi-cabc-still-on-command = [15 01 00 00 00 00 02 55 83];
		qcom,mdss-dsi-hbm1-on-command = [15 01 00 00 00 00 02 51 cc];
		qcom,mdss-dsi-hbm2-on-command = [15 01 00 00 00 00 02 51 e6];
		qcom,mdss-dsi-hbm3-on-command = [15 01 00 00 00 00 02 51 ff];
		qcom,mdss-dsi-hbm-off-command = [15 01 00 00 00 00 02 51 b8];
		qcom,mdss-dsi-gamma0-command = [ ];
		qcom,mdss-dsi-gamma1-command = [ ];
		qcom,mdss-dsi-gamma2-command = [ ];
		qcom,mdss-dsi-gamma3-command = [ ];
		qcom,mdss-dsi-gamma4-command = [ ];
		qcom,mdss-dsi-gamma5-command = [ ];
		qcom,mdss-dsi-gamma6-command = [ ];
		qcom,mdss-dsi-gamma7-command = [ ];
		qcom,mdss-dsi-gamma8-command = [ ];
		qcom,mdss-dsi-gamma9-command = [ ];
		qcom,mdss-dsi-gamma10-command = [ ];
		qcom,mdss-dsi-gamma11-command = [ ];
		qcom,mdss-dsi-gamma12-command = [ ];
		qcom,mdss-dsi-gamma13-command = [ ];
		qcom,mdss-dsi-gamma14-command = [ ];
		qcom,mdss-dsi-gamma15-command = [ ];
		qcom,mdss-dsi-gamma16-command = [ ];
		qcom,mdss-dsi-gamma17-command = [ ];
		qcom,mdss-dsi-gamma18-command = [ ];
		qcom,mdss-dsi-gamma19-command = [ ];
		qcom,mdss-dsi-gamma20-command = [ ];
		qcom,mdss-dsi-gamma21-command = [ ];
		qcom,mdss-dsi-gamma22-command = [ ];
		qcom,mdss-dsi-gamma23-command = [ ];
		qcom,mdss-dsi-gamma24-command = [ ];
		qcom,mdss-dsi-on-command-state = "dsi_lp_mode";
		qcom,mdss-dsi-off-command-state = "dsi_hs_mode";
		qcom,mdss-dsi-ce-on-command-state = "dsi_hs_mode";
		qcom,mdss-dsi-ce-off-command-state = "dsi_hs_mode";
		qcom,mdss-dsi-srgb-on-command-state = "dsi_hs_mode";
		qcom,mdss-dsi-srgb-off-command-state = "dsi_hs_mode";
		qcom,mdss-dsi-cabc-on-command-state = "dsi_hs_mode";
		qcom,mdss-dsi-cabc-off-command-state = "dsi_hs_mode";
		qcom,mdss-dsi-cabc-movie-on-command-state = "dsi_hs_mode";
		qcom,mdss-dsi-cabc-still-on-command-state = "dsi_hs_mode";
		qcom,mdss-dsi-gamma-command-state = "dsi_hs_mode";
		qcom,mdss-dsi-hbm1-on-command-state = "dsi_hs_mode";
		qcom,mdss-dsi-hbm2-on-command-state = "dsi_hs_mode";
		qcom,mdss-dsi-hbm3-on-command-state = "dsi_hs_mode";
		qcom,mdss-dsi-hbm-off-command-state = "dsi_hs_mode";
		qcom,mdss-dsi-bl-pmic-control-type = "bl_ctrl_wled";
		qcom,mdss-dsi-reset-sequence = <1 1>, <0 5>, <1 30>;
		qcom,mdss-dsi-tx-eot-append;
		qcom,mdss-dsi-post-init-delay = <1>;
		qcom,esd-check-enabled;
		qcom,mdss-dsi-panel-status-command = [06 01 00 01 05 00 01 0A];
		qcom,mdss-dsi-panel-status-command-state = "dsi_hs_mode";
		qcom,mdss-dsi-panel-status-check-mode = "reg_read";
		qcom,mdss-dsi-panel-status-read-length = <1>;
		qcom,mdss-dsi-panel-status-value = <0x1c>;
		qcom,mdss-dsi-panel-max-error-count = <3>;
		qcom,mdss-dsi-panel-timings-phy-v2 = [26 21 09 0b 06 03 04 a0 26 21 09 0b 06 03 04 a0 26 21 09 0b 06 03 04 a0 26 21 09 0b 06 03 04 a0 26 20 0a 0b 06 03 04 a0];
		qcom,mdss-dsi-min-refresh-rate = <48>;
		qcom,mdss-dsi-max-refresh-rate = <60>;
		qcom,panel-supply-entries = <&dsi_panel_pwr_supply>;
	};
};
&dsi_panel_pwr_supply {
	qcom,panel-supply-entry@0 {
		qcom,supply-post-on-sleep = <2>;
		qcom,supply-pre-off-sleep = <10>;
	};
	qcom,panel-supply-entry@1 {
		qcom,supply-pre-on-sleep = <8>;
	};
	qcom,panel-supply-entry@2 {
		qcom,supply-pre-on-sleep = <8>;
	};
};
&cam_avdd_gpio_regulator {
	regulator-min-microvolt = <2800000>;
	regulator-max-microvolt = <2800000>;
};
&cam_rear_dvdd_gpio_regulator {
	regulator-min-microvolt = <1200000>;
	regulator-max-microvolt = <1200000>;
};
&actuator0 {
	gpios = <&tlmm 45 0>;
	qcom,gpio-vaf = <0>;
	qcom,gpio-req-tbl-num = <0>;
	qcom,gpio-req-tbl-flags = <0>;
	qcom,gpio-req-tbl-label = "CAM_VAF";
	pinctrl-names = "cam_default", "cam_suspend";
	pinctrl-0 = <&cam_actuator_vaf_active0>;
	pinctrl-1 = <&cam_actuator_vaf_suspend0>;
	/delete-property/ cam_vaf-supply;
	/delete-property/ qcom,cam-vreg-name;
	/delete-property/ qcom,cam-vreg-min-voltage;
	/delete-property/ qcom,cam-vreg-max-voltage;
	/delete-property/ qcom,cam-vreg-op-mode;
};
&actuator1 {
	gpios = <&tlmm 50 0>;
	qcom,gpio-vaf = <0>;
	qcom,gpio-req-tbl-num = <0>;
	qcom,gpio-req-tbl-flags = <0>;
	qcom,gpio-req-tbl-label = "CAM_VAF";
	pinctrl-names = "cam_default", "cam_suspend";
	pinctrl-0 = <&cam_actuator_vaf_active>;
	pinctrl-1 = <&cam_actuator_vaf_suspend>;
	/delete-property/ cam_vaf-supply;
	/delete-property/ qcom,cam-vreg-name;
	/delete-property/ qcom,cam-vreg-min-voltage;
	/delete-property/ qcom,cam-vreg-max-voltage;
	/delete-property/ qcom,cam-vreg-op-mode;
};
&eeprom0 {
	reg = <0x0>;
	qcom,i2c-freq-mode = <1>;
	qcom,slave-addr = <0xB0>;
	qcom,num-blocks = <1>;
	qcom,page0 = <0 0x0000 2 0x00 1 0>;
	qcom,poll0 = <0 0x0 2 0x0 1 0>;
	qcom,mem0 = <7158 0x0000 2 0x0 1 0>;
	cam_vana-supply = <&cam_rear_avdd_gpio_regulator>;
	cam_vdig-supply = <&cam_dvdd_gpio_regulator>;
	pinctrl-0 = <&cam_sensor_mclk0_active &cam_sensor_rear2_active>;
	pinctrl-1 = <&cam_sensor_mclk0_suspend &cam_sensor_rear2_suspend>;
	gpios = <&tlmm 32 0>, <&tlmm 48 0>, <&tlmm 45 0>;
	qcom,cam-power-seq-type = "sensor_gpio","sensor_vreg","sensor_vreg","sensor_vreg","sensor_gpio", "sensor_clk","sensor_gpio";
	qcom,cam-power-seq-val = "sensor_gpio_reset","cam_vana", "cam_vdig","cam_vio","sensor_gpio_vaf", "sensor_cam_mclk","sensor_gpio_reset";
	qcom,cam-power-seq-cfg-val = <0 1 1 1 1 24000000 1>;
	qcom,cam-power-seq-delay = <1 1 1 1 1 1 10>;
	clocks = <&clock_mmss MCLK0_CLK_SRC>, <&clock_mmss MMSS_CAMSS_MCLK0_CLK>;
};
&eeprom1 {
	qcom,i2c-freq-mode = <1>;
	qcom,slave-addr = <0xA0>;
	qcom,num-blocks = <1>;
	qcom,page0 = <0 0x0000 2 0x00 1 0>;
	qcom,poll0 = <0 0x0 2 0x0 1 0>;
	qcom,mem0 = <7158 0x0000 2 0x0 1 0>;
	cam_vdig-supply = <&cam_rear_dvdd_gpio_regulator>;
	pinctrl-0 = <&cam_sensor_mclk3_active &cam_sensor_front_iris_active>;
	pinctrl-1 = <&cam_sensor_mclk3_suspend &cam_sensor_front_iris_suspend>;
	gpios = <&tlmm 35 0>, <&tlmm 52 0>, <&tlmm 50 0>;
	qcom,gpio-vaf = <2>;
	qcom,gpio-req-tbl-num = <0 1 2>;
	qcom,gpio-req-tbl-flags = <1 0 0>;
	qcom,gpio-req-tbl-label = "CAMIF_MCLK3", "CAM_RESET3", "CAM_VAF";
	qcom,cam-power-seq-type = "sensor_gpio","sensor_vreg","sensor_vreg","sensor_vreg","sensor_gpio", "sensor_clk","sensor_gpio";
	qcom,cam-power-seq-val = "sensor_gpio_reset","cam_vana", "cam_vdig","cam_vio","sensor_gpio_vaf", "sensor_cam_mclk","sensor_gpio_reset";
	qcom,cam-power-seq-cfg-val = <0 1 1 1 1 24000000 1>;
	qcom,cam-power-seq-delay = <1 1 1 1 1 1 10>;
	clocks = <&clock_mmss MCLK3_CLK_SRC>, <&clock_mmss MMSS_CAMSS_MCLK3_CLK>;
};
&eeprom2 {
	qcom,i2c-freq-mode = <1>;
	qcom,slave-addr = <0xA2>;
	qcom,num-blocks = <1>;
	qcom,page0 = <0 0x0000 2 0x00 1 0>;
	qcom,poll0 = <0 0x0 2 0x0 1 0>;
	qcom,mem0 = <6390 0x0000 2 0x0 1 0>;
	cam_vana-supply = <&cam_rear_avdd_gpio_regulator>;
	qcom,cam-vreg-min-voltage = <1780000 0 0>;
	qcom,cam-vreg-max-voltage = <1950000 0 0>;
	qcom,cam-vreg-op-mode = <105000 0 0>;
	pinctrl-0 = <&cam_sensor_mclk1_active &cam_sensor_front_active>;
	pinctrl-1 = <&cam_sensor_mclk1_suspend &cam_sensor_front_suspend>;
	gpios = <&tlmm 33 0>, <&tlmm 47 0>;
	qcom,gpio-req-tbl-num = <0 1>;
	qcom,gpio-req-tbl-flags = <1 0>;
	qcom,gpio-req-tbl-label = "CAMIF_MCLK1", "CAM_RESET1";
	qcom,cam-power-seq-type = "sensor_gpio","sensor_vreg","sensor_vreg","sensor_vreg", "sensor_clk","sensor_gpio";
	qcom,cam-power-seq-val = "sensor_gpio_reset","cam_vana", "cam_vdig","cam_vio", "sensor_cam_mclk","sensor_gpio_reset";
	qcom,cam-power-seq-cfg-val = <0 1 1 1 24000000 1>;
	qcom,cam-power-seq-delay = <1 1 1 1 1 10>;
	qcom,sensor-position = <0>;
	/delete-property/ qcom,gpio-vana;
	/delete-property/ qcom,gpio-vaf;
};
&cci {
	qcom,camera@0 {
		cam_vana-supply = <&cam_rear_avdd_gpio_regulator>;
		cam_vdig-supply = <&cam_dvdd_gpio_regulator>;
		pinctrl-0 = <&cam_sensor_mclk0_active &cam_sensor_rear2_active>;
		pinctrl-1 = <&cam_sensor_mclk0_suspend &cam_sensor_rear2_suspend>;
		gpios = <&tlmm 32 0>, <&tlmm 48 0>, <&tlmm 45 0>;
		qcom,gpio-vaf = <2>;
		qcom,gpio-req-tbl-num = <0 1 2>;
		qcom,gpio-req-tbl-flags = <1 0 0>;
		qcom,gpio-req-tbl-label = "CAMIF_MCLK0", "CAM_RESET0", "CAM_VAF";
		/delete-property/ qcom,ois-src;
	};
};
&cci {
	qcom,camera@1 {
		qcom,csid-sd-index = <1>;
		cam_vdig-supply = <&cam_rear_dvdd_gpio_regulator>;
		pinctrl-0 = <&cam_sensor_mclk3_active &cam_sensor_front_iris_active>;
		pinctrl-1 = <&cam_sensor_mclk3_suspend &cam_sensor_front_iris_suspend>;
		gpios = <&tlmm 35 0>, <&tlmm 52 0>, <&tlmm 50 0>;
		qcom,gpio-vaf = <2>;
		qcom,gpio-req-tbl-num = <0 1 2>;
		qcom,gpio-req-tbl-flags = <1 0 0>;
		qcom,gpio-req-tbl-label = "CAMIF_MCLK3", "CAM_RESET3", "CAM_VAF";
		clocks = <&clock_mmss MCLK3_CLK_SRC>, <&clock_mmss MMSS_CAMSS_MCLK3_CLK>;
	};
};
&cci {
	qcom,camera@2 {
		qcom,mount-angle = <270>;
		qcom,led-flash-src = <&led_flash1>;
		cam_vana-supply = <&cam_rear_avdd_gpio_regulator>;
		qcom,gpio-req-tbl-label = "CAMIF_MCLK1", "CAM_RESET1";
		/delete-property/ qcom,actuator-src;
	};
};
&mtp_batterydata {
	qcom,l8866sun_3000mah {
		qcom, = <24>;
		qcom,max-voltage-uv = <4400000>;
		qcom,fastchg-current-ma = <2900>;
		qcom,fg-cc-cv-threshold-mv = <4390>;
		qcom,nom-batt-capacity-mah = <3000>;
		qcom,batt-id-kohm = <68>;
		qcom,battery-beta = <0xd34>;
		qcom,battery-full-design = <0xbc2>;
		qcom,battery-type = "3797504_lc_d2s_sunwoda_3000mah_fg_averaged_masterslave_jan11th2019";
		qcom,checksum = <0x11f>;
		qcom,gui-version = "PM660GUI - 0.0.0.45";
		qcom,fg-profile-data = <0x4f1fe405 0x460afdfc 0xde1cfc01 0xb30da90a 0xbb17fa23 0x2244935a 0x72000000 0x10000000 0x000057c4 0x0fbc58ca 0x26000800 0x12e26aed 0x0dfc3801 0xda0dfc02 0x81dc4223 0x36060920 0x27001400 0xdb1f6405 0xaf0a0e06 0xc11c0803 0xec154812 0x8418d423 0xe84d2c5b 0x69000000 0x0e000000 0x0000e9d5 0xb7ba93ca 0x1c000000 0x13f26aed 0xf806abeb 0x77dc1903 0x2ef26d1b 0xad33ccff 0x07100000 0x850b6646 0x1c004000 0xac010afa 0xff000000 0x00000000 0x00000000 0x00000000 0x00000000 0x00000000 0x00000000 0x00000000 0x00000000 0x00000000 0x00000000 0x00000000 0x00000000 0x00000000 0x00000000 0x00000000 0x00000000 0x00000000 0x00000000>;
	};
	qcom,l8866cos_3000mah {
		qcom, = <24>;
		qcom,max-voltage-uv = <4400000>;
		qcom,fastchg-current-ma = <2900>;
		qcom,fg-cc-cv-threshold-mv = <4390>;
		qcom,nom-batt-capacity-mah = <3000>;
		qcom,batt-id-kohm = <100>;
		qcom,battery-beta = <0xd34>;
		qcom,battery-full-design = <0xbc2>;
		qcom,battery-type = "3797542_lc_d2s_coslight_3000mah_fg_averaged_masterslave_jan11th2019";
		qcom,checksum = <0xc544>;
		qcom,gui-version = "PM660GUI - 0.0.0.45";
		qcom,fg-profile-data = <0xf61f3705 0xb10a2b06 0xf71c9701 0xdd04b203 0xc017c823 0x87442d5a 0x83000000 0x11000000 0x0000eeac 0xeacd27b2 0x29000800 0x44da11e5 0x4205ce01 0xe90cfbf5 0xf0d45923 0x3c060920 0x27001400 0x25201505 0xde0aed05 0xc91cde02 0x390c0612 0x8318d723 0xe54d315b 0x6f000000 0x0e000000 0x0000d8d5 0x00a446d2 0x1b000000 0x5fea11e5 0x82061ef3 0xfbe44e0a 0x39035f22 0xbd33ccff 0x07100000 0x760b6646 0x1b004000 0xca010afa 0xff000000 0x00000000 0x00000000 0x00000000 0x00000000 0x00000000 0x00000000 0x00000000 0x00000000 0x00000000 0x00000000 0x00000000 0x00000000 0x00000000 0x00000000 0x00000000 0x00000000 0x00000000 0x00000000>;
	};
	qcom,l8866default_3000mah {
		qcom, = <0x00000018>;
		qcom,max-voltage-uv = <4400000>;
		qcom,fastchg-current-ma = <2900>;
		qcom,fg-cc-cv-threshold-mv = <4390>;
		qcom,nom-batt-capacity-mah = <3000>;
		qcom,batt-id-kohm = <666>;
		qcom,battery-beta = <0xd6b>;
		qcom,battery-full-design = <0xbc2>;
		qcom,battery-type = "unknown-default";
		qcom,checksum = <0xee03>;
		qcom,gui-version = "PM660GUI - 0.0.0.45";
		qcom,fg-profile-data = <0xcc1f5905 0xaf0a35fc 0xee1cc501 0x45042c0a 0xd417f023 0x29448e5a 0x7c000000 0x10000000 0x0000bdcd 0xcacd05d2 0x22000800 0x8fe299ed 0x65fc0901 0x83f3c013 0x77d3202a 0x28060920 0x27001400 0xf01f4105 0xd10ae805 0xc61cf602 0xfb153a12 0x9118cb23 0xed4d255b 0x6a000000 0x0e000000 0x00004ecc 0xa4c227b2 0x19000000 0x87eb99ed 0xe606f5eb 0xcd0617fb 0x2dfc7d1a 0x9933ccff 0x07100000 0x800b6646 0x19004000 0xa8010afa 0xff000000 0x00000000 0x00000000 0x00000000 0x00000000 0x00000000 0x00000000 0x00000000 0x00000000 0x00000000 0x00000000 0x00000000 0x00000000 0x00000000 0x00000000 0x00000000 0x00000000 0x00000000 0x00000000>;
	};
	/delete-node/ qcom,itech_3000mah;
	/delete-node/ qcom,ascent_3450mah;
};
&i2c_6 {
	tas2557@4c {
		compatible = "ti,tas2557";
		reg = <0x4c>;
		#ti,load = <0>;
		#ti,channel = <0>;
		i2c-pull-up;
		vdd-supply = <&pm660l_l6>;
		vcc_i2c-supply = <&pm660l_l6>;
		ti,cdc-reset-gpio = <&tlmm 77 0>;
		ti,irq-gpio = <&tlmm 73 0>;
		ti,i2s-bits = <16>;
		status = "ok";
	};
	max98927@3a {
		compatible = "maxim,max98927L";
		status = "okay";
		reg = <0x3a>;
		mono_stereo_mode = <0>;
		interleave_mode = <0>;
		maxim,98927-reset-gpio = <&tlmm 77 0>;
	};
	tfa98xx@34 {
		compatible = "nxp,tfa98xx";
		reg = <0x34>;
		i2c-pull-up;
		vdd-supply = <&pm660l_l6>;
		vcc_i2c-supply = <&pm660l_l6>;
		reset-gpio = <&tlmm 77 0>;
		irq-gpio = <&tlmm 73 0>;
		status = "ok";
	};
};
&cdc_pdm_gpios {
	/delete-property/ status;
};
&cdc_comp_gpios {
	/delete-property/ status;
};
&cdc_dmic_gpios {
	/delete-property/ status;
};
&cdc_sdw_gpios {
	/delete-property/ pinctrl-names;
	/delete-property/ pinctrl-0;
	/delete-property/ pinctrl-1;
	/delete-property/ status;
};
&wsa_spkr_en1 {
	/delete-property/ pinctrl-names;
	/delete-property/ pinctrl-0;
	/delete-property/ pinctrl-1;
	/delete-property/ status;
};
&wsa_spkr_en2 {
	/delete-property/ pinctrl-names;
	/delete-property/ pinctrl-0;
	/delete-property/ pinctrl-1;
	/delete-property/ status;
};
&mdss_dsi1 {
	/delete-property/ qcom,dsi-pref-prim-pan;
	/delete-property/ pinctrl-names;
	/delete-property/ pinctrl-0;
	/delete-property/ pinctrl-1;
	/delete-property/ qcom,platform-reset-gpio;
	/delete-property/ qcom,platform-te-gpio;
};
&cci {
	/delete-node/ qcom,actuator@2;
	/delete-node/ qcom,ois@0;
	/delete-node/ qcom,tof@29;
	/delete-node/ qcom,camera@3;
};
